VERSION "dbc-export 1 2025.20.8"

NS_ :

BS_:

BU_: ADSP APB APP APS APSB BB BMS CC CMP CP DAS DI DIF DIR DPB EPAS3P EPAS3S EPASTP EPASTS EPBL EPBR ESP GTW HVP IBST ICR IDB OCS1P PCS PM PMF PMR PTC RCM RCM2 RCU SCCM SDCR TAS TCU TRCM UI UIS UMC USM VC VCFRONT VCLEFT VCRIGHT VCSEC

BO_ 528 CP_status: 8 CP
 SG_ CP_type : 0|2@1+ (1,0) [0|3] "" Vector__XXX
 SG_ CP_insertEnableLine : 2|1@1+ (1,0) [0|1] "" Vector__XXX
 SG_ CP_latchState : 3|2@1+ (1,0) [1|3] "" Vector__XXX
 SG_ CP_permanentPowerRequest : 5|1@1+ (1,0) [0|1] "" Vector__XXX
 SG_ CP_chargeDoorOpen : 6|1@1+ (1,0) [0|1] "" Vector__XXX
 SG_ CP_doorControlState : 8|3@1+ (1,0) [0|7] "" Vector__XXX
 SG_ CP_doorButtonPressed : 11|1@1+ (1,0) [0|1] "" Vector__XXX
 SG_ CP_swcanRelayClosed : 12|1@1+ (1,0) [0|1] "" Vector__XXX
 SG_ CP_inhibitOta : 13|1@1+ (1,0) [0|1] "" Vector__XXX
 SG_ CP_chargeCableState : 14|2@1+ (1,0) [1|3] "" Vector__XXX
 SG_ CP_latchControlState : 16|3@1+ (1,0) [0|7] "" Vector__XXX
 SG_ CP_ledColor : 19|4@1+ (1,0) [0|15] "" Vector__XXX
 SG_ CP_UHF_handleFound : 23|1@1+ (1,0) [0|1] "" Vector__XXX
 SG_ CP_faultLineSensed : 24|1@1+ (1,0) [0|1] "" Vector__XXX
 SG_ CP_doorPresenceState : 25|3@1+ (1,0) [0|7] "" Vector__XXX
 SG_ CP_inductiveSensorState : 28|3@1+ (1,0) [0|7] "" Vector__XXX
 SG_ CP_chargeDoorOpenUI : 31|1@1+ (1,0) [0|1] "" Vector__XXX
 SG_ CP_vehicleUnlockRequest : 32|1@1+ (1,0) [0|1] "" Vector__XXX
 SG_ CP_coldWeatherMode : 33|1@1+ (1,0) [0|1] "" Vector__XXX
 SG_ CP_hvInletExposed : 34|1@1+ (1,0) [0|1] "" Vector__XXX
 SG_ CP_latchEngaged : 35|1@1+ (1,0) [0|1] "" Vector__XXX
 SG_ CP_inletHeaterUiState : 40|3@1+ (1,0) [0|7] "" Vector__XXX

BO_ 893 CP_thermalStatus: 8 CP
 SG_ CP_thermalStatusSelect M : 0|1@1+ (1,0) [0|1] "" Vector__XXX
 SG_ CP_pinTemperature1 m1 : 8|8@1+ (0.8039216,-55) [-55|149.99] "C" Vector__XXX
 SG_ CP_pinTemperature2 m1 : 16|8@1+ (0.8039216,-55) [-55|149.99] "C" Vector__XXX
 SG_ CP_pinTemperature3 m1 : 24|8@1+ (0.8039216,-55) [-55|149.99] "C" Vector__XXX

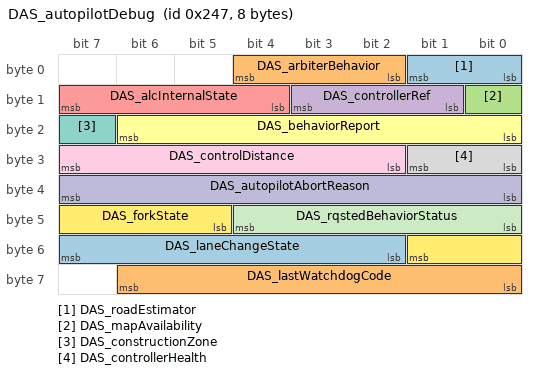
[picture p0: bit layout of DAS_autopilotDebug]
BO_ 583 DAS_autopilotDebug: 8 DAS
 SG_ DAS_roadEstimator : 0|2@1+ (1,0) [0|3] "" Vector__XXX
 SG_ DAS_arbiterBehavior : 2|3@1+ (1,0) [0|7] "" Vector__XXX
 SG_ DAS_mapAvailability : 8|1@1+ (1,0) [0|1] "" Vector__XXX
 SG_ DAS_controllerRef : 9|3@1+ (1,0) [0|7] "" Vector__XXX
 SG_ DAS_alcInternalState : 12|4@1+ (1,0) [0|15] "" Vector__XXX
 SG_ DAS_behaviorReport : 16|7@1+ (1,0) [0|127] "" Vector__XXX
 SG_ DAS_constructionZone : 23|1@1+ (1,0) [0|1] "" Vector__XXX
 SG_ DAS_controllerHealth : 24|2@1+ (1,0) [0|3] "" Vector__XXX
 SG_ DAS_controlDistance : 26|6@1+ (2,0) [0|126] "m" Vector__XXX
 SG_ DAS_autopilotAbortReason : 32|8@1+ (1,0) [0|255] "" Vector__XXX
 SG_ DAS_rqstedBehaviorStatus : 40|5@1+ (1,0) [0|31] "" Vector__XXX
 SG_ DAS_forkState : 45|5@1+ (1,0) [0|31] "" Vector__XXX
 SG_ DAS_laneChangeState : 50|6@1+ (1,0) [0|63] "" Vector__XXX
 SG_ DAS_lastWatchdogCode : 56|7@1+ (1,0) [0|127] "" Vector__XXX

BO_ 2041 DAS_gpsStatus: 8 DAS
 SG_ DAS_gpsStatusMultiplexer M : 0|4@1+ (1,0) [0|15] "" Vector__XXX
 SG_ DAS_gpsTransportModeState m0 : 4|1@1+ (1,0) [0|1] "" Vector__XXX
 SG_ DAS_gpsSatsInUseHardware m0 : 5|4@1+ (1,0) [0|15] "" Vector__XXX
 SG_ DAS_gpsWheeltickCounter m0 : 9|16@1+ (1,0) [0|65535] "" Vector__XXX
 SG_ DAS_gpsWheeltickPulsePeriod m0 : 25|32@1+ (1,0) [0|4294967295] "" Vector__XXX
 SG_ DAS_gpsRejectingSatData m0 : 57|1@1+ (1,0) [0|1] "" Vector__XXX
 SG_ DAS_gpsWheelsOffMotionDetected m0 : 58|1@1+ (1,0) [0|1] "" Vector__XXX
 SG_ DAS_gpsFixTypeHardware m0 : 59|3@1+ (1,0) [0|7] "" Vector__XXX
 SG_ DAS_gpsRawxEnabled m0 : 62|1@1+ (1,0) [0|1] "" Vector__XXX
 SG_ DAS_gpsRxmRawxMia m1 : 4|1@1+ (1,0) [0|1] "" Vector__XXX
 SG_ DAS_gpsRxmSfrbxMia m1 : 5|1@1+ (1,0) [0|1] "" Vector__XXX
 SG_ DAS_gpsEsfMeasMia m1 : 6|1@1+ (1,0) [0|1] "" Vector__XXX
 SG_ DAS_gpsEsfRawMia m1 : 7|1@1+ (1,0) [0|1] "" Vector__XXX
 SG_ DAS_gpsNavStatusMia m1 : 8|1@1+ (1,0) [0|1] "" Vector__XXX
 SG_ DAS_gpsSoftwareConfigured m1 : 9|1@1+ (1,0) [0|1] "" Vector__XXX
 SG_ DAS_gpsSoftwareUsed m1 : 10|1@1+ (1,0) [0|1] "" Vector__XXX
 SG_ DAS_gpsSoftwareFastStartReady m1 : 11|1@1+ (1,0) [0|1] "" Vector__XXX
 SG_ DAS_gpsSatsInUseSoftware m1 : 12|4@1+ (1,0) [0|15] "" Vector__XXX
 SG_ DAS_gpsFixTypeSoftware m1 : 16|3@1+ (1,0) [0|7] "" Vector__XXX
 SG_ DAS_gpsCWJammingInidcator m1 : 19|5@1+ (8,0) [0|248] "-" Vector__XXX
 SG_ DAS_gpsJammingState m1 : 24|2@1+ (1,0) [0|3] "" Vector__XXX
 SG_ DAS_gpsSpoofDetectorState m1 : 26|2@1+ (1,0) [0|3] "" Vector__XXX
 SG_ DAS_gpsInvalidMsgPercentage m1 : 28|4@1+ (6,0) [0|90] "%" Vector__XXX
 SG_ DAS_gnssConstellationsState m1 : 32|2@1+ (1,0) [0|3] "" Vector__XXX
 SG_ DAS_gpsReceiverNoiseLevel m1 : 34|6@1+ (8,0) [0|504] "-" Vector__XXX
 SG_ DAS_gpsAutomaticGainControl m1 : 40|8@1+ (32,0) [0|8160] "-" Vector__XXX
 SG_ DAS_gpsPreviousPositionDeltaHw m1 : 48|6@1+ (3,0) [0|189] "m" Vector__XXX
 SG_ DAS_gpsPreviousPositionDeltaSw m1 : 54|6@1+ (3,0) [0|189] "m" Vector__XXX
 SG_ DAS_gpsNmeaDispatchFailureCount m1 : 60|4@1+ (5,0) [0|75] "-" Vector__XXX
 SG_ DAS_gnssMaxInstantaneousCnorGps m2 : 4|6@1+ (1,0) [0|63] "" Vector__XXX
 SG_ DAS_gnssMaxInstantaneousCnorGal m2 : 10|6@1+ (1,0) [0|63] "" Vector__XXX
 SG_ DAS_gnssMaxInstantaneousCnorBds m2 : 16|6@1+ (1,0) [0|63] "" Vector__XXX
 SG_ DAS_gpsResetReason m2 : 22|4@1+ (1,0) [0|15] "" Vector__XXX
 SG_ DAS_gpsAccuracyHorizontal m2 : 26|6@1+ (1,0) [0|63] "m" Vector__XXX
 SG_ DAS_gpsAccuracyVertical m2 : 32|6@1+ (1,0) [0|63] "m" Vector__XXX
 SG_ DAS_gpsSolutionFallback m2 : 38|1@1+ (1,0) [0|1] "" Vector__XXX
 SG_ DAS_gpsToMcuSource m2 : 39|3@1+ (1,0) [0|7] "" Vector__XXX
 SG_ DAS_gpsSolutionSoc m2 : 42|2@1+ (1,0) [0|3] "" Vector__XXX
 SG_ DAS_gpsRedundancyActive m2 : 44|1@1+ (1,0) [0|1] "" Vector__XXX
 SG_ DAS_gpsFixTypeSoftwareSocB m2 : 45|3@1+ (1,0) [0|7] "" Vector__XXX
 SG_ DAS_gpsSatsInUseSoftwareSocB m2 : 48|4@1+ (1,0) [0|15] "" Vector__XXX
 SG_ DAS_gnssNumSatsGps m3 : 4|4@1+ (1,0) [0|15] "" Vector__XXX
 SG_ DAS_gnssNumSatsGal m3 : 8|4@1+ (1,0) [0|15] "" Vector__XXX
 SG_ DAS_gnssNumSatsBds m3 : 12|4@1+ (1,0) [0|15] "" Vector__XXX
 SG_ DAS_gnssAvgInstantaneousCnorGps m3 : 16|6@1+ (1,0) [0|63] "" Vector__XXX
 SG_ DAS_gnssAvgInstantaneousCnorGal m3 : 22|6@1+ (1,0) [0|63] "" Vector__XXX
 SG_ DAS_gnssAvgInstantaneousCnorBds m3 : 28|6@1+ (1,0) [0|63] "" Vector__XXX
 SG_ DAS_gnssAvgInstantCnorGpsSocB m3 : 34|6@1+ (1,0) [0|63] "" Vector__XXX
 SG_ DAS_gnssAvgInstantCnorBdsSocB m3 : 40|6@1+ (1,0) [0|63] "" Vector__XXX
 SG_ DAS_gnssAvgInstantaneousCnorGpsL m3 : 46|6@1+ (1,0) [0|63] "" Vector__XXX
 SG_ DAS_gnssAvgInstantaneousCnorGalL m3 : 52|6@1+ (1,0) [0|63] "" Vector__XXX
 SG_ DAS_gnssAvgInstantaneousCnorBdsL m3 : 58|6@1+ (1,0) [0|63] "" Vector__XXX

BO_ 777 DAS_object: 8 DAS
 SG_ DAS_objectId M : 0|3@1+ (1,0) [0|7] "" Vector__XXX
 SG_ DAS_leadVehType m0 : 3|3@1+ (1,0) [0|7] "" Vector__XXX
 SG_ DAS_leadVehRelevantForControl m0 : 7|1@1+ (1,0) [0|1] "" Vector__XXX
 SG_ DAS_leadVehDx m0 : 8|8@1+ (0.5,0) [0|127] "m" Vector__XXX
 SG_ DAS_leadVehVxRel m0 : 16|4@1+ (4,-30) [-30|26] "m/s" Vector__XXX
 SG_ DAS_leadVehDy m0 : 20|7@1+ (0.35,-22.05) [-22.05|22.4] "m" Vector__XXX
 SG_ DAS_leadVehId m0 : 27|7@1+ (1,0) [0|126] "" Vector__XXX
 SG_ DAS_leadVeh2Type m0 : 34|3@1+ (1,0) [0|7] "" Vector__XXX
 SG_ DAS_leadVeh2RelevantForControl m0 : 38|1@1+ (1,0) [0|1] "" Vector__XXX
 SG_ DAS_leadVeh2Dx m0 : 39|8@1+ (0.5,0) [0|127] "m" Vector__XXX
 SG_ DAS_leadVeh2VxRel m0 : 47|4@1+ (4,-30) [-30|26] "m/s" Vector__XXX
 SG_ DAS_leadVeh2Dy m0 : 51|7@1+ (0.35,-22.05) [-22.05|22.4] "m" Vector__XXX
 SG_ DAS_leadVeh2Id m0 : 58|6@1+ (1,0) [1|63] "" Vector__XXX
 SG_ DAS_leftVehType m1 : 3|3@1+ (1,0) [0|7] "" Vector__XXX
 SG_ DAS_leftVehRelevantForControl m1 : 7|1@1+ (1,0) [0|1] "" Vector__XXX
 SG_ DAS_leftVehDx m1 : 8|8@1+ (0.5,0) [0|127] "m" Vector__XXX
 SG_ DAS_leftVehVxRel m1 : 16|4@1+ (4,-30) [-30|26] "m/s" Vector__XXX
 SG_ DAS_leftVehDy m1 : 20|7@1+ (0.35,-22.05) [-22.05|22.4] "m" Vector__XXX
 SG_ DAS_leftVehId m1 : 27|7@1+ (1,0) [0|126] "" Vector__XXX
 SG_ DAS_leftVeh2Type m1 : 34|3@1+ (1,0) [0|7] "" Vector__XXX
 SG_ DAS_leftVeh2RelevantForControl m1 : 38|1@1+ (1,0) [0|1] "" Vector__XXX
 SG_ DAS_leftVeh2Dx m1 : 39|8@1+ (0.5,0) [0|127] "m" Vector__XXX
 SG_ DAS_leftVeh2VxRel m1 : 47|4@1+ (4,-30) [-30|26] "m/s" Vector__XXX
 SG_ DAS_leftVeh2Dy m1 : 51|7@1+ (0.35,-22.05) [-22.05|22.4] "m" Vector__XXX
 SG_ DAS_leftVeh2Id m1 : 58|6@1+ (1,0) [1|63] "" Vector__XXX
 SG_ DAS_rightVehType m2 : 3|3@1+ (1,0) [0|7] "" Vector__XXX
 SG_ DAS_rightVehRelevantForControl m2 : 7|1@1+ (1,0) [0|1] "" Vector__XXX
 SG_ DAS_rightVehDx m2 : 8|8@1+ (0.5,0) [0|127] "m" Vector__XXX
 SG_ DAS_rightVehVxRel m2 : 16|4@1+ (4,-30) [-30|26] "m/s" Vector__XXX
 SG_ DAS_rightVehDy m2 : 20|7@1+ (0.35,-22.05) [-22.05|22.4] "m" Vector__XXX
 SG_ DAS_rightVehId m2 : 27|7@1+ (1,0) [0|126] "" Vector__XXX
 SG_ DAS_rightVeh2Type m2 : 34|3@1+ (1,0) [0|7] "" Vector__XXX
 SG_ DAS_rightVeh2RelevantForControl m2 : 38|1@1+ (1,0) [0|1] "" Vector__XXX
 SG_ DAS_rightVeh2Dx m2 : 39|8@1+ (0.5,0) [0|127] "m" Vector__XXX
 SG_ DAS_rightVeh2VxRel m2 : 47|4@1+ (4,-30) [-30|26] "m/s" Vector__XXX
 SG_ DAS_rightVeh2Dy m2 : 51|7@1+ (0.35,-22.05) [-22.05|22.4] "m" Vector__XXX
 SG_ DAS_rightVeh2Id m2 : 58|6@1+ (1,0) [1|63] "" Vector__XXX
 SG_ DAS_cutinVehType m3 : 3|3@1+ (1,0) [0|7] "" Vector__XXX
 SG_ DAS_cutinVehRelevantForControl m3 : 7|1@1+ (1,0) [0|1] "" Vector__XXX
 SG_ DAS_cutinVehDx m3 : 8|8@1+ (0.5,0) [0|127] "m" Vector__XXX
 SG_ DAS_cutinVehVxRel m3 : 16|4@1+ (4,-30) [-30|26] "m/s" Vector__XXX
 SG_ DAS_cutinVehDy m3 : 20|7@1+ (0.35,-22.05) [-22.05|22.4] "m" Vector__XXX
 SG_ DAS_cutinVehId m3 : 27|7@1+ (1,0) [0|126] "" Vector__XXX
 SG_ DAS_roadSignColor m4 : 3|3@1+ (1,0) [0|7] "" Vector__XXX
 SG_ DAS_roadSignId m4 : 6|8@1+ (1,0) [0|254] "" Vector__XXX
 SG_ DAS_roadSignStopLineDist m4 : 14|10@1+ (0.2,-20) [-20|184.4] "m" Vector__XXX
 SG_ DAS_roadSignControlActive m4 : 24|1@1+ (1,0) [0|1] "" Vector__XXX
 SG_ DAS_roadSignSource m4 : 25|2@1+ (1,0) [0|3] "" Vector__XXX
 SG_ DAS_roadSignArrow m4 : 27|3@1+ (1,0) [0|7] "" Vector__XXX
 SG_ DAS_roadSignOrientation m4 : 30|2@1+ (1,0) [0|3] "" Vector__XXX

BO_ 1548 DAS_telemetryRadar: 8 DAS
 SG_ DAS_TR_ObjIndex M : 0|5@1+ (1,0) [0|31] "" Vector__XXX
 SG_ DAS_TR_Counter : 54|2@1+ (1,0) [0|3] "" Vector__XXX
 SG_ DAS_TR_Obj00_Class m0 : 5|3@1+ (1,0) [0|7] "" Vector__XXX
 SG_ DAS_TR_Obj00_Dx m0 : 8|10@1+ (0.15625,0) [0|159.84375] "m" Vector__XXX
 SG_ DAS_TR_Obj00_Dy m0 : 18|6@1+ (0.5,-15.5) [-15.5|16] "m" Vector__XXX
 SG_ DAS_TR_Obj00_Vx m0 : 24|8@1+ (0.5,-63.5) [-63.5|64] "m/s" Vector__XXX
 SG_ DAS_TR_Obj00_RCS m0 : 32|8@1+ (0.25,-14) [-14|49.75] "dB" Vector__XXX
 SG_ DAS_TR_Obj00_Length m0 : 40|6@1+ (0.125,0) [0|7.875] "m" Vector__XXX
 SG_ DAS_TR_Obj00_MovingState m0 : 46|2@1+ (1,0) [0|3] "" Vector__XXX
 SG_ DAS_TR_Obj00_Dz m0 : 48|6@1+ (0.25,-5) [-5|10.75] "m" Vector__XXX
 SG_ DAS_TR_Obj00_Exist m0 : 56|5@1+ (3.125,0) [0|96.875] "%" Vector__XXX

BO_ 1318 DIF_alertLog: 8 DIF
 SG_ DIF_alertID M : 0|8@1+ (1,0) [0|255] "" Vector__XXX
 SG_ DIF_alertState : 15|1@1+ (1,0) [0|1] "" Vector__XXX
 SG_ DIF_a001_thermalWarning_H m1 : 16|1@1+ (1,0) [0|1] "" Vector__XXX
 SG_ DIF_a001_thermalShutdown_H m1 : 17|1@1+ (1,0) [0|1] "" Vector__XXX
 SG_ DIF_a001_undervoltVL_H m1 : 18|1@1+ (1,0) [0|1] "" Vector__XXX
 SG_ DIF_a001_undervoltVH_H m1 : 19|1@1+ (1,0) [0|1] "" Vector__XXX
 SG_ DIF_a001_sense_H m1 : 20|1@1+ (1,0) [0|1] "" Vector__XXX
 SG_ DIF_a001_desat_H m1 : 21|1@1+ (1,0) [0|1] "" Vector__XXX
 SG_ DIF_a001_overvoltVL_H m1 : 22|1@1+ (1,0) [0|1] "" Vector__XXX
 SG_ DIF_a001_overvoltVH_H m1 : 23|1@1+ (1,0) [0|1] "" Vector__XXX
 SG_ DIF_a001_undervoltVCC_H m1 : 24|1@1+ (1,0) [0|1] "" Vector__XXX
 SG_ DIF_a001_asynchStop_H m1 : 25|1@1+ (1,0) [0|1] "" Vector__XXX
 SG_ DIF_a001_remoteRegError_H m1 : 26|1@1+ (1,0) [0|1] "" Vector__XXX
 SG_ DIF_a001_undervoltVDD_H m1 : 27|1@1+ (1,0) [0|1] "" Vector__XXX
 SG_ DIF_a001_overvoltVDD_H m1 : 28|1@1+ (1,0) [0|1] "" Vector__XXX
 SG_ DIF_a001_localRegError_H m1 : 29|1@1+ (1,0) [0|1] "" Vector__XXX
 SG_ DIF_a001_spiError_H m1 : 30|1@1+ (1,0) [0|1] "" Vector__XXX
 SG_ DIF_a001_deadtimeError_H m1 : 31|1@1+ (1,0) [0|1] "" Vector__XXX
 SG_ DIF_a001_thermalWarning_L m1 : 32|1@1+ (1,0) [0|1] "" Vector__XXX
 SG_ DIF_a001_thermalShutdown_L m1 : 33|1@1+ (1,0) [0|1] "" Vector__XXX
 SG_ DIF_a001_undervoltVL_L m1 : 34|1@1+ (1,0) [0|1] "" Vector__XXX
 SG_ DIF_a001_undervoltVH_L m1 : 35|1@1+ (1,0) [0|1] "" Vector__XXX
 SG_ DIF_a001_sense_L m1 : 36|1@1+ (1,0) [0|1] "" Vector__XXX
 SG_ DIF_a001_desat_L m1 : 37|1@1+ (1,0) [0|1] "" Vector__XXX
 SG_ DIF_a001_overvoltVL_L m1 : 38|1@1+ (1,0) [0|1] "" Vector__XXX
 SG_ DIF_a001_overvoltVH_L m1 : 39|1@1+ (1,0) [0|1] "" Vector__XXX
 SG_ DIF_a001_undervoltVCC_L m1 : 40|1@1+ (1,0) [0|1] "" Vector__XXX
 SG_ DIF_a001_asynchStop_L m1 : 41|1@1+ (1,0) [0|1] "" Vector__XXX
 SG_ DIF_a001_remoteRegError_L m1 : 42|1@1+ (1,0) [0|1] "" Vector__XXX
 SG_ DIF_a001_undervoltVDD_L m1 : 43|1@1+ (1,0) [0|1] "" Vector__XXX
 SG_ DIF_a001_overvoltVDD_L m1 : 44|1@1+ (1,0) [0|1] "" Vector__XXX
 SG_ DIF_a001_localRegError_L m1 : 45|1@1+ (1,0) [0|1] "" Vector__XXX
 SG_ DIF_a001_spiError_L m1 : 46|1@1+ (1,0) [0|1] "" Vector__XXX
 SG_ DIF_a001_deadtimeError_L m1 : 47|1@1+ (1,0) [0|1] "" Vector__XXX
 SG_ DIF_a001_gateDriveErrCounter m1 : 48|4@1+ (1,0) [0|15] "" Vector__XXX
 SG_ DIF_a001_remoteCommError_H m1 : 52|1@1+ (1,0) [0|1] "" Vector__XXX
 SG_ DIF_a001_localCommError_H m1 : 53|1@1+ (1,0) [0|1] "" Vector__XXX
 SG_ DIF_a001_remoteReset_H m1 : 54|1@1+ (1,0) [0|1] "" Vector__XXX
 SG_ DIF_a001_localReset_H m1 : 55|1@1+ (1,0) [0|1] "" Vector__XXX
 SG_ DIF_a001_remoteCommError_L m1 : 56|1@1+ (1,0) [0|1] "" Vector__XXX
 SG_ DIF_a001_localCommError_L m1 : 57|1@1+ (1,0) [0|1] "" Vector__XXX
 SG_ DIF_a001_remoteReset_L m1 : 58|1@1+ (1,0) [0|1] "" Vector__XXX
 SG_ DIF_a001_localReset_L m1 : 59|1@1+ (1,0) [0|1] "" Vector__XXX
 SG_ DIF_a001_faultLine1Gpio_H m1 : 60|1@1+ (1,0) [0|1] "" Vector__XXX
 SG_ DIF_a001_faultLine1Gpio_L m1 : 61|1@1+ (1,0) [0|1] "" Vector__XXX
 SG_ DIF_a002_thermalWarning_H m2 : 16|1@1+ (1,0) [0|1] "" Vector__XXX
 SG_ DIF_a002_thermalShutdown_H m2 : 17|1@1+ (1,0) [0|1] "" Vector__XXX
 SG_ DIF_a002_undervoltVL_H m2 : 18|1@1+ (1,0) [0|1] "" Vector__XXX
 SG_ DIF_a002_undervoltVH_H m2 : 19|1@1+ (1,0) [0|1] "" Vector__XXX
 SG_ DIF_a002_sense_H m2 : 20|1@1+ (1,0) [0|1] "" Vector__XXX
 SG_ DIF_a002_desat_H m2 : 21|1@1+ (1,0) [0|1] "" Vector__XXX
 SG_ DIF_a002_overvoltVL_H m2 : 22|1@1+ (1,0) [0|1] "" Vector__XXX
 SG_ DIF_a002_overvoltVH_H m2 : 23|1@1+ (1,0) [0|1] "" Vector__XXX
 SG_ DIF_a002_undervoltVCC_H m2 : 24|1@1+ (1,0) [0|1] "" Vector__XXX
 SG_ DIF_a002_asynchStop_H m2 : 25|1@1+ (1,0) [0|1] "" Vector__XXX
 SG_ DIF_a002_remoteRegError_H m2 : 26|1@1+ (1,0) [0|1] "" Vector__XXX
 SG_ DIF_a002_undervoltVDD_H m2 : 27|1@1+ (1,0) [0|1] "" Vector__XXX
 SG_ DIF_a002_overvoltVDD_H m2 : 28|1@1+ (1,0) [0|1] "" Vector__XXX
 SG_ DIF_a002_localRegError_H m2 : 29|1@1+ (1,0) [0|1] "" Vector__XXX
 SG_ DIF_a002_spiError_H m2 : 30|1@1+ (1,0) [0|1] "" Vector__XXX
 SG_ DIF_a002_deadtimeError_H m2 : 31|1@1+ (1,0) [0|1] "" Vector__XXX
 SG_ DIF_a002_thermalWarning_L m2 : 32|1@1+ (1,0) [0|1] "" Vector__XXX
 SG_ DIF_a002_thermalShutdown_L m2 : 33|1@1+ (1,0) [0|1] "" Vector__XXX
 SG_ DIF_a002_undervoltVL_L m2 : 34|1@1+ (1,0) [0|1] "" Vector__XXX
 SG_ DIF_a002_undervoltVH_L m2 : 35|1@1+ (1,0) [0|1] "" Vector__XXX
 SG_ DIF_a002_sense_L m2 : 36|1@1+ (1,0) [0|1] "" Vector__XXX
 SG_ DIF_a002_desat_L m2 : 37|1@1+ (1,0) [0|1] "" Vector__XXX
 SG_ DIF_a002_overvoltVL_L m2 : 38|1@1+ (1,0) [0|1] "" Vector__XXX
 SG_ DIF_a002_overvoltVH_L m2 : 39|1@1+ (1,0) [0|1] "" Vector__XXX
 SG_ DIF_a002_undervoltVCC_L m2 : 40|1@1+ (1,0) [0|1] "" Vector__XXX
 SG_ DIF_a002_asynchStop_L m2 : 41|1@1+ (1,0) [0|1] "" Vector__XXX
 SG_ DIF_a002_remoteRegError_L m2 : 42|1@1+ (1,0) [0|1] "" Vector__XXX
 SG_ DIF_a002_undervoltVDD_L m2 : 43|1@1+ (1,0) [0|1] "" Vector__XXX
 SG_ DIF_a002_overvoltVDD_L m2 : 44|1@1+ (1,0) [0|1] "" Vector__XXX
 SG_ DIF_a002_localRegError_L m2 : 45|1@1+ (1,0) [0|1] "" Vector__XXX
 SG_ DIF_a002_spiError_L m2 : 46|1@1+ (1,0) [0|1] "" Vector__XXX
 SG_ DIF_a002_deadtimeError_L m2 : 47|1@1+ (1,0) [0|1] "" Vector__XXX
 SG_ DIF_a002_gateDriveErrCounter m2 : 48|4@1+ (1,0) [0|15] "" Vector__XXX
 SG_ DIF_a002_selftestDesat_L m2 : 52|1@1+ (1,0) [0|1] "" Vector__XXX
 SG_ DIF_a002_selftestDesat_H m2 : 53|1@1+ (1,0) [0|1] "" Vector__XXX
 SG_ DIF_a002_remoteCommError_H m2 : 54|1@1+ (1,0) [0|1] "" Vector__XXX
 SG_ DIF_a002_localCommError_H m2 : 55|1@1+ (1,0) [0|1] "" Vector__XXX
 SG_ DIF_a002_remoteReset_H m2 : 56|1@1+ (1,0) [0|1] "" Vector__XXX
 SG_ DIF_a002_localReset_H m2 : 57|1@1+ (1,0) [0|1] "" Vector__XXX
 SG_ DIF_a002_remoteCommError_L m2 : 58|1@1+ (1,0) [0|1] "" Vector__XXX
 SG_ DIF_a002_localCommError_L m2 : 59|1@1+ (1,0) [0|1] "" Vector__XXX
 SG_ DIF_a002_remoteReset_L m2 : 60|1@1+ (1,0) [0|1] "" Vector__XXX
 SG_ DIF_a002_localReset_L m2 : 61|1@1+ (1,0) [0|1] "" Vector__XXX
 SG_ DIF_a002_faultLine1Gpio_H m2 : 62|1@1+ (1,0) [0|1] "" Vector__XXX
 SG_ DIF_a002_faultLine1Gpio_L m2 : 63|1@1+ (1,0) [0|1] "" Vector__XXX
 SG_ DIF_a003_thermalWarning_H m3 : 16|1@1+ (1,0) [0|1] "" Vector__XXX
 SG_ DIF_a003_thermalShutdown_H m3 : 17|1@1+ (1,0) [0|1] "" Vector__XXX
 SG_ DIF_a003_undervoltVL_H m3 : 18|1@1+ (1,0) [0|1] "" Vector__XXX
 SG_ DIF_a003_undervoltVH_H m3 : 19|1@1+ (1,0) [0|1] "" Vector__XXX
 SG_ DIF_a003_sense_H m3 : 20|1@1+ (1,0) [0|1] "" Vector__XXX
 SG_ DIF_a003_desat_H m3 : 21|1@1+ (1,0) [0|1] "" Vector__XXX
 SG_ DIF_a003_overvoltVL_H m3 : 22|1@1+ (1,0) [0|1] "" Vector__XXX
 SG_ DIF_a003_overvoltVH_H m3 : 23|1@1+ (1,0) [0|1] "" Vector__XXX
 SG_ DIF_a003_undervoltVCC_H m3 : 24|1@1+ (1,0) [0|1] "" Vector__XXX
 SG_ DIF_a003_asynchStop_H m3 : 25|1@1+ (1,0) [0|1] "" Vector__XXX
 SG_ DIF_a003_remoteRegError_H m3 : 26|1@1+ (1,0) [0|1] "" Vector__XXX
 SG_ DIF_a003_undervoltVDD_H m3 : 27|1@1+ (1,0) [0|1] "" Vector__XXX
 SG_ DIF_a003_overvoltVDD_H m3 : 28|1@1+ (1,0) [0|1] "" Vector__XXX
 SG_ DIF_a003_localRegError_H m3 : 29|1@1+ (1,0) [0|1] "" Vector__XXX
 SG_ DIF_a003_spiError_H m3 : 30|1@1+ (1,0) [0|1] "" Vector__XXX
 SG_ DIF_a003_deadtimeError_H m3 : 31|1@1+ (1,0) [0|1] "" Vector__XXX
 SG_ DIF_a003_thermalWarning_L m3 : 32|1@1+ (1,0) [0|1] "" Vector__XXX
 SG_ DIF_a003_thermalShutdown_L m3 : 33|1@1+ (1,0) [0|1] "" Vector__XXX
 SG_ DIF_a003_undervoltVL_L m3 : 34|1@1+ (1,0) [0|1] "" Vector__XXX
 SG_ DIF_a003_undervoltVH_L m3 : 35|1@1+ (1,0) [0|1] "" Vector__XXX
 SG_ DIF_a003_sense_L m3 : 36|1@1+ (1,0) [0|1] "" Vector__XXX
 SG_ DIF_a003_desat_L m3 : 37|1@1+ (1,0) [0|1] "" Vector__XXX
 SG_ DIF_a003_overvoltVL_L m3 : 38|1@1+ (1,0) [0|1] "" Vector__XXX
 SG_ DIF_a003_overvoltVH_L m3 : 39|1@1+ (1,0) [0|1] "" Vector__XXX
 SG_ DIF_a003_undervoltVCC_L m3 : 40|1@1+ (1,0) [0|1] "" Vector__XXX
 SG_ DIF_a003_asynchStop_L m3 : 41|1@1+ (1,0) [0|1] "" Vector__XXX
 SG_ DIF_a003_remoteRegError_L m3 : 42|1@1+ (1,0) [0|1] "" Vector__XXX
 SG_ DIF_a003_undervoltVDD_L m3 : 43|1@1+ (1,0) [0|1] "" Vector__XXX
 SG_ DIF_a003_overvoltVDD_L m3 : 44|1@1+ (1,0) [0|1] "" Vector__XXX
 SG_ DIF_a003_localRegError_L m3 : 45|1@1+ (1,0) [0|1] "" Vector__XXX
 SG_ DIF_a003_spiError_L m3 : 46|1@1+ (1,0) [0|1] "" Vector__XXX
 SG_ DIF_a003_deadtimeError_L m3 : 47|1@1+ (1,0) [0|1] "" Vector__XXX
 SG_ DIF_a003_gateDriveErrCounter m3 : 48|4@1+ (1,0) [0|15] "" Vector__XXX
 SG_ DIF_a003_selftestDesat_L m3 : 52|1@1+ (1,0) [0|1] "" Vector__XXX
 SG_ DIF_a003_selftestDesat_H m3 : 53|1@1+ (1,0) [0|1] "" Vector__XXX
 SG_ DIF_a003_remoteCommError_H m3 : 54|1@1+ (1,0) [0|1] "" Vector__XXX
 SG_ DIF_a003_localCommError_H m3 : 55|1@1+ (1,0) [0|1] "" Vector__XXX
 SG_ DIF_a003_remoteReset_H m3 : 56|1@1+ (1,0) [0|1] "" Vector__XXX
 SG_ DIF_a003_localReset_H m3 : 57|1@1+ (1,0) [0|1] "" Vector__XXX
 SG_ DIF_a003_remoteCommError_L m3 : 58|1@1+ (1,0) [0|1] "" Vector__XXX
 SG_ DIF_a003_localCommError_L m3 : 59|1@1+ (1,0) [0|1] "" Vector__XXX
 SG_ DIF_a003_remoteReset_L m3 : 60|1@1+ (1,0) [0|1] "" Vector__XXX
 SG_ DIF_a003_localReset_L m3 : 61|1@1+ (1,0) [0|1] "" Vector__XXX
 SG_ DIF_a003_faultLine1Gpio_H m3 : 62|1@1+ (1,0) [0|1] "" Vector__XXX
 SG_ DIF_a003_faultLine1Gpio_L m3 : 63|1@1+ (1,0) [0|1] "" Vector__XXX
 SG_ DIF_a007_phaseAcurrent m7 : 16|8@1+ (8,0) [0|2040] "A" Vector__XXX
 SG_ DIF_a007_phaseBcurrent m7 : 24|8@1+ (8,0) [0|2040] "A" Vector__XXX
 SG_ DIF_a007_offsetError m7 : 32|14@1- (0.0003834952,0) [-3.1415926784|3.1412091832] "rad" Vector__XXX
 SG_ DIF_a007_idFdbStdDeviation m7 : 46|8@1+ (4,0) [0|1020] "A" Vector__XXX
 SG_ DIF_a007_iqFdbStdDeviation m7 : 54|8@1+ (4,0) [0|1020] "A" Vector__XXX
 SG_ DIF_a007_motorShift m7 : 62|1@1+ (1,0) [0|1] "" Vector__XXX
 SG_ DIF_a007_motorShort m7 : 63|1@1+ (1,0) [0|1] "" Vector__XXX
 SG_ DIF_a010_sccReset m10 : 16|1@1+ (1,0) [0|1] "" Vector__XXX
 SG_ DIF_a010_hibernate m10 : 17|1@1+ (1,0) [0|1] "" Vector__XXX
 SG_ DIF_a010_hwBist m10 : 18|1@1+ (1,0) [0|1] "" Vector__XXX
 SG_ DIF_a010_nmiWatchdog m10 : 19|1@1+ (1,0) [0|1] "" Vector__XXX
 SG_ DIF_a010_watchdog m10 : 20|1@1+ (1,0) [0|1] "" Vector__XXX
 SG_ DIF_a010_clockFailNmi m10 : 21|1@1+ (1,0) [0|1] "" Vector__XXX
 SG_ DIF_a010_ramUncErrorNmi m10 : 22|1@1+ (1,0) [0|1] "" Vector__XXX
 SG_ DIF_a010_flashUncErrorNmi m10 : 23|1@1+ (1,0) [0|1] "" Vector__XXX
 SG_ DIF_a010_cpu1signMismatchNmi m10 : 24|1@1+ (1,0) [0|1] "" Vector__XXX
 SG_ DIF_a010_cpu2signMismatchNmi m10 : 25|1@1+ (1,0) [0|1] "" Vector__XXX
 SG_ DIF_a010_pieVectErrorNmi m10 : 26|1@1+ (1,0) [0|1] "" Vector__XXX
 SG_ DIF_a010_sysDbgNmi m10 : 27|1@1+ (1,0) [0|1] "" Vector__XXX
 SG_ DIF_a010_rlNmi m10 : 28|1@1+ (1,0) [0|1] "" Vector__XXX
 SG_ DIF_a010_ovfNmi m10 : 29|1@1+ (1,0) [0|1] "" Vector__XXX
 SG_ DIF_a010_wdtFlags m10 : 32|16@1+ (1,0) [0|65535] "" Vector__XXX
 SG_ DIF_a011_reason m11 : 16|3@1+ (1,0) [0|7] "" Vector__XXX
 SG_ DIF_a011_phaseAHigh m11 : 19|1@1+ (1,0) [0|1] "" Vector__XXX
 SG_ DIF_a011_phaseALow m11 : 20|1@1+ (1,0) [0|1] "" Vector__XXX
 SG_ DIF_a011_phaseBHigh m11 : 21|1@1+ (1,0) [0|1] "" Vector__XXX
 SG_ DIF_a011_phaseBLow m11 : 22|1@1+ (1,0) [0|1] "" Vector__XXX
 SG_ DIF_a011_phaseCHigh m11 : 23|1@1+ (1,0) [0|1] "" Vector__XXX
 SG_ DIF_a011_phaseCLow m11 : 24|1@1+ (1,0) [0|1] "" Vector__XXX
 SG_ DIF_a011_regAddress m11 : 25|5@1+ (1,0) [0|31] "" Vector__XXX
 SG_ DIF_a011_badGateDriveIC m11 : 32|3@1+ (1,0) [0|7] "" Vector__XXX
 SG_ DIF_a011_badDataRead m11 : 40|8@1+ (1,0) [0|255] "" Vector__XXX
 SG_ DIF_a011_badDataExpected m11 : 48|8@1+ (1,0) [0|255] "" Vector__XXX
 SG_ DIF_a011_codeBranch m11 : 56|4@1+ (1,0) [0|15] "" Vector__XXX
 SG_ DIF_a012_hvilStatus m12 : 16|2@1+ (1,0) [0|2] "" Vector__XXX
 SG_ DIF_a012_hvilCmVoltage m12 : 24|8@1+ (0.08,0) [0|20.4] "V" Vector__XXX
 SG_ DIF_a012_hvilCurrent m12 : 32|8@1+ (0.1,0) [0|25.5] "mA" Vector__XXX
 SG_ DIF_a012_hvilFaultGpio m12 : 40|1@1+ (1,0) [0|1] "" Vector__XXX
 SG_ DIF_a012_hvilSupplyPinDI m12 : 41|1@1+ (1,0) [0|1] "" Vector__XXX
 SG_ DIF_a012_hvilSupplyPinPM m12 : 42|1@1+ (1,0) [0|1] "" Vector__XXX
 SG_ DIF_a012_activeDisOn3V3 m12 : 43|1@1+ (1,0) [0|1] "" Vector__XXX
 SG_ DIF_a012_hvilHeaderFault m12 : 44|1@1+ (1,0) [0|1] "" Vector__XXX
 SG_ DIF_a013_address m13 : 16|32@1+ (1,0) [0|4294967295] "" Vector__XXX
 SG_ DIF_a013_errorType m13 : 48|4@1+ (1,0) [0|15] "" Vector__XXX
 SG_ DIF_a014_motorSpeed m14 : 16|14@1- (2,0) [-16384|16382] "RPM" Vector__XXX
 SG_ DIF_a014_adState m14 : 30|2@1+ (1,0) [0|3] "" Vector__XXX
 SG_ DIF_a014_torqueCommandFwd m14 : 32|10@1- (2,0) [-1024|1022] "Nm" Vector__XXX
 SG_ DIF_a014_brakeMasterCylPress m14 : 42|10@1+ (0.25,-42.5) [-42.5|213.25] "bar" Vector__XXX
 SG_ DIF_a014_rmsTorqueError m14 : 52|10@1+ (1,0) [0|1023] "Nm" Vector__XXX
 SG_ DIF_a014_tcEnabled m14 : 62|1@1+ (1,0) [0|1] "" Vector__XXX
 SG_ DIF_a016_newSafeState m16 : 16|2@1+ (1,0) [0|3] "" Vector__XXX
 SG_ DIF_a016_oldSafeState m16 : 18|2@1+ (1,0) [0|3] "" Vector__XXX
 SG_ DIF_a016_gateDriveFaultLine m16 : 20|1@1+ (1,0) [0|1] "" Vector__XXX
 SG_ DIF_a016_ascMonitor m16 : 21|1@1+ (1,0) [0|1] "" Vector__XXX
 SG_ DIF_a016_uncontrolledRegenZone m16 : 22|1@1+ (1,0) [0|1] "" Vector__XXX
 SG_ DIF_a016_pedalMonitorPreWatchdog m16 : 23|1@1+ (1,0) [0|1] "" Vector__XXX
 SG_ DIF_a016_motorRPM m16 : 24|16@1- (1,0) [-32768|32767] "RPM" Vector__XXX
 SG_ DIF_a016_torqueMotor m16 : 40|16@1- (1,0) [-32768|32767] "Nm" Vector__XXX
 SG_ DIF_a016_safetyICfaultLine m16 : 56|1@1+ (1,0) [0|1] "" Vector__XXX
 SG_ DIF_a016_triggerEvent m16 : 57|5@1+ (1,0) [0|31] "" Vector__XXX
 SG_ DIF_a024_vBat m24 : 16|8@1+ (2,0) [0|510] "V" Vector__XXX
 SG_ DIF_a024_failReason m24 : 24|3@1+ (1,0) [0|7] "" Vector__XXX
 SG_ DIF_a024_state m24 : 27|4@1+ (1,0) [0|15] "" Vector__XXX
 SG_ DIF_a024_Ia m24 : 31|7@1- (22.5,0) [-1440|1417.5] "A" Vector__XXX
 SG_ DIF_a024_Ib m24 : 38|7@1- (22.5,0) [-1440|1417.5] "A" Vector__XXX
 SG_ DIF_a024_maxCurrMagSqrd m24 : 45|12@1+ (500,0) [0|2047500] "A2" Vector__XXX
 SG_ DIF_a024_rotorAngle m24 : 57|7@1- (3,0) [-192|189] "degrees" Vector__XXX
 SG_ DIF_a025_Ia m25 : 16|16@1- (0.1,0) [-3276.8|3276.7] "A" Vector__XXX
 SG_ DIF_a025_torqueMotor m25 : 32|13@1- (0.25,0) [-1024|1023.75] "Nm" Vector__XXX
 SG_ DIF_a025_motorSpeed m25 : 48|16@1- (1,0) [-32768|32767] "RPM" Vector__XXX
 SG_ DIF_a026_Ib m26 : 16|16@1- (0.1,0) [-3276.8|3276.7] "A" Vector__XXX
 SG_ DIF_a026_torqueMotor m26 : 32|13@1- (0.25,0) [-1024|1023.75] "Nm" Vector__XXX
 SG_ DIF_a026_motorSpeed m26 : 48|16@1- (1,0) [-32768|32767] "RPM" Vector__XXX
 SG_ DIF_a027_Ic m27 : 16|16@1- (0.1,0) [-3276.8|3276.7] "A" Vector__XXX
 SG_ DIF_a027_torqueMotor m27 : 32|13@1- (0.25,0) [-1024|1023.75] "Nm" Vector__XXX
 SG_ DIF_a027_motorSpeed m27 : 48|16@1- (1,0) [-32768|32767] "RPM" Vector__XXX
 SG_ DIF_a028_phaseAirms m28 : 16|16@1+ (1,0) [0|65535] "A" Vector__XXX
 SG_ DIF_a028_iArmsTorque m28 : 32|16@1+ (0.25,0) [0|16383.75] "Nm" Vector__XXX
 SG_ DIF_a028_iArmsSpeed m28 : 48|16@1+ (1,0) [0|65535] "RPM" Vector__XXX
 SG_ DIF_a029_phaseBirms m29 : 16|16@1+ (1,0) [0|65535] "A" Vector__XXX
 SG_ DIF_a029_iBrmsTorque m29 : 32|16@1+ (0.25,0) [0|16383.75] "Nm" Vector__XXX
 SG_ DIF_a029_iBrmsSpeed m29 : 48|16@1+ (1,0) [0|65535] "RPM" Vector__XXX
 SG_ DIF_a030_phaseCirms m30 : 16|16@1+ (1,0) [0|65535] "A" Vector__XXX
 SG_ DIF_a030_iCrmsTorque m30 : 32|16@1+ (0.25,0) [0|16383.75] "Nm" Vector__XXX
 SG_ DIF_a030_iCrmsSpeed m30 : 48|16@1+ (1,0) [0|65535] "RPM" Vector__XXX
 SG_ DIF_a031_phaseAoffset m31 : 16|16@1- (0.002,0) [-65.536|65.534] "A" Vector__XXX
 SG_ DIF_a032_phaseBoffset m32 : 16|16@1- (0.002,0) [-65.536|65.534] "A" Vector__XXX
 SG_ DIF_a033_phaseAcurrent m33 : 16|16@1- (1,0) [-32768|32767] "A" Vector__XXX
 SG_ DIF_a033_deltaIa m33 : 32|16@1- (1,0) [-32768|32767] "A" Vector__XXX
 SG_ DIF_a033_vRefIa m33 : 48|16@1- (0.001,0) [-32.768|32.767] "V" Vector__XXX
 SG_ DIF_a034_phaseBcurrent m34 : 16|16@1- (1,0) [-32768|32767] "A" Vector__XXX
 SG_ DIF_a034_deltaIb m34 : 32|16@1- (1,0) [-32768|32767] "A" Vector__XXX
 SG_ DIF_a034_vRefIb m34 : 48|16@1- (0.001,0) [-32.768|32.767] "V" Vector__XXX
 SG_ DIF_a035_phaseAerror m35 : 16|1@1+ (1,0) [0|1] "" Vector__XXX
 SG_ DIF_a035_phaseBerror m35 : 17|1@1+ (1,0) [0|1] "" Vector__XXX
 SG_ DIF_a035_phaseCerror m35 : 18|1@1+ (1,0) [0|1] "" Vector__XXX
 SG_ DIF_a035_standbyCurrent m35 : 19|1@1+ (1,0) [0|1] "" Vector__XXX
 SG_ DIF_a035_unbalancedCurrent m35 : 20|1@1+ (1,0) [0|1] "" Vector__XXX
 SG_ DIF_a035_wontMoveCurrent m35 : 21|1@1+ (1,0) [0|1] "" Vector__XXX
 SG_ DIF_a035_reportingPhase m35 : 22|2@1+ (1,0) [0|3] "" Vector__XXX
 SG_ DIF_a035_noDriveCurrent m35 : 24|1@1+ (1,0) [0|1] "" Vector__XXX
 SG_ DIF_a035_phaseDifference m35 : 25|7@1+ (1,0) [0|127] "%" Vector__XXX
 SG_ DIF_a035_phaseCurrent m35 : 32|16@1+ (1,0) [0|65535] "A" Vector__XXX
 SG_ DIF_a035_frequency m35 : 48|10@1+ (1,0) [0|1023] "Hz" Vector__XXX
 SG_ DIF_a036_busVoltage m36 : 16|16@1+ (0.1,0) [0|6553.5] "V" Vector__XXX
 SG_ DIF_a036_busHighLimit m36 : 32|16@1+ (0.1,0) [0|6553.5] "V" Vector__XXX
 SG_ DIF_a037_busVoltage m37 : 16|16@1+ (0.1,0) [0|6553.5] "V" Vector__XXX
 SG_ DIF_a037_busLowLimit m37 : 32|16@1+ (0.1,0) [0|6553.5] "V" Vector__XXX
 SG_ DIF_a038_vBMS m38 : 16|13@1+ (0.2,0) [0|1638.2] "V" Vector__XXX
 SG_ DIF_a038_vBat m38 : 32|13@1+ (0.2,0) [0|1638.2] "V" Vector__XXX
 SG_ DIF_a038_iBat m38 : 48|13@1+ (0.5,0) [0|4095.5] "A" Vector__XXX
 SG_ DIF_a038_reason m38 : 61|2@1+ (1,0) [0|3] "" Vector__XXX
 SG_ DIF_a040_torque m40 : 16|1@1+ (1,0) [0|1] "" Vector__XXX
 SG_ DIF_a040_capability m40 : 17|1@1+ (1,0) [0|1] "" Vector__XXX
 SG_ DIF_a040_power m40 : 18|1@1+ (1,0) [0|1] "" Vector__XXX
 SG_ DIF_a040_status m40 : 19|1@1+ (1,0) [0|1] "" Vector__XXX
 SG_ DIF_a040_capability2 m40 : 20|1@1+ (1,0) [0|1] "" Vector__XXX
 SG_ DIF_a040_hvStatus m40 : 21|1@1+ (1,0) [0|1] "" Vector__XXX
 SG_ DIF_a040_temperature m40 : 22|1@1+ (1,0) [0|1] "" Vector__XXX
 SG_ DIF_a041_uartRxDataAvailable m41 : 16|1@1+ (1,0) [0|1] "" Vector__XXX
 SG_ DIF_a041_SDC_status_MIA m41 : 17|1@1+ (1,0) [0|1] "" Vector__XXX
 SG_ DIF_a041_diUartRxVersion m41 : 18|4@1+ (1,0) [0|15] "" Vector__XXX
 SG_ DIF_a041_sdcUartRxVersion m41 : 24|4@1+ (1,0) [0|15] "" Vector__XXX
 SG_ DIF_a043_outletTemp m43 : 16|16@1- (0.1,0) [-3276.8|3276.7] "C" Vector__XXX
 SG_ DIF_a044_outletTemp m44 : 16|16@1- (0.1,0) [-3276.8|3276.7] "C" Vector__XXX
 SG_ DIF_a045_inletTemp m45 : 16|10@1+ (0.25,-60) [-60|195.75] "DegC" Vector__XXX
 SG_ DIF_a045_outletTemp m45 : 26|10@1+ (0.25,-60) [-60|195.75] "DegC" Vector__XXX
 SG_ DIF_a045_heatsinkTemp m45 : 36|10@1+ (0.25,-60) [-60|195.75] "DegC" Vector__XXX
 SG_ DIF_a045_outletTempSlope m45 : 48|8@1- (0.5,0) [-64|63.5] "DegC/s" Vector__XXX
 SG_ DIF_a046_statorTemp1 m46 : 16|16@1- (0.1,0) [-3276.8|3276.7] "DegC" Vector__XXX
 SG_ DIF_a046_statorTemp2 m46 : 32|16@1- (0.1,0) [-3276.8|3276.7] "DegC" Vector__XXX
 SG_ DIF_a047_statorTemp1 m47 : 16|16@1- (0.1,0) [-3276.8|3276.7] "DegC" Vector__XXX
 SG_ DIF_a047_statorTslope1 m47 : 32|16@1- (0.1,0) [-3276.8|3276.7] "DegC/s" Vector__XXX
 SG_ DIF_a050_statorTemp1 m50 : 16|16@1- (0.1,0) [-3276.8|3276.7] "DegC" Vector__XXX
 SG_ DIF_a050_statorTemp2 m50 : 32|16@1- (0.1,0) [-3276.8|3276.7] "DegC" Vector__XXX
 SG_ DIF_a052_torque m52 : 16|1@1+ (1,0) [0|1] "" Vector__XXX
 SG_ DIF_a052_capability m52 : 17|1@1+ (1,0) [0|1] "" Vector__XXX
 SG_ DIF_a052_power m52 : 18|1@1+ (1,0) [0|1] "" Vector__XXX
 SG_ DIF_a052_status m52 : 19|1@1+ (1,0) [0|1] "" Vector__XXX
 SG_ DIF_a052_capability2 m52 : 20|1@1+ (1,0) [0|1] "" Vector__XXX
 SG_ DIF_a052_hvStatus m52 : 21|1@1+ (1,0) [0|1] "" Vector__XXX
 SG_ DIF_a052_temperature m52 : 22|1@1+ (1,0) [0|1] "" Vector__XXX
 SG_ DIF_a054_outletTemp m54 : 16|16@1- (0.1,0) [-3276.8|3276.7] "C" Vector__XXX
 SG_ DIF_a054_heatsinkTemp m54 : 32|16@1- (0.1,0) [-3276.8|3276.7] "C" Vector__XXX
 SG_ DIF_a055_parameterDI m55 : 16|13@1- (0.25,0) [-1024|1023.75] "Nm" Vector__XXX
 SG_ DIF_a055_parameterPM m55 : 32|13@1- (0.25,0) [-1024|1023.75] "Nm" Vector__XXX
 SG_ DIF_a055_torqueType m55 : 45|2@1+ (1,0) [0|3] "" Vector__XXX
 SG_ DIF_a055_motorRPM m55 : 48|16@1- (1,0) [-32768|32767] "RPM" Vector__XXX
 SG_ DIF_a056_pcbTemp m56 : 16|16@1- (0.1,0) [-3276.8|3276.7] "C" Vector__XXX
 SG_ DIF_a057_pcbTemp m57 : 16|16@1- (0.1,0) [-3276.8|3276.7] "C" Vector__XXX
 SG_ DIF_a058_pcbTemp m58 : 16|10@1+ (0.25,-60) [-60|195.75] "DegC" Vector__XXX
 SG_ DIF_a058_outletTemp m58 : 26|10@1+ (0.25,-60) [-60|195.75] "DegC" Vector__XXX
 SG_ DIF_a058_heatsinkTemp m58 : 36|10@1+ (0.25,-60) [-60|195.75] "DegC" Vector__XXX
 SG_ DIF_a058_pcbTempSlope m58 : 48|8@1- (0.5,0) [-64|63.5] "DegC/s" Vector__XXX
 SG_ DIF_a059_heatsinkTemp m59 : 16|16@1- (0.1,0) [-3276.8|3276.7] "C" Vector__XXX
 SG_ DIF_a060_heatsinkTemp m60 : 16|16@1- (0.1,0) [-3276.8|3276.7] "C" Vector__XXX
 SG_ DIF_a061_sensor m61 : 16|2@1+ (1,0) [0|3] "" Vector__XXX
 SG_ DIF_a061_reason m61 : 18|1@1+ (1,0) [0|1] "" Vector__XXX
 SG_ DIF_a061_phTemp m61 : 24|16@1- (0.1,0) [-3276.8|3276.7] "C" Vector__XXX
 SG_ DIF_a061_otherTemp m61 : 40|16@1- (0.1,0) [-3276.8|3276.7] "C" Vector__XXX
 SG_ DIF_a062_limpReason m62 : 16|6@1+ (1,0) [0|63] "" Vector__XXX
 SG_ DIF_a063_BB_status m63 : 16|1@1+ (1,0) [0|1] "" Vector__XXX
 SG_ DIF_a064_interventionType m64 : 16|4@1+ (1,0) [0|15] "" Vector__XXX
 SG_ DIF_a064_torqueCmdState m64 : 20|4@1+ (1,0) [1|15] "" Vector__XXX
 SG_ DIF_a066_badValue1 m66 : 16|16@1+ (1,0) [0|65535] "" Vector__XXX
 SG_ DIF_a066_badValue2 m66 : 32|16@1+ (1,0) [0|65535] "" Vector__XXX
 SG_ DIF_a066_canID m66 : 48|12@1+ (1,0) [0|4095] "" Vector__XXX
 SG_ DIF_a066_errorType m66 : 60|3@1+ (1,0) [0|7] "" Vector__XXX
 SG_ DIF_a069_motorSpeed m69 : 16|16@1- (1,0) [-32768|32767] "RPM" Vector__XXX
 SG_ DIF_a069_rotorCoolingPower m69 : 32|8@1+ (20,0) [0|5100] "W" Vector__XXX
 SG_ DIF_a069_rotorMagnetTemp m69 : 40|10@1+ (0.25,-60) [-60|195.75] "DegC" Vector__XXX
 SG_ DIF_a069_fittedTorqueLimit m69 : 50|13@1- (0.25,0) [-1024|1023.75] "Nm" Vector__XXX
 SG_ DIF_a072_reason m72 : 16|2@1+ (1,0) [0|3] "" Vector__XXX
 SG_ DIF_a073_motorSpeedrpm m73 : 16|16@1- (1,0) [-32768|32767] "RPM" Vector__XXX
 SG_ DIF_a075_motorSpeed m75 : 16|16@1+ (1,0) [0|65535] "RPM" Vector__XXX
 SG_ DIF_a075_absSpeed m75 : 32|16@1+ (1,0) [0|65535] "RPM" Vector__XXX
 SG_ DIF_a076_lvSupplyV m76 : 16|16@1+ (0.001,0) [0|65.535] "V" Vector__XXX
 SG_ DIF_a077_lvSupplyV m77 : 16|16@1+ (0.001,0) [0|65.535] "V" Vector__XXX
 SG_ DIF_a078_adcRefChan m78 : 16|4@1+ (1,0) [0|15] "" Vector__XXX
 SG_ DIF_a078_adcRefLowAvg m78 : 24|16@1+ (1,0) [0|65535] "" Vector__XXX
 SG_ DIF_a079_adcRefChan m79 : 16|4@1+ (1,0) [0|15] "" Vector__XXX
 SG_ DIF_a079_adcRefHighAvg m79 : 24|16@1+ (1,0) [0|65535] "" Vector__XXX
 SG_ DIF_a087_gtwCarConfig m87 : 16|1@1+ (1,0) [0|1] "" Vector__XXX
 SG_ DIF_a087_gtwTime m87 : 17|1@1+ (1,0) [0|1] "" Vector__XXX
 SG_ DIF_a087_gtwUpdateStatus m87 : 18|1@1+ (1,0) [0|1] "" Vector__XXX
 SG_ DIF_a087_gearControl m87 : 19|1@1+ (1,0) [0|1] "" Vector__XXX
 SG_ DIF_a087_carState m87 : 20|1@1+ (1,0) [0|1] "" Vector__XXX
 SG_ DIF_a090_reason m90 : 16|1@1+ (1,0) [0|1] "" Vector__XXX
 SG_ DIF_a090_systemState m90 : 17|1@1+ (1,0) [0|1] "" Vector__XXX
 SG_ DIF_a090_state m90 : 18|1@1+ (1,0) [0|1] "" Vector__XXX
 SG_ DIF_a090_locState m90 : 19|1@1+ (1,0) [0|1] "" Vector__XXX
 SG_ DIF_a090_state2 m90 : 20|1@1+ (1,0) [0|1] "" Vector__XXX
 SG_ DIF_a090_state4 m90 : 21|1@1+ (1,0) [0|1] "" Vector__XXX
 SG_ DIF_a091_ESP_brakeTorque m91 : 16|1@1+ (1,0) [0|1] "" Vector__XXX
 SG_ DIF_a091_ESP_wheelSpeeds m91 : 17|1@1+ (1,0) [0|1] "" Vector__XXX
 SG_ DIF_a091_ESP_wheelRotation m91 : 18|1@1+ (1,0) [0|1] "" Vector__XXX
 SG_ DIF_a091_ESP_motorLimits m91 : 19|1@1+ (1,0) [0|1] "" Vector__XXX
 SG_ DIF_a091_ESP_offsets m91 : 20|1@1+ (1,0) [0|1] "" Vector__XXX
 SG_ DIF_a091_ESP_status m91 : 21|1@1+ (1,0) [0|1] "" Vector__XXX
 SG_ DIF_a091_ESP_party3 m91 : 22|1@1+ (1,0) [0|1] "" Vector__XXX
 SG_ DIF_a092_bmsStatus m92 : 16|1@1+ (1,0) [0|1] "" Vector__XXX
 SG_ DIF_a092_bmsDriveLimits m92 : 17|1@1+ (1,0) [0|1] "" Vector__XXX
 SG_ DIF_a092_bmsHvBusStatus m92 : 18|1@1+ (1,0) [0|1] "" Vector__XXX
 SG_ DIF_a092_bmsPowerAvailable m92 : 19|1@1+ (1,0) [0|1] "" Vector__XXX
 SG_ DIF_a092_bmsBmbMinMax m92 : 20|1@1+ (1,0) [0|1] "" Vector__XXX
 SG_ DIF_a092_bmsSocStatus m92 : 21|1@1+ (1,0) [0|1] "" Vector__XXX
 SG_ DIF_a092_bmsThermalStatus m92 : 22|1@1+ (1,0) [0|1] "" Vector__XXX
 SG_ DIF_a092_bmsCtrStatus m92 : 23|1@1+ (1,0) [0|1] "" Vector__XXX
 SG_ DIF_a092_bmsVoltageRegGain m92 : 24|1@1+ (1,0) [0|1] "" Vector__XXX
 SG_ DIF_a092_bmsPackConfig m92 : 25|1@1+ (1,0) [0|1] "" Vector__XXX
 SG_ DIF_a092_bmsSystemStatus m92 : 26|1@1+ (1,0) [0|1] "" Vector__XXX
 SG_ DIF_a094_canID m94 : 16|12@1+ (1,0) [0|4095] "" Vector__XXX
 SG_ DIF_a094_errorType m94 : 28|3@1+ (1,0) [0|7] "" Vector__XXX
 SG_ DIF_a094_badValue1 m94 : 32|16@1+ (1,0) [0|65535] "" Vector__XXX
 SG_ DIF_a094_badValue2 m94 : 48|16@1+ (1,0) [0|65535] "" Vector__XXX
 SG_ DIF_a096_const_fast m96 : 16|1@1+ (1,0) [0|1] "" Vector__XXX
 SG_ DIF_a096_text_fast m96 : 17|1@1+ (1,0) [0|1] "" Vector__XXX
 SG_ DIF_a096_text_flash m96 : 18|1@1+ (1,0) [0|1] "" Vector__XXX
 SG_ DIF_a096_mem_data m96 : 19|1@1+ (1,0) [0|1] "" Vector__XXX
 SG_ DIF_a096_mem_regs m96 : 20|1@1+ (1,0) [0|1] "" Vector__XXX
 SG_ DIF_a096_boot_flash m96 : 21|1@1+ (1,0) [0|1] "" Vector__XXX
 SG_ DIF_a096_word1 m96 : 24|16@1+ (1,0) [0|65535] "" Vector__XXX
 SG_ DIF_a096_word2 m96 : 40|16@1+ (1,0) [0|65535] "" Vector__XXX
 SG_ DIF_a097_errorType m97 : 16|3@1+ (1,0) [0|7] "" Vector__XXX
 SG_ DIF_a097_lineNumber m97 : 24|16@1+ (1,0) [0|65535] "" Vector__XXX
 SG_ DIF_a097_argument m97 : 40|16@1+ (1,0) [0|65535] "" Vector__XXX
 SG_ DIF_a098_pwmCount m98 : 16|16@1+ (1,0) [0|65535] "" Vector__XXX
 SG_ DIF_a098_fluxState m98 : 32|4@1+ (1,0) [0|15] "" Vector__XXX
 SG_ DIF_a103_fluidTorDeltaT m103 : 16|8@1- (2.007874,68.2677154541) [-188.740156546|323.267713454] "C" Vector__XXX
 SG_ DIF_a103_noFlowDetected m103 : 24|1@1+ (1,0) [0|1] "" Vector__XXX
 SG_ DIF_a103_lowFlowDetected m103 : 25|1@1+ (1,0) [0|1] "" Vector__XXX
 SG_ DIF_a103_fluidImplausible m103 : 26|1@1+ (1,0) [0|1] "" Vector__XXX
 SG_ DIF_a103_inverterTemp m103 : 27|8@1- (2.007874,68.2677154541) [-188.740156546|323.267713454] "C" Vector__XXX
 SG_ DIF_a103_rmsCurrent m103 : 35|10@1- (12.8199605942,0) [-6563.81982423|6550.99986364] "A" Vector__XXX
 SG_ DIF_a103_ambientTemp m103 : 45|7@1- (1.5873016119,11.1111106873) [-90.4761924743|111.111112237] "C" Vector__XXX
 SG_ DIF_a103_sensorTempEst m103 : 52|8@1- (1.25984251499,40.31496) [-120.944881919|200.314959404] "C" Vector__XXX
 SG_ DIF_a107_fpgaVersion m107 : 16|16@1+ (1,0) [0|65535] "" Vector__XXX
 SG_ DIF_a107_fpgaBootVersion m107 : 32|16@1+ (1,0) [0|65535] "" Vector__XXX
 SG_ DIF_a107_fpgaMasterActive m107 : 48|1@1+ (1,0) [0|1] "" Vector__XXX
 SG_ DIF_a107_fpgaFaultActive m107 : 49|1@1+ (1,0) [0|1] "" Vector__XXX
 SG_ DIF_a107_fpgaWarningActive m107 : 50|1@1+ (1,0) [0|1] "" Vector__XXX
 SG_ DIF_a108_fromState m108 : 16|8@1+ (1,0) [0|255] "" Vector__XXX
 SG_ DIF_a108_toState m108 : 24|8@1+ (1,0) [0|255] "" Vector__XXX
 SG_ DIF_a108_blockingAlert m108 : 32|8@1+ (1,0) [0|255] "" Vector__XXX
 SG_ DIF_a110_EPBL_status m110 : 16|1@1+ (1,0) [0|1] "" Vector__XXX
 SG_ DIF_a110_EPBR_status m110 : 17|1@1+ (1,0) [0|1] "" Vector__XXX
 SG_ DIF_a111_phAcalib m111 : 16|16@1+ (1,0) [0|65535] "" Vector__XXX
 SG_ DIF_a111_phBcalib m111 : 32|16@1+ (1,0) [0|65535] "" Vector__XXX
 SG_ DIF_a112_phaseAcurrent m112 : 16|16@1+ (1,0) [0|65535] "A" Vector__XXX
 SG_ DIF_a112_phaseBcurrent m112 : 32|16@1+ (1,0) [0|65535] "A" Vector__XXX
 SG_ DIF_a113_heatsink1Temp m113 : 16|16@1- (0.1,0) [-3276.8|3276.7] "C" Vector__XXX
 SG_ DIF_a113_heatsink2Temp m113 : 32|16@1- (0.1,0) [-3276.8|3276.7] "C" Vector__XXX
 SG_ DIF_a113_heatsink3Temp m113 : 48|16@1- (0.1,0) [-3276.8|3276.7] "C" Vector__XXX
 SG_ DIF_a115_faultAddress m115 : 16|32@1+ (1,0) [0|4294967295] "" Vector__XXX
 SG_ DIF_a115_isWriteNotRead m115 : 48|1@1+ (1,0) [0|1] "" Vector__XXX
 SG_ DIF_a117_torque m117 : 16|1@1+ (1,0) [0|1] "" Vector__XXX
 SG_ DIF_a117_slaveCommand m117 : 17|1@1+ (1,0) [0|1] "" Vector__XXX
 SG_ DIF_a117_power m117 : 18|1@1+ (1,0) [0|1] "" Vector__XXX
 SG_ DIF_a117_slaveCommand2 m117 : 19|1@1+ (1,0) [0|1] "" Vector__XXX
 SG_ DIF_a117_speed m117 : 20|1@1+ (1,0) [0|1] "" Vector__XXX
 SG_ DIF_a117_chassisControl m117 : 21|1@1+ (1,0) [0|1] "" Vector__XXX
 SG_ DIF_a117_systemStatus m117 : 22|1@1+ (1,0) [0|1] "" Vector__XXX
 SG_ DIF_a117_temperature m117 : 23|1@1+ (1,0) [0|1] "" Vector__XXX
 SG_ DIF_a117_vehicle m117 : 24|1@1+ (1,0) [0|1] "" Vector__XXX
 SG_ DIF_a117_AddTcLimit m117 : 26|1@1+ (1,0) [0|1] "" Vector__XXX
 SG_ DIF_a117_dixCommand m117 : 27|1@1+ (1,0) [0|1] "" Vector__XXX
 SG_ DIF_a117_odometerStatus m117 : 30|1@1+ (1,0) [0|1] "" Vector__XXX
 SG_ DIF_a117_maxRatedPower m117 : 31|1@1+ (1,0) [0|1] "" Vector__XXX
 SG_ DIF_a119_hvpFaults m119 : 16|1@1+ (1,0) [0|1] "" Vector__XXX
 SG_ DIF_a120_dcLinkInfo m120 : 16|1@1+ (1,0) [0|1] "" Vector__XXX
 SG_ DIF_a121_badRegReason m121 : 16|3@1+ (1,0) [0|7] "" Vector__XXX
 SG_ DIF_a121_torqueDelta m121 : 19|13@1- (0.25,0) [-1024|1023.75] "Nm" Vector__XXX
 SG_ DIF_a121_badCurrent m121 : 32|16@1- (0.1,0) [-3276.8|3276.7] "A" Vector__XXX
 SG_ DIF_a121_badFlux m121 : 48|16@1+ (0.0001,0) [0|6.5535] "Wb" Vector__XXX
 SG_ DIF_a123_lossReason m123 : 16|3@1+ (1,0) [0|7] "" Vector__XXX
 SG_ DIF_a123_busVoltage m123 : 19|6@1+ (4,250) [250|502] "V" Vector__XXX
 SG_ DIF_a123_badFlux m123 : 25|7@1+ (0.0015,0) [0|0.1905] "Wb" Vector__XXX
 SG_ DIF_a123_lossRequest m123 : 32|7@1+ (0.1,0) [0|12.7] "kW" Vector__XXX
 SG_ DIF_a123_badCurrent m123 : 39|9@1- (10,0) [-2560|2550] "A" Vector__XXX
 SG_ DIF_a123_motorRPM m123 : 48|8@1- (150,0) [-19200|19050] "RPM" Vector__XXX
 SG_ DIF_a123_varianceD m123 : 56|4@1+ (20,0) [0|300] "A" Vector__XXX
 SG_ DIF_a123_varianceQ m123 : 60|4@1+ (20,0) [0|300] "A" Vector__XXX
 SG_ DIF_a126_limpReason m126 : 16|6@1+ (1,0) [0|63] "" Vector__XXX
 SG_ DIF_a127_gpoReason m127 : 16|4@1+ (1,0) [0|15] "" Vector__XXX
 SG_ DIF_a127_temp m127 : 24|16@1- (0.1,0) [-3276.8|3276.7] "C" Vector__XXX
 SG_ DIF_a133_capacitorTemp m133 : 16|16@1- (0.1,0) [-3276.8|3276.7] "C" Vector__XXX
 SG_ DIF_a133_badValue1 m133 : 32|16@1- (0.1,0) [-3276.8|3276.7] "C" Vector__XXX
 SG_ DIF_a133_badValue2 m133 : 48|16@1- (0.1,0) [-3276.8|3276.7] "C" Vector__XXX
 SG_ DIF_a134_wheelSpeedDiffFrL m134 : 16|12@1- (0.0625,0) [-128|127.9375] "kph" Vector__XXX
 SG_ DIF_a134_wheelSpeedDiffFrR m134 : 28|12@1- (0.0625,0) [-128|127.9375] "kph" Vector__XXX
 SG_ DIF_a134_wheelSpeedDiffReL m134 : 40|12@1- (0.0625,0) [-128|127.9375] "kph" Vector__XXX
 SG_ DIF_a134_wheelSpeedDiffReR m134 : 52|12@1- (0.0625,0) [-128|127.9375] "kph" Vector__XXX
 SG_ DIF_a136_spiError_BL m136 : 16|1@1+ (1,0) [0|1] "" Vector__XXX
 SG_ DIF_a136_crcError_BL m136 : 17|1@1+ (1,0) [0|1] "" Vector__XXX
 SG_ DIF_a136_busyError_BL m136 : 18|1@1+ (1,0) [0|1] "" Vector__XXX
 SG_ DIF_a136_spiError_BH m136 : 19|1@1+ (1,0) [0|1] "" Vector__XXX
 SG_ DIF_a136_crcError_BH m136 : 20|1@1+ (1,0) [0|1] "" Vector__XXX
 SG_ DIF_a136_busyError_BH m136 : 21|1@1+ (1,0) [0|1] "" Vector__XXX
 SG_ DIF_a136_spiError_CL m136 : 22|1@1+ (1,0) [0|1] "" Vector__XXX
 SG_ DIF_a136_crcError_CL m136 : 23|1@1+ (1,0) [0|1] "" Vector__XXX
 SG_ DIF_a136_busyError_CL m136 : 24|1@1+ (1,0) [0|1] "" Vector__XXX
 SG_ DIF_a136_spiError_CH m136 : 25|1@1+ (1,0) [0|1] "" Vector__XXX
 SG_ DIF_a136_crcError_CH m136 : 26|1@1+ (1,0) [0|1] "" Vector__XXX
 SG_ DIF_a136_busyError_CH m136 : 27|1@1+ (1,0) [0|1] "" Vector__XXX
 SG_ DIF_a136_spiError_AL m136 : 28|1@1+ (1,0) [0|1] "" Vector__XXX
 SG_ DIF_a136_crcError_AL m136 : 29|1@1+ (1,0) [0|1] "" Vector__XXX
 SG_ DIF_a136_busyError_AL m136 : 30|1@1+ (1,0) [0|1] "" Vector__XXX
 SG_ DIF_a136_spiError_AH m136 : 31|1@1+ (1,0) [0|1] "" Vector__XXX
 SG_ DIF_a136_crcError_AH m136 : 32|1@1+ (1,0) [0|1] "" Vector__XXX
 SG_ DIF_a136_busyError_AH m136 : 33|1@1+ (1,0) [0|1] "" Vector__XXX
 SG_ DIF_a144_autopilot m144 : 16|1@1+ (1,0) [0|1] "" Vector__XXX
 SG_ DIF_a144_chassisType m144 : 17|1@1+ (1,0) [0|1] "" Vector__XXX
 SG_ DIF_a144_drivetrainType m144 : 18|1@1+ (1,0) [0|1] "" Vector__XXX
 SG_ DIF_a144_packEnergy m144 : 19|1@1+ (1,0) [0|1] "" Vector__XXX
 SG_ DIF_a144_packPerformanceDeviatio m144 : 20|1@1+ (1,0) [0|1] "" Vector__XXX
 SG_ DIF_a144_performancePackage m144 : 21|1@1+ (1,0) [0|1] "" Vector__XXX
 SG_ DIF_a144_vdcType m144 : 22|1@1+ (1,0) [0|1] "" Vector__XXX
 SG_ DIF_a144_brakeHWType m144 : 23|1@1+ (1,0) [0|1] "" Vector__XXX
 SG_ DIF_a144_inverterHardware m144 : 24|1@1+ (1,0) [0|1] "" Vector__XXX
 SG_ DIF_a144_cabinPTCHeaterType m144 : 25|1@1+ (1,0) [0|1] "" Vector__XXX
 SG_ DIF_a144_frunkLatchType m144 : 26|1@1+ (1,0) [0|1] "" Vector__XXX
 SG_ DIF_a144_platformMaxBusVoltage m144 : 27|1@1+ (1,0) [0|1] "" Vector__XXX
 SG_ DIF_a144_oilPump1HwType m144 : 28|1@1+ (1,0) [0|1] "" Vector__XXX
 SG_ DIF_a144_oilPump2HwType m144 : 29|1@1+ (1,0) [0|1] "" Vector__XXX
 SG_ DIF_a144_heatsinkType m144 : 30|1@1+ (1,0) [0|1] "" Vector__XXX
 SG_ DIF_a144_softPerformanceLimit m144 : 31|1@1+ (1,0) [0|1] "" Vector__XXX
 SG_ DIF_a144_brakeActuationType m144 : 32|1@1+ (1,0) [0|1] "" Vector__XXX
 SG_ DIF_a144_dasHw m144 : 33|1@1+ (1,0) [0|1] "" Vector__XXX
 SG_ DIF_a144_chassisSubType m144 : 34|1@1+ (1,0) [0|1] "" Vector__XXX
 SG_ DIF_a147_overtorque1UsedCount m147 : 16|8@1+ (1,0) [0|255] "" Vector__XXX
 SG_ DIF_a147_overtorque2UsedCount m147 : 24|10@1+ (1,0) [0|1023] "" Vector__XXX
 SG_ DIF_a147_accumulatedWear m147 : 34|10@1+ (0.005,0) [0|5.115] "1" Vector__XXX
 SG_ DIF_a147_wearIsValid m147 : 44|1@1+ (1,0) [0|1] "" Vector__XXX
 SG_ DIF_a149_flow m149 : 16|8@1+ (0.1,0) [0|25.4] "LPM" Vector__XXX
 SG_ DIF_a149_voltage m149 : 24|8@1+ (0.1,0) [0|25.5] "V" Vector__XXX
 SG_ DIF_a149_temperature m149 : 32|8@1+ (1,-40) [-40|215] "DegC" Vector__XXX
 SG_ DIF_a149_state m149 : 40|3@1+ (1,0) [0|6] "" Vector__XXX
 SG_ DIF_a149_fluidTempSNA m149 : 43|1@1+ (1,0) [0|1] "" Vector__XXX
 SG_ DIF_a149_insufficientFlow m149 : 44|1@1+ (1,0) [0|1] "" Vector__XXX
 SG_ DIF_a149_motorOpenPhase m149 : 45|1@1+ (1,0) [0|1] "" Vector__XXX
 SG_ DIF_a149_motorShorted m149 : 46|1@1+ (1,0) [0|1] "" Vector__XXX
 SG_ DIF_a149_motorFlowSNA m149 : 47|1@1+ (1,0) [0|1] "" Vector__XXX
 SG_ DIF_a149_responseError m149 : 48|1@1+ (1,0) [0|1] "" Vector__XXX
 SG_ DIF_a149_pcbaID m149 : 49|1@1+ (1,0) [0|1] "" Vector__XXX
 SG_ DIF_a150_vBatRawMinusFiltered m150 : 16|10@1- (1,0) [-512|511] "V" Vector__XXX
 SG_ DIF_a150_vBatFilteredRate m150 : 32|8@1- (100,0) [-12800|12700] "V/s" Vector__XXX
 SG_ DIF_a150_elapsedMs m150 : 40|8@1+ (1,0) [0|255] "ms" Vector__XXX
 SG_ DIF_a150_energy m150 : 48|16@1+ (1,0) [0|65535] "J" Vector__XXX
 SG_ DIF_a152_errorType m152 : 16|3@1+ (1,0) [0|7] "" Vector__XXX
 SG_ DIF_a152_frameId m152 : 24|8@1+ (1,0) [0|255] "" Vector__XXX
 SG_ DIF_a152_badValue m152 : 32|8@1+ (1,0) [0|255] "" Vector__XXX
 SG_ DIF_a152_expectedValue m152 : 40|8@1+ (1,0) [0|255] "" Vector__XXX
 SG_ DIF_a153_oilFlow m153 : 16|8@1+ (0.1,0) [0|25.4] "LPM" Vector__XXX
 SG_ DIF_a153_oilTemperature m153 : 24|8@1+ (1,-40) [-40|214] "DegC" Vector__XXX
 SG_ DIF_a153_phaseCurrent m153 : 32|8@1+ (0.1,0) [0|25.4] "A" Vector__XXX
 SG_ DIF_a153_dcVoltage m153 : 40|8@1+ (0.3,0) [0|76.2] "V" Vector__XXX
 SG_ DIF_a153_lowPressPlausibility m153 : 48|5@1+ (3.3,0) [0|102.3] "%" Vector__XXX
 SG_ DIF_a153_state m153 : 53|3@1+ (1,0) [0|6] "" Vector__XXX
 SG_ DIF_a153_oilPumpAlert m153 : 56|5@1+ (1,0) [0|31] "" Vector__XXX
 SG_ DIF_a153_reason m153 : 61|3@1+ (1,0) [0|7] "" Vector__XXX
 SG_ DIF_a154_motorRPM m154 : 16|16@1- (1,0) [-32768|32767] "RPM" Vector__XXX
 SG_ DIF_a154_phaseError m154 : 32|8@1- (0.004,0) [-0.512|0.508] "1" Vector__XXX
 SG_ DIF_a154_commonGain m154 : 40|8@1+ (0.02,0) [0|5.1] "1" Vector__XXX
 SG_ DIF_a154_noCalibration m154 : 48|1@1+ (1,0) [0|1] "" Vector__XXX
 SG_ DIF_a154_noPhaseLock m154 : 49|1@1+ (1,0) [0|1] "" Vector__XXX
 SG_ DIF_a154_noCarrier m154 : 50|1@1+ (1,0) [0|1] "" Vector__XXX
 SG_ DIF_a154_notReady m154 : 51|1@1+ (1,0) [0|1] "" Vector__XXX
 SG_ DIF_a154_errorTableInvalid m154 : 52|1@1+ (1,0) [0|1] "" Vector__XXX
 SG_ DIF_a154_carrierOffset m154 : 53|1@1+ (1,0) [0|1] "" Vector__XXX
 SG_ DIF_a154_trackerIrrational m154 : 54|1@1+ (1,0) [0|1] "" Vector__XXX
 SG_ DIF_a154_claMIA m154 : 55|1@1+ (1,0) [0|1] "" Vector__XXX
 SG_ DIF_a155_sensors m155 : 16|1@1+ (1,0) [0|1] "" Vector__XXX
 SG_ DIF_a155_coolant m155 : 17|1@1+ (1,0) [0|1] "" Vector__XXX
 SG_ DIF_a155_LVPowerState m155 : 18|1@1+ (1,0) [0|1] "" Vector__XXX
 SG_ DIF_a155_vehicleStatus m155 : 19|1@1+ (1,0) [0|1] "" Vector__XXX
 SG_ DIF_a155_status m155 : 20|1@1+ (1,0) [0|1] "" Vector__XXX
 SG_ DIF_a155_leftDoorStatus m155 : 21|1@1+ (1,0) [0|1] "" Vector__XXX
 SG_ DIF_a155_rightDoorStatus m155 : 22|1@1+ (1,0) [0|1] "" Vector__XXX
 SG_ DIF_a155_vcleftSwitchStatus m155 : 23|1@1+ (1,0) [0|1] "" Vector__XXX
 SG_ DIF_a155_restraintStatus m155 : 24|1@1+ (1,0) [0|1] "" Vector__XXX
 SG_ DIF_a155_systemStatus m155 : 25|1@1+ (1,0) [0|1] "" Vector__XXX
 SG_ DIF_a155_prndStatus m155 : 26|1@1+ (1,0) [0|1] "" Vector__XXX
 SG_ DIF_a155_liftgateStatus m155 : 27|1@1+ (1,0) [0|1] "" Vector__XXX
 SG_ DIF_a157_RCM_inertial1 m157 : 16|1@1+ (1,0) [0|1] "" Vector__XXX
 SG_ DIF_a157_RCM_inertial2 m157 : 17|1@1+ (1,0) [0|1] "" Vector__XXX
 SG_ DIF_a158_IBST_party1 m158 : 16|1@1+ (1,0) [0|1] "" Vector__XXX
 SG_ DIF_a158_BUS1_IBST_status m158 : 17|1@1+ (1,0) [0|1] "" Vector__XXX
 SG_ DIF_a158_BUS2_IBST_status m158 : 18|1@1+ (1,0) [0|1] "" Vector__XXX
 SG_ DIF_a160_vBatRawMinusFiltered m160 : 16|10@1- (1,0) [-512|511] "V" Vector__XXX
 SG_ DIF_a160_vBatFilteredRate m160 : 32|8@1- (100,0) [-12800|12700] "V/s" Vector__XXX
 SG_ DIF_a160_elapsedMs m160 : 40|8@1+ (1,0) [0|255] "ms" Vector__XXX
 SG_ DIF_a160_energy m160 : 48|16@1+ (1,0) [0|65535] "J" Vector__XXX
 SG_ DIF_a161_EPAS3P_sysStatus m161 : 16|1@1+ (1,0) [0|1] "" Vector__XXX
 SG_ DIF_a161_EPAS3P_angleCalib m161 : 17|1@1+ (1,0) [0|1] "" Vector__XXX
 SG_ DIF_a202_reason m202 : 16|4@1+ (1,0) [0|15] "" Vector__XXX
 SG_ DIF_a202_movement m202 : 20|9@1+ (0.005,0) [0|2.555] "m" Vector__XXX
 SG_ DIF_a202_sysStateExitCondition m202 : 32|5@1+ (1,0) [0|31] "" Vector__XXX
 SG_ DIF_a233_missedMsgCount m233 : 16|4@1+ (1,0) [0|15] "" Vector__XXX
 SG_ DIF_a233_serviceModeActive m233 : 20|1@1+ (1,0) [0|1] "" Vector__XXX
 SG_ DIF_a234_PCS_dcdcStatus m234 : 16|1@1+ (1,0) [0|1] "" Vector__XXX
 SG_ DIF_a236_states m236 : 16|1@1+ (1,0) [0|1] "" Vector__XXX
 SG_ DIF_a242_RotorOffset m242 : 16|1@1+ (1,0) [0|1] "" Vector__XXX
 SG_ DIF_a242_RotorFlux m242 : 17|1@1+ (1,0) [0|1] "" Vector__XXX
 SG_ DIF_a242_ResolverError m242 : 18|1@1+ (1,0) [0|1] "" Vector__XXX
 SG_ DIF_a244_desatHighSide m244 : 16|1@1+ (1,0) [0|1] "" Vector__XXX
 SG_ DIF_a244_desatLowSide m244 : 17|1@1+ (1,0) [0|1] "" Vector__XXX
 SG_ DIF_a244_singleSwitchShort m244 : 18|1@1+ (1,0) [0|1] "" Vector__XXX
 SG_ DIF_a244_flybackFault m244 : 19|1@1+ (1,0) [0|1] "" Vector__XXX
 SG_ DIF_a244_postShortTestFailed m244 : 20|1@1+ (1,0) [0|1] "" Vector__XXX
 SG_ DIF_a244_udsSelfTest m244 : 21|1@1+ (1,0) [0|1] "" Vector__XXX
 SG_ DIF_a244_irSensorV m244 : 24|6@1+ (0.1,0) [0|6.3] "V" Vector__XXX
 SG_ DIF_a244_gateDriveICUndervoltage m244 : 30|1@1+ (1,0) [0|1] "" Vector__XXX
 SG_ DIF_a244_plausibleSingleSwitchSh m244 : 31|1@1+ (1,0) [0|1] "" Vector__XXX
 SG_ DIF_a246_atSpeedDIResetCount m246 : 16|4@1+ (1,4294967295) [4294967295|4294967310] "" Vector__XXX
 SG_ DIF_a246_didPMCauseASC m246 : 20|1@1+ (1,0) [0|1] "" Vector__XXX
 SG_ DIF_a246_currentSensorRational m246 : 21|1@1+ (1,0) [0|1] "" Vector__XXX
 SG_ DIF_a246_observerDetectedLS3PS m246 : 22|1@1+ (1,0) [0|1] "" Vector__XXX
 SG_ DIF_a246_hvIsGood m246 : 23|1@1+ (1,0) [0|1] "" Vector__XXX
 SG_ DIF_a246_lvIsGood m246 : 24|1@1+ (1,0) [0|1] "" Vector__XXX
 SG_ DIF_a246_codeBranch m246 : 25|2@1+ (1,0) [0|3] "" Vector__XXX
 SG_ DIF_a246_motorRPM m246 : 32|8@1- (150,0) [-19200|19050] "RPM" Vector__XXX
 SG_ DIF_a246_eepromOffsetIa m246 : 40|6@1- (0.763,0) [-24.416|23.653] "A" Vector__XXX
 SG_ DIF_a246_eepromOffsetIb m246 : 48|6@1- (0.763,0) [-24.416|23.653] "A" Vector__XXX
 SG_ DIF_a247_rotorOffsetEst m247 : 16|10@1- (0.05,0) [-25.6|25.55] "degrees" Vector__XXX
 SG_ DIF_a247_motorRPM m247 : 32|16@1- (1,0) [-32768|32767] "RPM" Vector__XXX
 SG_ DIF_a247_torqueMotor m247 : 48|16@1- (1,0) [-32768|32767] "Nm" Vector__XXX
 SG_ DIF_a251_oilFlow m251 : 16|8@1+ (0.1,0) [0|25.4] "LPM" Vector__XXX
 SG_ DIF_a251_oilTemperature m251 : 24|8@1+ (1,-40) [-40|214] "DegC" Vector__XXX
 SG_ DIF_a251_dcVoltage m251 : 32|8@1+ (0.3,0) [0|76.2] "V" Vector__XXX
 SG_ DIF_a251_dcCurrent m251 : 40|8@1+ (0.1,0) [0|25.4] "A" Vector__XXX
 SG_ DIF_a251_phaseCurrent m251 : 48|8@1+ (0.1,0) [0|25.4] "A" Vector__XXX
 SG_ DIF_a251_leadAngle m251 : 56|4@1+ (1.875,0) [0|28.125] "degrees" Vector__XXX
 SG_ DIF_a251_reason m251 : 60|3@1+ (1,0) [0|7] "" Vector__XXX

BO_ 854 DIF_alertMatrix1: 8 DIF
 SG_ DIF_a001_hwPhaseAgateDrive : 0|1@1+ (1,0) [0|1] "" Vector__XXX
 SG_ DIF_a002_hwPhaseBgateDrive : 1|1@1+ (1,0) [0|1] "" Vector__XXX
 SG_ DIF_a003_hwPhaseCgateDrive : 2|1@1+ (1,0) [0|1] "" Vector__XXX
 SG_ DIF_a004_hwPhaseApeak : 3|1@1+ (1,0) [0|1] "" Vector__XXX
 SG_ DIF_a005_hwPhaseBpeak : 4|1@1+ (1,0) [0|1] "" Vector__XXX
 SG_ DIF_a006_hwPhaseCpeak : 5|1@1+ (1,0) [0|1] "" Vector__XXX
 SG_ DIF_a007_statorAnomalyDetected : 6|1@1+ (1,0) [0|1] "" Vector__XXX
 SG_ DIF_a008_hwEncoderA : 7|1@1+ (1,0) [0|1] "" Vector__XXX
 SG_ DIF_a009_hwEncoderB : 8|1@1+ (1,0) [0|1] "" Vector__XXX
 SG_ DIF_a010_unintendedReset : 9|1@1+ (1,0) [0|1] "" Vector__XXX
 SG_ DIF_a011_swPowerStageNotReady : 10|1@1+ (1,0) [0|1] "" Vector__XXX
 SG_ DIF_a012_hvilNotClosed : 11|1@1+ (1,0) [0|1] "" Vector__XXX
 SG_ DIF_a013_eccError : 12|1@1+ (1,0) [0|1] "" Vector__XXX
 SG_ DIF_a014_activeDamping : 13|1@1+ (1,0) [0|1] "" Vector__XXX
 SG_ DIF_a015_mechSafeStateAnomaly : 14|1@1+ (1,0) [0|1] "" Vector__XXX
 SG_ DIF_a016_safeStateApplied : 15|1@1+ (1,0) [0|1] "" Vector__XXX
 SG_ DIF_a017_hwPedalMonitor : 16|1@1+ (1,0) [0|1] "" Vector__XXX
 SG_ DIF_a018_hwLVSupplyUV : 17|1@1+ (1,0) [0|1] "" Vector__XXX
 SG_ DIF_a020_hwMotorEncoder : 19|1@1+ (1,0) [0|1] "" Vector__XXX
 SG_ DIF_a021_hwBusOV : 20|1@1+ (1,0) [0|1] "" Vector__XXX
 SG_ DIF_a022_hw5vSupplyUV : 21|1@1+ (1,0) [0|1] "" Vector__XXX
 SG_ DIF_a024_selfTest : 23|1@1+ (1,0) [0|1] "" Vector__XXX
 SG_ DIF_a025_phaseApeak : 24|1@1+ (1,0) [0|1] "" Vector__XXX
 SG_ DIF_a026_phaseBpeak : 25|1@1+ (1,0) [0|1] "" Vector__XXX
 SG_ DIF_a027_phaseCpeak : 26|1@1+ (1,0) [0|1] "" Vector__XXX
 SG_ DIF_a028_phaseArms : 27|1@1+ (1,0) [0|1] "" Vector__XXX
 SG_ DIF_a029_phaseBrms : 28|1@1+ (1,0) [0|1] "" Vector__XXX
 SG_ DIF_a030_phaseCrms : 29|1@1+ (1,0) [0|1] "" Vector__XXX
 SG_ DIF_a031_phaseAcurrentOffset : 30|1@1+ (1,0) [0|1] "" Vector__XXX
 SG_ DIF_a032_phaseBcurrentOffset : 31|1@1+ (1,0) [0|1] "" Vector__XXX
 SG_ DIF_a033_phaseAcurrentSensor : 32|1@1+ (1,0) [0|1] "" Vector__XXX
 SG_ DIF_a034_phaseBcurrentSensor : 33|1@1+ (1,0) [0|1] "" Vector__XXX
 SG_ DIF_a035_phaseCurrentBalance : 34|1@1+ (1,0) [0|1] "" Vector__XXX
 SG_ DIF_a036_busOV : 35|1@1+ (1,0) [0|1] "" Vector__XXX
 SG_ DIF_a037_busUV : 36|1@1+ (1,0) [0|1] "" Vector__XXX
 SG_ DIF_a038_busVsensor : 37|1@1+ (1,0) [0|1] "" Vector__XXX
 SG_ DIF_a039_exceptionUndefinedInstr : 38|1@1+ (1,0) [0|1] "" Vector__XXX
 SG_ DIF_a040_difMIA : 39|1@1+ (1,0) [0|1] "" Vector__XXX
 SG_ DIF_a041_sdcMIA : 40|1@1+ (1,0) [0|1] "" Vector__XXX
 SG_ DIF_a042_inletSensor : 41|1@1+ (1,0) [0|1] "" Vector__XXX
 SG_ DIF_a043_outletOT : 42|1@1+ (1,0) [0|1] "" Vector__XXX
 SG_ DIF_a044_outletUT : 43|1@1+ (1,0) [0|1] "" Vector__XXX
 SG_ DIF_a045_outletSensor : 44|1@1+ (1,0) [0|1] "" Vector__XXX
 SG_ DIF_a046_statorOT : 45|1@1+ (1,0) [0|1] "" Vector__XXX
 SG_ DIF_a047_statorSensor1 : 46|1@1+ (1,0) [0|1] "" Vector__XXX
 SG_ DIF_a048_statorSensor2 : 47|1@1+ (1,0) [0|1] "" Vector__XXX
 SG_ DIF_a049_statorSensorDiff : 48|1@1+ (1,0) [0|1] "" Vector__XXX
 SG_ DIF_a050_noStatorSensor : 49|1@1+ (1,0) [0|1] "" Vector__XXX
 SG_ DIF_a052_dirMIA : 51|1@1+ (1,0) [0|1] "" Vector__XXX
 SG_ DIF_a053_unexpectedLatchState : 52|1@1+ (1,0) [0|1] "" Vector__XXX
 SG_ DIF_a054_driveInverterOT : 53|1@1+ (1,0) [0|1] "" Vector__XXX
 SG_ DIF_a055_trqCrossCheck : 54|1@1+ (1,0) [0|1] "" Vector__XXX
 SG_ DIF_a056_ambientOT : 55|1@1+ (1,0) [0|1] "" Vector__XXX
 SG_ DIF_a057_ambientUT : 56|1@1+ (1,0) [0|1] "" Vector__XXX
 SG_ DIF_a058_ambientSensor : 57|1@1+ (1,0) [0|1] "" Vector__XXX
 SG_ DIF_a059_heatsinkOT : 58|1@1+ (1,0) [0|1] "" Vector__XXX
 SG_ DIF_a060_heatsinkUT : 59|1@1+ (1,0) [0|1] "" Vector__XXX
 SG_ DIF_a061_heatsinkSensor : 60|1@1+ (1,0) [0|1] "" Vector__XXX
 SG_ DIF_a062_systemLimpMode : 61|1@1+ (1,0) [0|1] "" Vector__XXX
 SG_ DIF_a063_bbMIA : 62|1@1+ (1,0) [0|1] "" Vector__XXX
 SG_ DIF_a064_torqueIntervention : 63|1@1+ (1,0) [0|1] "" Vector__XXX

BO_ 855 DIF_alertMatrix2: 8 DIF
 SG_ DIF_a065_canHardwareBusB : 0|1@1+ (1,0) [0|1] "" Vector__XXX
 SG_ DIF_a066_canDataBusB : 1|1@1+ (1,0) [0|1] "" Vector__XXX
 SG_ DIF_a067_canOverrunBusB : 2|1@1+ (1,0) [0|1] "" Vector__XXX
 SG_ DIF_a069_rotorTempLimit : 4|1@1+ (1,0) [0|1] "" Vector__XXX
 SG_ DIF_a070_udsTransactionInitiated : 5|1@1+ (1,0) [0|1] "" Vector__XXX
 SG_ DIF_a071_busDisconnected : 6|1@1+ (1,0) [0|1] "" Vector__XXX
 SG_ DIF_a072_gateDriveFaultCounter : 7|1@1+ (1,0) [0|1] "" Vector__XXX
 SG_ DIF_a073_motorSpeed : 8|1@1+ (1,0) [0|1] "" Vector__XXX
 SG_ DIF_a074_motorEncoder : 9|1@1+ (1,0) [0|1] "" Vector__XXX
 SG_ DIF_a075_motorSpeedMismatch : 10|1@1+ (1,0) [0|1] "" Vector__XXX
 SG_ DIF_a076_lvSupplyOV : 11|1@1+ (1,0) [0|1] "" Vector__XXX
 SG_ DIF_a077_lvSupplyUV : 12|1@1+ (1,0) [0|1] "" Vector__XXX
 SG_ DIF_a078_adcRefLow : 13|1@1+ (1,0) [0|1] "" Vector__XXX
 SG_ DIF_a079_adcRefHigh : 14|1@1+ (1,0) [0|1] "" Vector__XXX
 SG_ DIF_a081_P0BFF_DIF_EM_CurrentHig : 16|1@1+ (1,0) [0|1] "" Vector__XXX
 SG_ DIF_a082_P7837_DIF_ECU_DemoTimer : 17|1@1+ (1,0) [0|1] "" Vector__XXX
 SG_ DIF_a083_PABCD_DIF_ECU_DemoWindo : 18|1@1+ (1,0) [0|1] "" Vector__XXX
 SG_ DIF_a084_eccTestData0 : 19|1@1+ (1,0) [0|1] "" Vector__XXX
 SG_ DIF_a086_activeDischargeOn : 21|1@1+ (1,0) [0|1] "" Vector__XXX
 SG_ DIF_a087_gtwMIA : 22|1@1+ (1,0) [0|1] "" Vector__XXX
 SG_ DIF_a088_uiMIA : 23|1@1+ (1,0) [0|1] "" Vector__XXX
 SG_ DIF_a090_pmMIA : 25|1@1+ (1,0) [0|1] "" Vector__XXX
 SG_ DIF_a091_espMIA : 26|1@1+ (1,0) [0|1] "" Vector__XXX
 SG_ DIF_a092_bmsMIA : 27|1@1+ (1,0) [0|1] "" Vector__XXX
 SG_ DIF_a093_canHardwareBusA : 28|1@1+ (1,0) [0|1] "" Vector__XXX
 SG_ DIF_a094_canDataBusA : 29|1@1+ (1,0) [0|1] "" Vector__XXX
 SG_ DIF_a095_canOverrunBusA : 30|1@1+ (1,0) [0|1] "" Vector__XXX
 SG_ DIF_a096_memoryError : 31|1@1+ (1,0) [0|1] "" Vector__XXX
 SG_ DIF_a097_eepromError : 32|1@1+ (1,0) [0|1] "" Vector__XXX
 SG_ DIF_a098_intTimeTooLong : 33|1@1+ (1,0) [0|1] "" Vector__XXX
 SG_ DIF_a099_threadOverrun : 34|1@1+ (1,0) [0|1] "" Vector__XXX
 SG_ DIF_a100_assertion : 35|1@1+ (1,0) [0|1] "" Vector__XXX
 SG_ DIF_a101_eccTestData1 : 36|1@1+ (1,0) [0|1] "" Vector__XXX
 SG_ DIF_a102_exceptionPrefetchAbort : 37|1@1+ (1,0) [0|1] "" Vector__XXX
 SG_ DIF_a103_lowFlow : 38|1@1+ (1,0) [0|1] "" Vector__XXX
 SG_ DIF_a107_fpgaError : 42|1@1+ (1,0) [0|1] "" Vector__XXX
 SG_ DIF_a108_stateTrans : 43|1@1+ (1,0) [0|1] "" Vector__XXX
 SG_ DIF_a109_ahbWriteError : 44|1@1+ (1,0) [0|1] "" Vector__XXX
 SG_ DIF_a110_brakeMIA : 45|1@1+ (1,0) [0|1] "" Vector__XXX
 SG_ DIF_a111_badPhaseSensorCalib : 46|1@1+ (1,0) [0|1] "" Vector__XXX
 SG_ DIF_a112_noPhaseCurrent : 47|1@1+ (1,0) [0|1] "" Vector__XXX
 SG_ DIF_a113_noFuncHeatsinkSensor : 48|1@1+ (1,0) [0|1] "" Vector__XXX
 SG_ DIF_a114_exceptionDataAbort : 49|1@1+ (1,0) [0|1] "" Vector__XXX
 SG_ DIF_a115_exceptionDataAbort2 : 50|1@1+ (1,0) [0|1] "" Vector__XXX
 SG_ DIF_a116_highSpeedWearCounter : 51|1@1+ (1,0) [0|1] "" Vector__XXX
 SG_ DIF_a117_diMIA : 52|1@1+ (1,0) [0|1] "" Vector__XXX
 SG_ DIF_a119_hvpMIA : 54|1@1+ (1,0) [0|1] "" Vector__XXX
 SG_ DIF_a120_hvlinkMIA : 55|1@1+ (1,0) [0|1] "" Vector__XXX
 SG_ DIF_a121_motorControlRegulation : 56|1@1+ (1,0) [0|1] "" Vector__XXX
 SG_ DIF_a122_highStackUsage : 57|1@1+ (1,0) [0|1] "" Vector__XXX
 SG_ DIF_a123_lossMotorControl : 58|1@1+ (1,0) [0|1] "" Vector__XXX
 SG_ DIF_a126_limpMode : 61|1@1+ (1,0) [0|1] "" Vector__XXX
 SG_ DIF_a127_gracefulPowerOff : 62|1@1+ (1,0) [0|1] "" Vector__XXX
 SG_ DIF_a128_fpgaVersionMismatch : 63|1@1+ (1,0) [0|1] "" Vector__XXX

BO_ 858 DIF_alertMatrix3: 8 DIF
 SG_ DIF_a133_capacitorOT : 4|1@1+ (1,0) [0|1] "" Vector__XXX
 SG_ DIF_a134_wheelSpeedIrrational : 5|1@1+ (1,0) [0|1] "" Vector__XXX
 SG_ DIF_a136_spiError : 7|1@1+ (1,0) [0|1] "" Vector__XXX
 SG_ DIF_a142_highLashAngle : 13|1@1+ (1,0) [0|1] "" Vector__XXX
 SG_ DIF_a144_configMismatch : 15|1@1+ (1,0) [0|1] "" Vector__XXX
 SG_ DIF_a147_highTorqueWearLimit : 18|1@1+ (1,0) [0|1] "" Vector__XXX
 SG_ DIF_a148_burnInCycleEnded : 19|1@1+ (1,0) [0|1] "" Vector__XXX
 SG_ DIF_a149_oilPumpFailure : 20|1@1+ (1,0) [0|1] "" Vector__XXX
 SG_ DIF_a150_busVD : 21|1@1+ (1,0) [0|1] "" Vector__XXX
 SG_ DIF_a151_shockTorqueLimiter : 22|1@1+ (1,0) [0|1] "" Vector__XXX
 SG_ DIF_a152_linError : 23|1@1+ (1,0) [0|1] "" Vector__XXX
 SG_ DIF_a153_oilPumpDiagnostics : 24|1@1+ (1,0) [0|1] "" Vector__XXX
 SG_ DIF_a154_resolver : 25|1@1+ (1,0) [0|1] "" Vector__XXX
 SG_ DIF_a155_vcfrontMIA : 26|1@1+ (1,0) [0|1] "" Vector__XXX
 SG_ DIF_a156_currentObserver : 27|1@1+ (1,0) [0|1] "" Vector__XXX
 SG_ DIF_a157_rcmMIA : 28|1@1+ (1,0) [0|1] "" Vector__XXX
 SG_ DIF_a158_ibstMIA : 29|1@1+ (1,0) [0|1] "" Vector__XXX
 SG_ DIF_a160_busVoltageAnomaly : 31|1@1+ (1,0) [0|1] "" Vector__XXX
 SG_ DIF_a161_epas3pMIA : 32|1@1+ (1,0) [0|1] "" Vector__XXX
 SG_ DIF_a162_endOfLifetimeBurnIn : 33|1@1+ (1,0) [0|1] "" Vector__XXX
 SG_ DIF_a174_unitMayNotRestart : 45|1@1+ (1,0) [0|1] "" Vector__XXX
 SG_ DIF_a176_safetyICFault : 47|1@1+ (1,0) [0|1] "" Vector__XXX
 SG_ DIF_a177_fluxReferenceCorrected : 48|1@1+ (1,0) [0|1] "" Vector__XXX

BO_TX_BU_ 528 : CP;
BO_TX_BU_ 893 : CP;
BO_TX_BU_ 583 : DAS;
BO_TX_BU_ 2041 : DAS;
BO_TX_BU_ 777 : DAS;
BO_TX_BU_ 1548 : DAS;
BO_TX_BU_ 1318 : DIF;
BO_TX_BU_ 854 : DIF;
BO_TX_BU_ 855 : DIF;
BO_TX_BU_ 858 : DIF;
CM_ BO_ 528 "Charge port controller message: status";
CM_ SG_ 528 CP_type "Charge port controller: type";
CM_ SG_ 528 CP_insertEnableLine "Sensed state of the charge port latch drive enable hardline";
CM_ SG_ 528 CP_latchState "Sensed state of the charge port latch; raw 0 = signal not available (SNA)";
CM_ SG_ 528 CP_permanentPowerRequest "Charge port controller: permanent power request";
CM_ SG_ 528 CP_chargeDoorOpen "Indicates whether the charge port door is open based on all door sensors";
CM_ SG_ 528 CP_doorControlState "State of the charge port door controller";
CM_ SG_ 528 CP_doorButtonPressed "Indicates whether the charge door button has been pressed";
CM_ SG_ 528 CP_swcanRelayClosed "Indicates whether the single wire CAN relay is closed";
CM_ SG_ 528 CP_inhibitOta "Reports the charge port's request to prevent scheduled Over-The-Air (OTA) updates during critical charging operations.";
CM_ SG_ 528 CP_chargeCableState "Charge cable connection state; raw 0 = signal not available (SNA)";
CM_ SG_ 528 CP_latchControlState "Control state of the charge port latch";
CM_ SG_ 528 CP_ledColor "Color of the charge port LED";
CM_ SG_ 528 CP_UHF_handleFound "Indicates whether a charge handle has been found with UHF";
CM_ SG_ 528 CP_faultLineSensed "A signal indicating the set / cleared state of the CP-HVP bi-directional fault line, as sensed by the CP";
CM_ SG_ 528 CP_doorPresenceState "State of door as detected by the presence sensor";
CM_ SG_ 528 CP_inductiveSensorState "State of inductive door sensor";
CM_ SG_ 528 CP_chargeDoorOpenUI "Indicates whether the charge port door is open based only on the door poteniometer";
CM_ SG_ 528 CP_vehicleUnlockRequest "Request to unlock the vehicle";
CM_ SG_ 528 CP_coldWeatherMode "Indicates whether the charge port is in cold weather mode";
CM_ SG_ 528 CP_hvInletExposed "Charge port controller: hv inlet exposed";
CM_ SG_ 528 CP_latchEngaged "Charge port controller: latch engaged";
CM_ SG_ 528 CP_inletHeaterUiState "Reports to the User Interface (UI) the state of the inlet heater.";
CM_ BO_ 893 "Charge port controller message: thermal status";
CM_ SG_ 893 CP_thermalStatusSelect "Charge port controller: thermal status select";
CM_ SG_ 893 CP_pinTemperature1 "Sensed temperature of the charge port inlet pins";
CM_ SG_ 893 CP_pinTemperature2 "Sensed temperature of the charge port inlet pins";
CM_ SG_ 893 CP_pinTemperature3 "Sensed temperature of the charge port inlet pins";
CM_ BO_ 583 "Driver assistance computer message: autopilot debug";
CM_ SG_ 583 DAS_roadEstimator "Driver assistance computer: road estimator";
CM_ SG_ 583 DAS_arbiterBehavior "Which behavior task the arbiter has selected and sent to the controller";
CM_ SG_ 583 DAS_mapAvailability "Driver assistance computer: map availability";
CM_ SG_ 583 DAS_controllerRef "Driver assistance computer: controller ref";
CM_ SG_ 583 DAS_alcInternalState "Reports the internal state of the Automatic Lane Change (ALC) machine.";
CM_ SG_ 583 DAS_behaviorReport "Which target source are we controlling for longitudinally.";
CM_ SG_ 583 DAS_constructionZone "Driver assistance computer: construction zone";
CM_ SG_ 583 DAS_controllerHealth "Driver assistance computer: controller health";
CM_ SG_ 583 DAS_controlDistance "Driver assistance computer: control distance";
CM_ SG_ 583 DAS_autopilotAbortReason "Driver assistance computer: autopilot abort reason";
CM_ SG_ 583 DAS_rqstedBehaviorStatus "Indicates the autopilot behavior state with respect to automatic lane change.";
CM_ SG_ 583 DAS_forkState "Reports the internal state of the mission planner fork state machine.";
CM_ SG_ 583 DAS_laneChangeState "Indicates the state of the lane change state machine.";
CM_ SG_ 583 DAS_lastWatchdogCode "Tracks the last APP task to have triggered a Watchdog reset.";
CM_ BO_ 2041 "Driver assistance computer message: gps status";
CM_ SG_ 2041 DAS_gpsStatusMultiplexer "Driver assistance computer: gps status multiplexer";
CM_ SG_ 2041 DAS_gpsTransportModeState "Indicates if the transport mode algorithm detects the car is in transport mode.";
CM_ SG_ 2041 DAS_gpsSatsInUseHardware "The number of GPS satellites currently in use by hardware solution.";
CM_ SG_ 2041 DAS_gpsWheeltickCounter "Driver assistance computer: gps wheeltick counter";
CM_ SG_ 2041 DAS_gpsWheeltickPulsePeriod "Driver assistance computer: gps wheeltick pulse period";
CM_ SG_ 2041 DAS_gpsRejectingSatData "Indicates whether or not the GPS is rejecting satellites due to poor signal.";
CM_ SG_ 2041 DAS_gpsWheelsOffMotionDetected "Indicates that wheels-off acceleration detected";
CM_ SG_ 2041 DAS_gpsFixTypeHardware "The fix type of the GPS receiver, see u-blox M8 spec, section 33.13.1.1";
CM_ SG_ 2041 DAS_gpsRawxEnabled "GPS receiver has raw messages enabled";
CM_ SG_ 2041 DAS_gpsRxmRawxMia "Driver assistance computer: gps rxm rawx mia";
CM_ SG_ 2041 DAS_gpsRxmSfrbxMia "Driver assistance computer: gps rxm sfrbx mia";
CM_ SG_ 2041 DAS_gpsEsfMeasMia "AP is not receiving EsfMeas message from GPS receiver";
CM_ SG_ 2041 DAS_gpsEsfRawMia "AP is not receiving EsfRaw message from GPS receiver";
CM_ SG_ 2041 DAS_gpsNavStatusMia "AP is not receiving NavStatus message from GPS receiver";
CM_ SG_ 2041 DAS_gpsSoftwareConfigured "Software GPS solution is allowed";
CM_ SG_ 2041 DAS_gpsSoftwareUsed "Software GPS solution is actively used";
CM_ SG_ 2041 DAS_gpsSoftwareFastStartReady "Software GPS solution could use fast start mechanism at boot-up";
CM_ SG_ 2041 DAS_gpsSatsInUseSoftware "The number of GPS satellites currently in use by software solution on SOC-A.";
CM_ SG_ 2041 DAS_gpsFixTypeSoftware "The fix type of the GPS software solution on SOC-A.";
CM_ SG_ 2041 DAS_gpsCWJammingInidcator "Level of continuous wave jamming detected by GPS hardware";
CM_ SG_ 2041 DAS_gpsJammingState "State of GPS jamming monitor";
CM_ SG_ 2041 DAS_gpsSpoofDetectorState "Instantaneous state of GPS spoofing detector. Detection only triggers at the transition from real to suspected spoof signal.";
CM_ SG_ 2041 DAS_gpsInvalidMsgPercentage "Percentage of messages received by AP from GPS receiver that were invalid. Calculated over up-to 10s window.";
CM_ SG_ 2041 DAS_gnssConstellationsState "Indicates if GNSS constellations match expected configuration.";
CM_ SG_ 2041 DAS_gpsReceiverNoiseLevel "General noise level of GPS receiver.";
CM_ SG_ 2041 DAS_gpsAutomaticGainControl "Automatic Gain Control of GPS receiver.";
CM_ SG_ 2041 DAS_gpsPreviousPositionDeltaHw "Change in position of two consecutive location outputs from GPS hardware solution.";
CM_ SG_ 2041 DAS_gpsPreviousPositionDeltaSw "Change in position of two consecutive location outputs from GPS software solution.";
CM_ SG_ 2041 DAS_gpsNmeaDispatchFailureCount "Number of GPS messages dropped by AP without sending over to UI. Calculated over up-to 10s window.";
CM_ SG_ 2041 DAS_gnssMaxInstantaneousCnorGps "Maximum carrier-to-noise ratio among all satellites from GPS constellation.";
CM_ SG_ 2041 DAS_gnssMaxInstantaneousCnorGal "Maximum carrier-to-noise ratio among all satellites from GALILEO constellation.";
CM_ SG_ 2041 DAS_gnssMaxInstantaneousCnorBds "Maximum carrier-to-noise ratio among all satellites from BEIDOU constellation.";
CM_ SG_ 2041 DAS_gpsResetReason "When AP resets GPS receiver, this signal indicates the reason why";
CM_ SG_ 2041 DAS_gpsAccuracyHorizontal "Self-reported horizontal GPS accuracy";
CM_ SG_ 2041 DAS_gpsAccuracyVertical "Self-reported vertical GPS accuracy";
CM_ SG_ 2041 DAS_gpsSolutionFallback "GPS solution falling back from software to hardware";
CM_ SG_ 2041 DAS_gpsToMcuSource "This signal exposes which localization solution is being sent to the MCU.";
CM_ SG_ 2041 DAS_gpsSolutionSoc "Reports which System on Chip (SOC) is producing the GPS localization solution.";
CM_ SG_ 2041 DAS_gpsRedundancyActive "Reports whether the GPS Redundancy feature is active on the Autopilot (AP) board. This feature enables either System on Chip (SOC) to publish the Global Navigation Satellite System (GNSS) solution.";
CM_ SG_ 2041 DAS_gpsFixTypeSoftwareSocB "Reports the fix type of the GPS software solution on System on Chip B (SOC-B).";
CM_ SG_ 2041 DAS_gpsSatsInUseSoftwareSocB "Reports the number of GPS satellites currently in use by software solution on System on Chip B (SOC-B).";
CM_ SG_ 2041 DAS_gnssNumSatsGps "Number of satellites visible from GPS constellation.";
CM_ SG_ 2041 DAS_gnssNumSatsGal "Number of satellites visible from GALILEO constellation.";
CM_ SG_ 2041 DAS_gnssNumSatsBds "Number of satellites visible from BEIDOU constellation.";
CM_ SG_ 2041 DAS_gnssAvgInstantaneousCnorGps "Average carrier-to-noise ratio among all satellites from GPS constellation on the high band as reported by the Positioning Engine on SOC-A.";
CM_ SG_ 2041 DAS_gnssAvgInstantaneousCnorGal "Average carrier-to-noise ratio among all satellites from GALILEO constellation on the high band.";
CM_ SG_ 2041 DAS_gnssAvgInstantaneousCnorBds "Average carrier-to-noise ratio among all satellites from BEIDOU constellation on the high band as reported by the Positioning Engine on SOC-A.";
CM_ SG_ 2041 DAS_gnssAvgInstantCnorGpsSocB "Driver assistance computer: gnss avg instant cnor gps soc b";
CM_ SG_ 2041 DAS_gnssAvgInstantCnorBdsSocB "Driver assistance computer: gnss avg instant cnor bds soc b";
CM_ SG_ 2041 DAS_gnssAvgInstantaneousCnorGpsL "Measures the average carrier-to-noise ratio among all satellites from GPS constellation on the low band as reported by the Positioning Engine on System on Chip A (SOC-A).";
CM_ SG_ 2041 DAS_gnssAvgInstantaneousCnorGalL "Measures the average carrier-to-noise ratio among all satellites from GALILEO constellation on the low band.";
CM_ SG_ 2041 DAS_gnssAvgInstantaneousCnorBdsL "Measures the average carrier-to-noise ratio among all satellites from BEIDOU constellation on the low band as reported by the Positioning Engine on System on Chip A (SOC-A).";
CM_ BO_ 777 "Driver assistance computer message: object";
CM_ SG_ 777 DAS_objectId "Driver assistance computer: object id";
CM_ SG_ 777 DAS_leadVehType "Driver assistance computer: lead veh type";
CM_ SG_ 777 DAS_leadVehRelevantForControl "Driver assistance computer: lead veh relevant for control";
CM_ SG_ 777 DAS_leadVehDx "Measures the distance to lead vehicle, or vehicle in the ego lane; raw 255 = signal not available (SNA)";
CM_ SG_ 777 DAS_leadVehVxRel "Driver assistance computer: lead veh vx rel; raw 15 = signal not available (SNA)";
CM_ SG_ 777 DAS_leadVehDy "Driver assistance computer: lead veh dy";
CM_ SG_ 777 DAS_leadVehId "Driver assistance computer: lead veh id; raw 127 = signal not available (SNA)";
CM_ SG_ 777 DAS_leadVeh2Type "Driver assistance computer: lead veh2 type";
CM_ SG_ 777 DAS_leadVeh2RelevantForControl "Driver assistance computer: lead veh2 relevant for control";
CM_ SG_ 777 DAS_leadVeh2Dx "Driver assistance computer: lead veh2 dx; raw 255 = signal not available (SNA)";
CM_ SG_ 777 DAS_leadVeh2VxRel "Driver assistance computer: lead veh2 vx rel; raw 15 = signal not available (SNA)";
CM_ SG_ 777 DAS_leadVeh2Dy "Driver assistance computer: lead veh2 dy";
CM_ SG_ 777 DAS_leadVeh2Id "Driver assistance computer: lead veh2 id; raw 0 = signal not available (SNA)";
CM_ SG_ 777 DAS_leftVehType "Driver assistance computer: left veh type";
CM_ SG_ 777 DAS_leftVehRelevantForControl "Driver assistance computer: left veh relevant for control";
CM_ SG_ 777 DAS_leftVehDx "Driver assistance computer: left veh dx; raw 255 = signal not available (SNA)";
CM_ SG_ 777 DAS_leftVehVxRel "Driver assistance computer: left veh vx rel; raw 15 = signal not available (SNA)";
CM_ SG_ 777 DAS_leftVehDy "Driver assistance computer: left veh dy";
CM_ SG_ 777 DAS_leftVehId "Driver assistance computer: left veh id; raw 127 = signal not available (SNA)";
CM_ SG_ 777 DAS_leftVeh2Type "Driver assistance computer: left veh2 type";
CM_ SG_ 777 DAS_leftVeh2RelevantForControl "Driver assistance computer: left veh2 relevant for control";
CM_ SG_ 777 DAS_leftVeh2Dx "Driver assistance computer: left veh2 dx; raw 255 = signal not available (SNA)";
CM_ SG_ 777 DAS_leftVeh2VxRel "Driver assistance computer: left veh2 vx rel; raw 15 = signal not available (SNA)";
CM_ SG_ 777 DAS_leftVeh2Dy "Driver assistance computer: left veh2 dy";
CM_ SG_ 777 DAS_leftVeh2Id "Driver assistance computer: left veh2 id; raw 0 = signal not available (SNA)";
CM_ SG_ 777 DAS_rightVehType "Driver assistance computer: right veh type";
CM_ SG_ 777 DAS_rightVehRelevantForControl "Driver assistance computer: right veh relevant for control";
CM_ SG_ 777 DAS_rightVehDx "Driver assistance computer: right veh dx; raw 255 = signal not available (SNA)";
CM_ SG_ 777 DAS_rightVehVxRel "Driver assistance computer: right veh vx rel; raw 15 = signal not available (SNA)";
CM_ SG_ 777 DAS_rightVehDy "Driver assistance computer: right veh dy";
CM_ SG_ 777 DAS_rightVehId "Driver assistance computer: right veh id; raw 127 = signal not available (SNA)";
CM_ SG_ 777 DAS_rightVeh2Type "Driver assistance computer: right veh2 type";
CM_ SG_ 777 DAS_rightVeh2RelevantForControl "Driver assistance computer: right veh2 relevant for control";
CM_ SG_ 777 DAS_rightVeh2Dx "Driver assistance computer: right veh2 dx; raw 255 = signal not available (SNA)";
CM_ SG_ 777 DAS_rightVeh2VxRel "Driver assistance computer: right veh2 vx rel; raw 15 = signal not available (SNA)";
CM_ SG_ 777 DAS_rightVeh2Dy "Driver assistance computer: right veh2 dy";
CM_ SG_ 777 DAS_rightVeh2Id "Driver assistance computer: right veh2 id; raw 0 = signal not available (SNA)";
CM_ SG_ 777 DAS_cutinVehType "Driver assistance computer: cutin veh type";
CM_ SG_ 777 DAS_cutinVehRelevantForControl "Driver assistance computer: cutin veh relevant for control";
CM_ SG_ 777 DAS_cutinVehDx "Driver assistance computer: cutin veh dx; raw 255 = signal not available (SNA)";
CM_ SG_ 777 DAS_cutinVehVxRel "Driver assistance computer: cutin veh vx rel; raw 15 = signal not available (SNA)";
CM_ SG_ 777 DAS_cutinVehDy "Driver assistance computer: cutin veh dy";
CM_ SG_ 777 DAS_cutinVehId "Driver assistance computer: cutin veh id; raw 127 = signal not available (SNA)";
CM_ SG_ 777 DAS_roadSignColor "Driver assistance computer: road sign color";
CM_ SG_ 777 DAS_roadSignId "Driver assistance computer: road sign id; raw 255 = signal not available (SNA)";
CM_ SG_ 777 DAS_roadSignStopLineDist "Driver assistance computer: road sign stop line dist; raw 1023 = signal not available (SNA)";
CM_ SG_ 777 DAS_roadSignControlActive "Driver assistance computer: road sign control active";
CM_ SG_ 777 DAS_roadSignSource "Driver assistance computer: road sign source";
CM_ SG_ 777 DAS_roadSignArrow "Driver assistance computer: road sign arrow";
CM_ SG_ 777 DAS_roadSignOrientation "Driver assistance computer: road sign orientation";
CM_ BO_ 1548 "Driver assistance computer message: telemetry radar";
CM_ SG_ 1548 DAS_TR_ObjIndex "Driver assistance computer: TR obj index";
CM_ SG_ 1548 DAS_TR_Counter "Driver assistance computer: TR counter";
CM_ SG_ 1548 DAS_TR_Obj00_Class "Driver assistance computer: TR obj00 class";
CM_ SG_ 1548 DAS_TR_Obj00_Dx "Driver assistance computer: TR obj00 dx";
CM_ SG_ 1548 DAS_TR_Obj00_Dy "Driver assistance computer: TR obj00 dy";
CM_ SG_ 1548 DAS_TR_Obj00_Vx "Driver assistance computer: TR obj00 vx";
CM_ SG_ 1548 DAS_TR_Obj00_RCS "Driver assistance computer: TR obj00 RCS";
CM_ SG_ 1548 DAS_TR_Obj00_Length "Driver assistance computer: TR obj00 length";
CM_ SG_ 1548 DAS_TR_Obj00_MovingState "Driver assistance computer: TR obj00 moving state";
CM_ SG_ 1548 DAS_TR_Obj00_Dz "Driver assistance computer: TR obj00 dz";
CM_ SG_ 1548 DAS_TR_Obj00_Exist "Driver assistance computer: TR obj00 exist";
CM_ BO_ 1318 "Front drive inverter message: alert log";
CM_ SG_ 1318 DIF_alertID "Front drive inverter: alert ID";
CM_ SG_ 1318 DIF_alertState "Front drive inverter: alert state";
CM_ SG_ 1318 DIF_a001_thermalWarning_H "Front drive inverter: a001 thermal warning h";
CM_ SG_ 1318 DIF_a001_thermalShutdown_H "Front drive inverter: a001 thermal shutdown h";
CM_ SG_ 1318 DIF_a001_undervoltVL_H "Front drive inverter: a001 undervolt VL h";
CM_ SG_ 1318 DIF_a001_undervoltVH_H "Front drive inverter: a001 undervolt VH h";
CM_ SG_ 1318 DIF_a001_sense_H "Front drive inverter: a001 sense h";
CM_ SG_ 1318 DIF_a001_desat_H "Front drive inverter: a001 desat h";
CM_ SG_ 1318 DIF_a001_overvoltVL_H "Front drive inverter: a001 overvolt VL h";
CM_ SG_ 1318 DIF_a001_overvoltVH_H "Front drive inverter: a001 overvolt VH h";
CM_ SG_ 1318 DIF_a001_undervoltVCC_H "Front drive inverter: a001 undervolt VCC h";
CM_ SG_ 1318 DIF_a001_asynchStop_H "Front drive inverter: a001 asynch stop h";
CM_ SG_ 1318 DIF_a001_remoteRegError_H "Front drive inverter: a001 remote reg error h";
CM_ SG_ 1318 DIF_a001_undervoltVDD_H "Front drive inverter: a001 undervolt VDD h";
CM_ SG_ 1318 DIF_a001_overvoltVDD_H "Front drive inverter: a001 overvolt VDD h";
CM_ SG_ 1318 DIF_a001_localRegError_H "Front drive inverter: a001 local reg error h";
CM_ SG_ 1318 DIF_a001_spiError_H "Front drive inverter: a001 spi error h";
CM_ SG_ 1318 DIF_a001_deadtimeError_H "Front drive inverter: a001 deadtime error h";
CM_ SG_ 1318 DIF_a001_thermalWarning_L "Front drive inverter: a001 thermal warning l";
CM_ SG_ 1318 DIF_a001_thermalShutdown_L "Front drive inverter: a001 thermal shutdown l";
CM_ SG_ 1318 DIF_a001_undervoltVL_L "Front drive inverter: a001 undervolt VL l";
CM_ SG_ 1318 DIF_a001_undervoltVH_L "Front drive inverter: a001 undervolt VH l";
CM_ SG_ 1318 DIF_a001_sense_L "Front drive inverter: a001 sense l";
CM_ SG_ 1318 DIF_a001_desat_L "Front drive inverter: a001 desat l";
CM_ SG_ 1318 DIF_a001_overvoltVL_L "Front drive inverter: a001 overvolt VL l";
CM_ SG_ 1318 DIF_a001_overvoltVH_L "Front drive inverter: a001 overvolt VH l";
CM_ SG_ 1318 DIF_a001_undervoltVCC_L "Front drive inverter: a001 undervolt VCC l";
CM_ SG_ 1318 DIF_a001_asynchStop_L "Front drive inverter: a001 asynch stop l";
CM_ SG_ 1318 DIF_a001_remoteRegError_L "Front drive inverter: a001 remote reg error l";
CM_ SG_ 1318 DIF_a001_undervoltVDD_L "Front drive inverter: a001 undervolt VDD l";
CM_ SG_ 1318 DIF_a001_overvoltVDD_L "Front drive inverter: a001 overvolt VDD l";
CM_ SG_ 1318 DIF_a001_localRegError_L "Front drive inverter: a001 local reg error l";
CM_ SG_ 1318 DIF_a001_spiError_L "Front drive inverter: a001 spi error l";
CM_ SG_ 1318 DIF_a001_deadtimeError_L "Front drive inverter: a001 deadtime error l";
CM_ SG_ 1318 DIF_a001_gateDriveErrCounter "Front drive inverter: a001 gate drive err counter";
CM_ SG_ 1318 DIF_a001_remoteCommError_H "Front drive inverter: a001 remote comm error h";
CM_ SG_ 1318 DIF_a001_localCommError_H "Front drive inverter: a001 local comm error h";
CM_ SG_ 1318 DIF_a001_remoteReset_H "Front drive inverter: a001 remote reset h";
CM_ SG_ 1318 DIF_a001_localReset_H "Front drive inverter: a001 local reset h";
CM_ SG_ 1318 DIF_a001_remoteCommError_L "Front drive inverter: a001 remote comm error l";
CM_ SG_ 1318 DIF_a001_localCommError_L "Front drive inverter: a001 local comm error l";
CM_ SG_ 1318 DIF_a001_remoteReset_L "Front drive inverter: a001 remote reset l";
CM_ SG_ 1318 DIF_a001_localReset_L "Front drive inverter: a001 local reset l";
CM_ SG_ 1318 DIF_a001_faultLine1Gpio_H "Front drive inverter: a001 fault line1 gpio h";
CM_ SG_ 1318 DIF_a001_faultLine1Gpio_L "Front drive inverter: a001 fault line1 gpio l";
CM_ SG_ 1318 DIF_a002_thermalWarning_H "Front drive inverter: a002 thermal warning h";
CM_ SG_ 1318 DIF_a002_thermalShutdown_H "Front drive inverter: a002 thermal shutdown h";
CM_ SG_ 1318 DIF_a002_undervoltVL_H "Front drive inverter: a002 undervolt VL h";
CM_ SG_ 1318 DIF_a002_undervoltVH_H "Front drive inverter: a002 undervolt VH h";
CM_ SG_ 1318 DIF_a002_sense_H "Front drive inverter: a002 sense h";
CM_ SG_ 1318 DIF_a002_desat_H "Front drive inverter: a002 desat h";
CM_ SG_ 1318 DIF_a002_overvoltVL_H "Front drive inverter: a002 overvolt VL h";
CM_ SG_ 1318 DIF_a002_overvoltVH_H "Front drive inverter: a002 overvolt VH h";
CM_ SG_ 1318 DIF_a002_undervoltVCC_H "Front drive inverter: a002 undervolt VCC h";
CM_ SG_ 1318 DIF_a002_asynchStop_H "Front drive inverter: a002 asynch stop h";
CM_ SG_ 1318 DIF_a002_remoteRegError_H "Front drive inverter: a002 remote reg error h";
CM_ SG_ 1318 DIF_a002_undervoltVDD_H "Front drive inverter: a002 undervolt VDD h";
CM_ SG_ 1318 DIF_a002_overvoltVDD_H "Front drive inverter: a002 overvolt VDD h";
CM_ SG_ 1318 DIF_a002_localRegError_H "Front drive inverter: a002 local reg error h";
CM_ SG_ 1318 DIF_a002_spiError_H "Front drive inverter: a002 spi error h";
CM_ SG_ 1318 DIF_a002_deadtimeError_H "Front drive inverter: a002 deadtime error h";
CM_ SG_ 1318 DIF_a002_thermalWarning_L "Front drive inverter: a002 thermal warning l";
CM_ SG_ 1318 DIF_a002_thermalShutdown_L "Front drive inverter: a002 thermal shutdown l";
CM_ SG_ 1318 DIF_a002_undervoltVL_L "Front drive inverter: a002 undervolt VL l";
CM_ SG_ 1318 DIF_a002_undervoltVH_L "Front drive inverter: a002 undervolt VH l";
CM_ SG_ 1318 DIF_a002_sense_L "Front drive inverter: a002 sense l";
CM_ SG_ 1318 DIF_a002_desat_L "Front drive inverter: a002 desat l";
CM_ SG_ 1318 DIF_a002_overvoltVL_L "Front drive inverter: a002 overvolt VL l";
CM_ SG_ 1318 DIF_a002_overvoltVH_L "Front drive inverter: a002 overvolt VH l";
CM_ SG_ 1318 DIF_a002_undervoltVCC_L "Front drive inverter: a002 undervolt VCC l";
CM_ SG_ 1318 DIF_a002_asynchStop_L "Front drive inverter: a002 asynch stop l";
CM_ SG_ 1318 DIF_a002_remoteRegError_L "Front drive inverter: a002 remote reg error l";
CM_ SG_ 1318 DIF_a002_undervoltVDD_L "Front drive inverter: a002 undervolt VDD l";
CM_ SG_ 1318 DIF_a002_overvoltVDD_L "Front drive inverter: a002 overvolt VDD l";
CM_ SG_ 1318 DIF_a002_localRegError_L "Front drive inverter: a002 local reg error l";
CM_ SG_ 1318 DIF_a002_spiError_L "Front drive inverter: a002 spi error l";
CM_ SG_ 1318 DIF_a002_deadtimeError_L "Front drive inverter: a002 deadtime error l";
CM_ SG_ 1318 DIF_a002_gateDriveErrCounter "Front drive inverter: a002 gate drive err counter";
CM_ SG_ 1318 DIF_a002_selftestDesat_L "Front drive inverter: a002 selftest desat l";
CM_ SG_ 1318 DIF_a002_selftestDesat_H "Front drive inverter: a002 selftest desat h";
CM_ SG_ 1318 DIF_a002_remoteCommError_H "Front drive inverter: a002 remote comm error h";
CM_ SG_ 1318 DIF_a002_localCommError_H "Front drive inverter: a002 local comm error h";
CM_ SG_ 1318 DIF_a002_remoteReset_H "Front drive inverter: a002 remote reset h";
CM_ SG_ 1318 DIF_a002_localReset_H "Front drive inverter: a002 local reset h";
CM_ SG_ 1318 DIF_a002_remoteCommError_L "Front drive inverter: a002 remote comm error l";
CM_ SG_ 1318 DIF_a002_localCommError_L "Front drive inverter: a002 local comm error l";
CM_ SG_ 1318 DIF_a002_remoteReset_L "Front drive inverter: a002 remote reset l";
CM_ SG_ 1318 DIF_a002_localReset_L "Front drive inverter: a002 local reset l";
CM_ SG_ 1318 DIF_a002_faultLine1Gpio_H "Front drive inverter: a002 fault line1 gpio h";
CM_ SG_ 1318 DIF_a002_faultLine1Gpio_L "Front drive inverter: a002 fault line1 gpio l";
CM_ SG_ 1318 DIF_a003_thermalWarning_H "Front drive inverter: a003 thermal warning h";
CM_ SG_ 1318 DIF_a003_thermalShutdown_H "Front drive inverter: a003 thermal shutdown h";
CM_ SG_ 1318 DIF_a003_undervoltVL_H "Front drive inverter: a003 undervolt VL h";
CM_ SG_ 1318 DIF_a003_undervoltVH_H "Front drive inverter: a003 undervolt VH h";
CM_ SG_ 1318 DIF_a003_sense_H "Front drive inverter: a003 sense h";
CM_ SG_ 1318 DIF_a003_desat_H "Front drive inverter: a003 desat h";
CM_ SG_ 1318 DIF_a003_overvoltVL_H "Front drive inverter: a003 overvolt VL h";
CM_ SG_ 1318 DIF_a003_overvoltVH_H "Front drive inverter: a003 overvolt VH h";
CM_ SG_ 1318 DIF_a003_undervoltVCC_H "Front drive inverter: a003 undervolt VCC h";
CM_ SG_ 1318 DIF_a003_asynchStop_H "Front drive inverter: a003 asynch stop h";
CM_ SG_ 1318 DIF_a003_remoteRegError_H "Front drive inverter: a003 remote reg error h";
CM_ SG_ 1318 DIF_a003_undervoltVDD_H "Front drive inverter: a003 undervolt VDD h";
CM_ SG_ 1318 DIF_a003_overvoltVDD_H "Front drive inverter: a003 overvolt VDD h";
CM_ SG_ 1318 DIF_a003_localRegError_H "Front drive inverter: a003 local reg error h";
CM_ SG_ 1318 DIF_a003_spiError_H "Front drive inverter: a003 spi error h";
CM_ SG_ 1318 DIF_a003_deadtimeError_H "Front drive inverter: a003 deadtime error h";
CM_ SG_ 1318 DIF_a003_thermalWarning_L "Front drive inverter: a003 thermal warning l";
CM_ SG_ 1318 DIF_a003_thermalShutdown_L "Front drive inverter: a003 thermal shutdown l";
CM_ SG_ 1318 DIF_a003_undervoltVL_L "Front drive inverter: a003 undervolt VL l";
CM_ SG_ 1318 DIF_a003_undervoltVH_L "Front drive inverter: a003 undervolt VH l";
CM_ SG_ 1318 DIF_a003_sense_L "Front drive inverter: a003 sense l";
CM_ SG_ 1318 DIF_a003_desat_L "Front drive inverter: a003 desat l";
CM_ SG_ 1318 DIF_a003_overvoltVL_L "Front drive inverter: a003 overvolt VL l";
CM_ SG_ 1318 DIF_a003_overvoltVH_L "Front drive inverter: a003 overvolt VH l";
CM_ SG_ 1318 DIF_a003_undervoltVCC_L "Front drive inverter: a003 undervolt VCC l";
CM_ SG_ 1318 DIF_a003_asynchStop_L "Front drive inverter: a003 asynch stop l";
CM_ SG_ 1318 DIF_a003_remoteRegError_L "Front drive inverter: a003 remote reg error l";
CM_ SG_ 1318 DIF_a003_undervoltVDD_L "Front drive inverter: a003 undervolt VDD l";
CM_ SG_ 1318 DIF_a003_overvoltVDD_L "Front drive inverter: a003 overvolt VDD l";
CM_ SG_ 1318 DIF_a003_localRegError_L "Front drive inverter: a003 local reg error l";
CM_ SG_ 1318 DIF_a003_spiError_L "Front drive inverter: a003 spi error l";
CM_ SG_ 1318 DIF_a003_deadtimeError_L "Front drive inverter: a003 deadtime error l";
CM_ SG_ 1318 DIF_a003_gateDriveErrCounter "Front drive inverter: a003 gate drive err counter";
CM_ SG_ 1318 DIF_a003_selftestDesat_L "Front drive inverter: a003 selftest desat l";
CM_ SG_ 1318 DIF_a003_selftestDesat_H "Front drive inverter: a003 selftest desat h";
CM_ SG_ 1318 DIF_a003_remoteCommError_H "Front drive inverter: a003 remote comm error h";
CM_ SG_ 1318 DIF_a003_localCommError_H "Front drive inverter: a003 local comm error h";
CM_ SG_ 1318 DIF_a003_remoteReset_H "Front drive inverter: a003 remote reset h";
CM_ SG_ 1318 DIF_a003_localReset_H "Front drive inverter: a003 local reset h";
CM_ SG_ 1318 DIF_a003_remoteCommError_L "Front drive inverter: a003 remote comm error l";
CM_ SG_ 1318 DIF_a003_localCommError_L "Front drive inverter: a003 local comm error l";
CM_ SG_ 1318 DIF_a003_remoteReset_L "Front drive inverter: a003 remote reset l";
CM_ SG_ 1318 DIF_a003_localReset_L "Front drive inverter: a003 local reset l";
CM_ SG_ 1318 DIF_a003_faultLine1Gpio_H "Front drive inverter: a003 fault line1 gpio h";
CM_ SG_ 1318 DIF_a003_faultLine1Gpio_L "Front drive inverter: a003 fault line1 gpio l";
CM_ SG_ 1318 DIF_a007_phaseAcurrent "Front drive inverter: a007 phase acurrent";
CM_ SG_ 1318 DIF_a007_phaseBcurrent "Front drive inverter: a007 phase bcurrent";
CM_ SG_ 1318 DIF_a007_offsetError "Front drive inverter: a007 offset error";
CM_ SG_ 1318 DIF_a007_idFdbStdDeviation "Front drive inverter: a007 id fdb std deviation";
CM_ SG_ 1318 DIF_a007_iqFdbStdDeviation "Front drive inverter: a007 iq fdb std deviation";
CM_ SG_ 1318 DIF_a007_motorShift "Front drive inverter: a007 motor shift";
CM_ SG_ 1318 DIF_a007_motorShort "Front drive inverter: a007 motor short";
CM_ SG_ 1318 DIF_a010_sccReset "Front drive inverter: a010 scc reset";
CM_ SG_ 1318 DIF_a010_hibernate "Front drive inverter: a010 hibernate";
CM_ SG_ 1318 DIF_a010_hwBist "Front drive inverter: a010 hw bist";
CM_ SG_ 1318 DIF_a010_nmiWatchdog "Front drive inverter: a010 nmi watchdog";
CM_ SG_ 1318 DIF_a010_watchdog "Front drive inverter: a010 watchdog";
CM_ SG_ 1318 DIF_a010_clockFailNmi "Front drive inverter: a010 clock fail nmi";
CM_ SG_ 1318 DIF_a010_ramUncErrorNmi "Front drive inverter: a010 ram unc error nmi";
CM_ SG_ 1318 DIF_a010_flashUncErrorNmi "Front drive inverter: a010 flash unc error nmi";
CM_ SG_ 1318 DIF_a010_cpu1signMismatchNmi "Front drive inverter: a010 cpu1sign mismatch nmi";
CM_ SG_ 1318 DIF_a010_cpu2signMismatchNmi "Front drive inverter: a010 cpu2sign mismatch nmi";
CM_ SG_ 1318 DIF_a010_pieVectErrorNmi "Front drive inverter: a010 pie vect error nmi";
CM_ SG_ 1318 DIF_a010_sysDbgNmi "Front drive inverter: a010 sys dbg nmi";
CM_ SG_ 1318 DIF_a010_rlNmi "Front drive inverter: a010 rl nmi";
CM_ SG_ 1318 DIF_a010_ovfNmi "Front drive inverter: a010 ovf nmi";
CM_ SG_ 1318 DIF_a010_wdtFlags "Front drive inverter: a010 wdt flags";
CM_ SG_ 1318 DIF_a011_reason "Front drive inverter: a011 reason";
CM_ SG_ 1318 DIF_a011_phaseAHigh "Front drive inverter: a011 phase a high";
CM_ SG_ 1318 DIF_a011_phaseALow "Front drive inverter: a011 phase a low";
CM_ SG_ 1318 DIF_a011_phaseBHigh "Front drive inverter: a011 phase b high";
CM_ SG_ 1318 DIF_a011_phaseBLow "Front drive inverter: a011 phase b low";
CM_ SG_ 1318 DIF_a011_phaseCHigh "Front drive inverter: a011 phase c high";
CM_ SG_ 1318 DIF_a011_phaseCLow "Front drive inverter: a011 phase c low";
CM_ SG_ 1318 DIF_a011_regAddress "Front drive inverter: a011 reg address";
CM_ SG_ 1318 DIF_a011_badGateDriveIC "Front drive inverter: a011 bad gate drive IC";
CM_ SG_ 1318 DIF_a011_badDataRead "Front drive inverter: a011 bad data read";
CM_ SG_ 1318 DIF_a011_badDataExpected "Front drive inverter: a011 bad data expected";
CM_ SG_ 1318 DIF_a011_codeBranch "Front drive inverter: a011 code branch";
CM_ SG_ 1318 DIF_a012_hvilStatus "Front drive inverter: a012 hvil status; raw 3 = signal not available (SNA)";
CM_ SG_ 1318 DIF_a012_hvilCmVoltage "Front drive inverter: a012 hvil cm voltage";
CM_ SG_ 1318 DIF_a012_hvilCurrent "Front drive inverter: a012 hvil current";
CM_ SG_ 1318 DIF_a012_hvilFaultGpio "Front drive inverter: a012 hvil fault gpio";
CM_ SG_ 1318 DIF_a012_hvilSupplyPinDI "Front drive inverter: a012 hvil supply pin DI";
CM_ SG_ 1318 DIF_a012_hvilSupplyPinPM "Front drive inverter: a012 hvil supply pin PM";
CM_ SG_ 1318 DIF_a012_activeDisOn3V3 "Front drive inverter: a012 active dis on3 V3";
CM_ SG_ 1318 DIF_a012_hvilHeaderFault "Front drive inverter: a012 hvil header fault";
CM_ SG_ 1318 DIF_a013_address "Front drive inverter: a013 address";
CM_ SG_ 1318 DIF_a013_errorType "Front drive inverter: a013 error type";
CM_ SG_ 1318 DIF_a014_motorSpeed "Front drive inverter: a014 motor speed";
CM_ SG_ 1318 DIF_a014_adState "Front drive inverter: a014 ad state";
CM_ SG_ 1318 DIF_a014_torqueCommandFwd "Front drive inverter: a014 torque command fwd";
CM_ SG_ 1318 DIF_a014_brakeMasterCylPress "Front drive inverter: a014 brake master cyl press";
CM_ SG_ 1318 DIF_a014_rmsTorqueError "Front drive inverter: a014 rms torque error";
CM_ SG_ 1318 DIF_a014_tcEnabled "Front drive inverter: a014 tc enabled";
CM_ SG_ 1318 DIF_a016_newSafeState "Front drive inverter: a016 new safe state";
CM_ SG_ 1318 DIF_a016_oldSafeState "Front drive inverter: a016 old safe state";
CM_ SG_ 1318 DIF_a016_gateDriveFaultLine "Front drive inverter: a016 gate drive fault line";
CM_ SG_ 1318 DIF_a016_ascMonitor "Front drive inverter: a016 asc monitor";
CM_ SG_ 1318 DIF_a016_uncontrolledRegenZone "Front drive inverter: a016 uncontrolled regen zone";
CM_ SG_ 1318 DIF_a016_pedalMonitorPreWatchdog "Front drive inverter: a016 pedal monitor pre watchdog";
CM_ SG_ 1318 DIF_a016_motorRPM "Front drive inverter: a016 motor RPM";
CM_ SG_ 1318 DIF_a016_torqueMotor "Front drive inverter: a016 torque motor";
CM_ SG_ 1318 DIF_a016_safetyICfaultLine "Front drive inverter: a016 safety i cfault line";
CM_ SG_ 1318 DIF_a016_triggerEvent "Front drive inverter: a016 trigger event";
CM_ SG_ 1318 DIF_a024_vBat "Front drive inverter: a024 v bat";
CM_ SG_ 1318 DIF_a024_failReason "Front drive inverter: a024 fail reason";
CM_ SG_ 1318 DIF_a024_state "Front drive inverter: a024 state";
CM_ SG_ 1318 DIF_a024_Ia "Front drive inverter: a024 ia";
CM_ SG_ 1318 DIF_a024_Ib "Front drive inverter: a024 ib";
CM_ SG_ 1318 DIF_a024_maxCurrMagSqrd "Front drive inverter: a024 max curr mag sqrd";
CM_ SG_ 1318 DIF_a024_rotorAngle "Front drive inverter: a024 rotor angle";
CM_ SG_ 1318 DIF_a025_Ia "Front drive inverter: a025 ia";
CM_ SG_ 1318 DIF_a025_torqueMotor "Front drive inverter: a025 torque motor";
CM_ SG_ 1318 DIF_a025_motorSpeed "Front drive inverter: a025 motor speed";
CM_ SG_ 1318 DIF_a026_Ib "Front drive inverter: a026 ib";
CM_ SG_ 1318 DIF_a026_torqueMotor "Front drive inverter: a026 torque motor";
CM_ SG_ 1318 DIF_a026_motorSpeed "Front drive inverter: a026 motor speed";
CM_ SG_ 1318 DIF_a027_Ic "Front drive inverter: a027 ic";
CM_ SG_ 1318 DIF_a027_torqueMotor "Front drive inverter: a027 torque motor";
CM_ SG_ 1318 DIF_a027_motorSpeed "Front drive inverter: a027 motor speed";
CM_ SG_ 1318 DIF_a028_phaseAirms "Front drive inverter: a028 phase airms";
CM_ SG_ 1318 DIF_a028_iArmsTorque "Front drive inverter: a028 i arms torque";
CM_ SG_ 1318 DIF_a028_iArmsSpeed "Front drive inverter: a028 i arms speed";
CM_ SG_ 1318 DIF_a029_phaseBirms "Front drive inverter: a029 phase birms";
CM_ SG_ 1318 DIF_a029_iBrmsTorque "Front drive inverter: a029 i brms torque";
CM_ SG_ 1318 DIF_a029_iBrmsSpeed "Front drive inverter: a029 i brms speed";
CM_ SG_ 1318 DIF_a030_phaseCirms "Front drive inverter: a030 phase cirms";
CM_ SG_ 1318 DIF_a030_iCrmsTorque "Front drive inverter: a030 i crms torque";
CM_ SG_ 1318 DIF_a030_iCrmsSpeed "Front drive inverter: a030 i crms speed";
CM_ SG_ 1318 DIF_a031_phaseAoffset "Front drive inverter: a031 phase aoffset";
CM_ SG_ 1318 DIF_a032_phaseBoffset "Front drive inverter: a032 phase boffset";
CM_ SG_ 1318 DIF_a033_phaseAcurrent "Front drive inverter: a033 phase acurrent";
CM_ SG_ 1318 DIF_a033_deltaIa "Front drive inverter: a033 delta ia";
CM_ SG_ 1318 DIF_a033_vRefIa "Front drive inverter: a033 v ref ia";
CM_ SG_ 1318 DIF_a034_phaseBcurrent "Front drive inverter: a034 phase bcurrent";
CM_ SG_ 1318 DIF_a034_deltaIb "Front drive inverter: a034 delta ib";
CM_ SG_ 1318 DIF_a034_vRefIb "Front drive inverter: a034 v ref ib";
CM_ SG_ 1318 DIF_a035_phaseAerror "Front drive inverter: a035 phase aerror";
CM_ SG_ 1318 DIF_a035_phaseBerror "Front drive inverter: a035 phase berror";
CM_ SG_ 1318 DIF_a035_phaseCerror "Front drive inverter: a035 phase cerror";
CM_ SG_ 1318 DIF_a035_standbyCurrent "Front drive inverter: a035 standby current";
CM_ SG_ 1318 DIF_a035_unbalancedCurrent "Front drive inverter: a035 unbalanced current";
CM_ SG_ 1318 DIF_a035_wontMoveCurrent "Front drive inverter: a035 wont move current";
CM_ SG_ 1318 DIF_a035_reportingPhase "Front drive inverter: a035 reporting phase";
CM_ SG_ 1318 DIF_a035_noDriveCurrent "Front drive inverter: a035 no drive current";
CM_ SG_ 1318 DIF_a035_phaseDifference "Front drive inverter: a035 phase difference";
CM_ SG_ 1318 DIF_a035_phaseCurrent "Front drive inverter: a035 phase current";
CM_ SG_ 1318 DIF_a035_frequency "Front drive inverter: a035 frequency";
CM_ SG_ 1318 DIF_a036_busVoltage "Front drive inverter: a036 bus voltage";
CM_ SG_ 1318 DIF_a036_busHighLimit "Front drive inverter: a036 bus high limit";
CM_ SG_ 1318 DIF_a037_busVoltage "Front drive inverter: a037 bus voltage";
CM_ SG_ 1318 DIF_a037_busLowLimit "Front drive inverter: a037 bus low limit";
CM_ SG_ 1318 DIF_a038_vBMS "Front drive inverter: a038 v BMS";
CM_ SG_ 1318 DIF_a038_vBat "Front drive inverter: a038 v bat";
CM_ SG_ 1318 DIF_a038_iBat "Front drive inverter: a038 i bat";
CM_ SG_ 1318 DIF_a038_reason "Front drive inverter: a038 reason";
CM_ SG_ 1318 DIF_a040_torque "Front drive inverter: a040 torque";
CM_ SG_ 1318 DIF_a040_capability "Front drive inverter: a040 capability";
CM_ SG_ 1318 DIF_a040_power "Front drive inverter: a040 power";
CM_ SG_ 1318 DIF_a040_status "Front drive inverter: a040 status";
CM_ SG_ 1318 DIF_a040_capability2 "Front drive inverter: a040 capability2";
CM_ SG_ 1318 DIF_a040_hvStatus "Front drive inverter: a040 hv status";
CM_ SG_ 1318 DIF_a040_temperature "Front drive inverter: a040 temperature";
CM_ SG_ 1318 DIF_a041_uartRxDataAvailable "Front drive inverter: a041 uart rx data available";
CM_ SG_ 1318 DIF_a041_SDC_status_MIA "Front drive inverter: a041 SDC status MIA";
CM_ SG_ 1318 DIF_a041_diUartRxVersion "Front drive inverter: a041 di uart rx version";
CM_ SG_ 1318 DIF_a041_sdcUartRxVersion "Front drive inverter: a041 sdc uart rx version";
CM_ SG_ 1318 DIF_a043_outletTemp "Front drive inverter: a043 outlet temp";
CM_ SG_ 1318 DIF_a044_outletTemp "Front drive inverter: a044 outlet temp";
CM_ SG_ 1318 DIF_a045_inletTemp "Front drive inverter: a045 inlet temp";
CM_ SG_ 1318 DIF_a045_outletTemp "Front drive inverter: a045 outlet temp";
CM_ SG_ 1318 DIF_a045_heatsinkTemp "Front drive inverter: a045 heatsink temp";
CM_ SG_ 1318 DIF_a045_outletTempSlope "Front drive inverter: a045 outlet temp slope";
CM_ SG_ 1318 DIF_a046_statorTemp1 "Front drive inverter: a046 stator temp1";
CM_ SG_ 1318 DIF_a046_statorTemp2 "Front drive inverter: a046 stator temp2";
CM_ SG_ 1318 DIF_a047_statorTemp1 "Front drive inverter: a047 stator temp1";
CM_ SG_ 1318 DIF_a047_statorTslope1 "Front drive inverter: a047 stator tslope1";
CM_ SG_ 1318 DIF_a050_statorTemp1 "Front drive inverter: a050 stator temp1";
CM_ SG_ 1318 DIF_a050_statorTemp2 "Front drive inverter: a050 stator temp2";
CM_ SG_ 1318 DIF_a052_torque "Front drive inverter: a052 torque";
CM_ SG_ 1318 DIF_a052_capability "Front drive inverter: a052 capability";
CM_ SG_ 1318 DIF_a052_power "Front drive inverter: a052 power";
CM_ SG_ 1318 DIF_a052_status "Front drive inverter: a052 status";
CM_ SG_ 1318 DIF_a052_capability2 "Front drive inverter: a052 capability2";
CM_ SG_ 1318 DIF_a052_hvStatus "Front drive inverter: a052 hv status";
CM_ SG_ 1318 DIF_a052_temperature "Front drive inverter: a052 temperature";
CM_ SG_ 1318 DIF_a054_outletTemp "Front drive inverter: a054 outlet temp";
CM_ SG_ 1318 DIF_a054_heatsinkTemp "Front drive inverter: a054 heatsink temp";
CM_ SG_ 1318 DIF_a055_parameterDI "Front drive inverter: a055 parameter DI";
CM_ SG_ 1318 DIF_a055_parameterPM "Front drive inverter: a055 parameter PM";
CM_ SG_ 1318 DIF_a055_torqueType "Front drive inverter: a055 torque type";
CM_ SG_ 1318 DIF_a055_motorRPM "Front drive inverter: a055 motor RPM";
CM_ SG_ 1318 DIF_a056_pcbTemp "Front drive inverter: a056 pcb temp";
CM_ SG_ 1318 DIF_a057_pcbTemp "Front drive inverter: a057 pcb temp";
CM_ SG_ 1318 DIF_a058_pcbTemp "Front drive inverter: a058 pcb temp";
CM_ SG_ 1318 DIF_a058_outletTemp "Front drive inverter: a058 outlet temp";
CM_ SG_ 1318 DIF_a058_heatsinkTemp "Front drive inverter: a058 heatsink temp";
CM_ SG_ 1318 DIF_a058_pcbTempSlope "Front drive inverter: a058 pcb temp slope";
CM_ SG_ 1318 DIF_a059_heatsinkTemp "Front drive inverter: a059 heatsink temp";
CM_ SG_ 1318 DIF_a060_heatsinkTemp "Front drive inverter: a060 heatsink temp";
CM_ SG_ 1318 DIF_a061_sensor "Front drive inverter: a061 sensor";
CM_ SG_ 1318 DIF_a061_reason "Front drive inverter: a061 reason";
CM_ SG_ 1318 DIF_a061_phTemp "Front drive inverter: a061 ph temp";
CM_ SG_ 1318 DIF_a061_otherTemp "Front drive inverter: a061 other temp";
CM_ SG_ 1318 DIF_a062_limpReason "Front drive inverter: a062 limp reason";
CM_ SG_ 1318 DIF_a063_BB_status "Front drive inverter: a063 BB status";
CM_ SG_ 1318 DIF_a064_interventionType "Front drive inverter: a064 intervention type";
CM_ SG_ 1318 DIF_a064_torqueCmdState "Front drive inverter: a064 torque cmd state; raw 0 = signal not available (SNA)";
CM_ SG_ 1318 DIF_a066_badValue1 "Front drive inverter: a066 bad value1";
CM_ SG_ 1318 DIF_a066_badValue2 "Front drive inverter: a066 bad value2";
CM_ SG_ 1318 DIF_a066_canID "Front drive inverter: a066 can ID";
CM_ SG_ 1318 DIF_a066_errorType "Front drive inverter: a066 error type";
CM_ SG_ 1318 DIF_a069_motorSpeed "Front drive inverter: a069 motor speed";
CM_ SG_ 1318 DIF_a069_rotorCoolingPower "Front drive inverter: a069 rotor cooling power";
CM_ SG_ 1318 DIF_a069_rotorMagnetTemp "Front drive inverter: a069 rotor magnet temp";
CM_ SG_ 1318 DIF_a069_fittedTorqueLimit "Front drive inverter: a069 fitted torque limit";
CM_ SG_ 1318 DIF_a072_reason "Front drive inverter: a072 reason";
CM_ SG_ 1318 DIF_a073_motorSpeedrpm "Front drive inverter: a073 motor speedrpm";
CM_ SG_ 1318 DIF_a075_motorSpeed "Front drive inverter: a075 motor speed";
CM_ SG_ 1318 DIF_a075_absSpeed "Front drive inverter: a075 abs speed";
CM_ SG_ 1318 DIF_a076_lvSupplyV "Front drive inverter: a076 lv supply v";
CM_ SG_ 1318 DIF_a077_lvSupplyV "Front drive inverter: a077 lv supply v";
CM_ SG_ 1318 DIF_a078_adcRefChan "Front drive inverter: a078 adc ref chan";
CM_ SG_ 1318 DIF_a078_adcRefLowAvg "Front drive inverter: a078 adc ref low avg";
CM_ SG_ 1318 DIF_a079_adcRefChan "Front drive inverter: a079 adc ref chan";
CM_ SG_ 1318 DIF_a079_adcRefHighAvg "Front drive inverter: a079 adc ref high avg";
CM_ SG_ 1318 DIF_a087_gtwCarConfig "Front drive inverter: a087 gtw car config";
CM_ SG_ 1318 DIF_a087_gtwTime "Front drive inverter: a087 gtw time";
CM_ SG_ 1318 DIF_a087_gtwUpdateStatus "Front drive inverter: a087 gtw update status";
CM_ SG_ 1318 DIF_a087_gearControl "Front drive inverter: a087 gear control";
CM_ SG_ 1318 DIF_a087_carState "Front drive inverter: a087 car state";
CM_ SG_ 1318 DIF_a090_reason "Front drive inverter: a090 reason";
CM_ SG_ 1318 DIF_a090_systemState "Front drive inverter: a090 system state";
CM_ SG_ 1318 DIF_a090_state "Front drive inverter: a090 state";
CM_ SG_ 1318 DIF_a090_locState "Front drive inverter: a090 loc state";
CM_ SG_ 1318 DIF_a090_state2 "Front drive inverter: a090 state2";
CM_ SG_ 1318 DIF_a090_state4 "Front drive inverter: a090 state4";
CM_ SG_ 1318 DIF_a091_ESP_brakeTorque "Front drive inverter: a091 ESP brake torque";
CM_ SG_ 1318 DIF_a091_ESP_wheelSpeeds "Front drive inverter: a091 ESP wheel speeds";
CM_ SG_ 1318 DIF_a091_ESP_wheelRotation "Front drive inverter: a091 ESP wheel rotation";
CM_ SG_ 1318 DIF_a091_ESP_motorLimits "Front drive inverter: a091 ESP motor limits";
CM_ SG_ 1318 DIF_a091_ESP_offsets "Front drive inverter: a091 ESP offsets";
CM_ SG_ 1318 DIF_a091_ESP_status "Front drive inverter: a091 ESP status";
CM_ SG_ 1318 DIF_a091_ESP_party3 "Front drive inverter: a091 ESP party3";
CM_ SG_ 1318 DIF_a092_bmsStatus "Front drive inverter: a092 bms status";
CM_ SG_ 1318 DIF_a092_bmsDriveLimits "Front drive inverter: a092 bms drive limits";
CM_ SG_ 1318 DIF_a092_bmsHvBusStatus "Front drive inverter: a092 bms hv bus status";
CM_ SG_ 1318 DIF_a092_bmsPowerAvailable "Front drive inverter: a092 bms power available";
CM_ SG_ 1318 DIF_a092_bmsBmbMinMax "Front drive inverter: a092 bms bmb min max";
CM_ SG_ 1318 DIF_a092_bmsSocStatus "Front drive inverter: a092 bms soc status";
CM_ SG_ 1318 DIF_a092_bmsThermalStatus "Front drive inverter: a092 bms thermal status";
CM_ SG_ 1318 DIF_a092_bmsCtrStatus "Front drive inverter: a092 bms ctr status";
CM_ SG_ 1318 DIF_a092_bmsVoltageRegGain "Front drive inverter: a092 bms voltage reg gain";
CM_ SG_ 1318 DIF_a092_bmsPackConfig "Front drive inverter: a092 bms pack config";
CM_ SG_ 1318 DIF_a092_bmsSystemStatus "Front drive inverter: a092 bms system status";
CM_ SG_ 1318 DIF_a094_canID "Front drive inverter: a094 can ID";
CM_ SG_ 1318 DIF_a094_errorType "Front drive inverter: a094 error type";
CM_ SG_ 1318 DIF_a094_badValue1 "Front drive inverter: a094 bad value1";
CM_ SG_ 1318 DIF_a094_badValue2 "Front drive inverter: a094 bad value2";
CM_ SG_ 1318 DIF_a096_const_fast "Front drive inverter: a096 const fast";
CM_ SG_ 1318 DIF_a096_text_fast "Front drive inverter: a096 text fast";
CM_ SG_ 1318 DIF_a096_text_flash "Front drive inverter: a096 text flash";
CM_ SG_ 1318 DIF_a096_mem_data "Front drive inverter: a096 mem data";
CM_ SG_ 1318 DIF_a096_mem_regs "Front drive inverter: a096 mem regs";
CM_ SG_ 1318 DIF_a096_boot_flash "Front drive inverter: a096 boot flash";
CM_ SG_ 1318 DIF_a096_word1 "Front drive inverter: a096 word1";
CM_ SG_ 1318 DIF_a096_word2 "Front drive inverter: a096 word2";
CM_ SG_ 1318 DIF_a097_errorType "Front drive inverter: a097 error type";
CM_ SG_ 1318 DIF_a097_lineNumber "Front drive inverter: a097 line number";
CM_ SG_ 1318 DIF_a097_argument "Front drive inverter: a097 argument";
CM_ SG_ 1318 DIF_a098_pwmCount "Front drive inverter: a098 pwm count";
CM_ SG_ 1318 DIF_a098_fluxState "Front drive inverter: a098 flux state";
CM_ SG_ 1318 DIF_a103_fluidTorDeltaT "Front drive inverter: a103 fluid tor delta t";
CM_ SG_ 1318 DIF_a103_noFlowDetected "Front drive inverter: a103 no flow detected";
CM_ SG_ 1318 DIF_a103_lowFlowDetected "Front drive inverter: a103 low flow detected";
CM_ SG_ 1318 DIF_a103_fluidImplausible "Front drive inverter: a103 fluid implausible";
CM_ SG_ 1318 DIF_a103_inverterTemp "Front drive inverter: a103 inverter temp";
CM_ SG_ 1318 DIF_a103_rmsCurrent "Front drive inverter: a103 rms current";
CM_ SG_ 1318 DIF_a103_ambientTemp "Front drive inverter: a103 ambient temp";
CM_ SG_ 1318 DIF_a103_sensorTempEst "Front drive inverter: a103 sensor temp est";
CM_ SG_ 1318 DIF_a107_fpgaVersion "Front drive inverter: a107 fpga version";
CM_ SG_ 1318 DIF_a107_fpgaBootVersion "Front drive inverter: a107 fpga boot version";
CM_ SG_ 1318 DIF_a107_fpgaMasterActive "Front drive inverter: a107 fpga master active";
CM_ SG_ 1318 DIF_a107_fpgaFaultActive "Front drive inverter: a107 fpga fault active";
CM_ SG_ 1318 DIF_a107_fpgaWarningActive "Front drive inverter: a107 fpga warning active";
CM_ SG_ 1318 DIF_a108_fromState "Front drive inverter: a108 from state";
CM_ SG_ 1318 DIF_a108_toState "Front drive inverter: a108 to state";
CM_ SG_ 1318 DIF_a108_blockingAlert "Front drive inverter: a108 blocking alert";
CM_ SG_ 1318 DIF_a110_EPBL_status "Front drive inverter: a110 EPBL status";
CM_ SG_ 1318 DIF_a110_EPBR_status "Front drive inverter: a110 EPBR status";
CM_ SG_ 1318 DIF_a111_phAcalib "Front drive inverter: a111 ph acalib";
CM_ SG_ 1318 DIF_a111_phBcalib "Front drive inverter: a111 ph bcalib";
CM_ SG_ 1318 DIF_a112_phaseAcurrent "Front drive inverter: a112 phase acurrent";
CM_ SG_ 1318 DIF_a112_phaseBcurrent "Front drive inverter: a112 phase bcurrent";
CM_ SG_ 1318 DIF_a113_heatsink1Temp "Front drive inverter: a113 heatsink1 temp";
CM_ SG_ 1318 DIF_a113_heatsink2Temp "Front drive inverter: a113 heatsink2 temp";
CM_ SG_ 1318 DIF_a113_heatsink3Temp "Front drive inverter: a113 heatsink3 temp";
CM_ SG_ 1318 DIF_a115_faultAddress "Front drive inverter: a115 fault address";
CM_ SG_ 1318 DIF_a115_isWriteNotRead "Front drive inverter: a115 is write not read";
CM_ SG_ 1318 DIF_a117_torque "Front drive inverter: a117 torque";
CM_ SG_ 1318 DIF_a117_slaveCommand "Front drive inverter: a117 slave command";
CM_ SG_ 1318 DIF_a117_power "Front drive inverter: a117 power";
CM_ SG_ 1318 DIF_a117_slaveCommand2 "Front drive inverter: a117 slave command2";
CM_ SG_ 1318 DIF_a117_speed "Front drive inverter: a117 speed";
CM_ SG_ 1318 DIF_a117_chassisControl "Front drive inverter: a117 chassis control";
CM_ SG_ 1318 DIF_a117_systemStatus "Front drive inverter: a117 system status";
CM_ SG_ 1318 DIF_a117_temperature "Front drive inverter: a117 temperature";
CM_ SG_ 1318 DIF_a117_vehicle "Front drive inverter: a117 vehicle";
CM_ SG_ 1318 DIF_a117_AddTcLimit "Front drive inverter: a117 add tc limit";
CM_ SG_ 1318 DIF_a117_dixCommand "Front drive inverter: a117 dix command";
CM_ SG_ 1318 DIF_a117_odometerStatus "Front drive inverter: a117 odometer status";
CM_ SG_ 1318 DIF_a117_maxRatedPower "Front drive inverter: a117 max rated power";
CM_ SG_ 1318 DIF_a119_hvpFaults "Front drive inverter: a119 hvp faults";
CM_ SG_ 1318 DIF_a120_dcLinkInfo "Front drive inverter: a120 dc link info";
CM_ SG_ 1318 DIF_a121_badRegReason "Front drive inverter: a121 bad reg reason";
CM_ SG_ 1318 DIF_a121_torqueDelta "Front drive inverter: a121 torque delta";
CM_ SG_ 1318 DIF_a121_badCurrent "Front drive inverter: a121 bad current";
CM_ SG_ 1318 DIF_a121_badFlux "Front drive inverter: a121 bad flux";
CM_ SG_ 1318 DIF_a123_lossReason "Front drive inverter: a123 loss reason";
CM_ SG_ 1318 DIF_a123_busVoltage "Front drive inverter: a123 bus voltage";
CM_ SG_ 1318 DIF_a123_badFlux "Front drive inverter: a123 bad flux";
CM_ SG_ 1318 DIF_a123_lossRequest "Front drive inverter: a123 loss request";
CM_ SG_ 1318 DIF_a123_badCurrent "Front drive inverter: a123 bad current";
CM_ SG_ 1318 DIF_a123_motorRPM "Front drive inverter: a123 motor RPM";
CM_ SG_ 1318 DIF_a123_varianceD "Front drive inverter: a123 variance d";
CM_ SG_ 1318 DIF_a123_varianceQ "Front drive inverter: a123 variance q";
CM_ SG_ 1318 DIF_a126_limpReason "Front drive inverter: a126 limp reason";
CM_ SG_ 1318 DIF_a127_gpoReason "Front drive inverter: a127 gpo reason";
CM_ SG_ 1318 DIF_a127_temp "Front drive inverter: a127 temp";
CM_ SG_ 1318 DIF_a133_capacitorTemp "Front drive inverter: a133 capacitor temp";
CM_ SG_ 1318 DIF_a133_badValue1 "Front drive inverter: a133 bad value1";
CM_ SG_ 1318 DIF_a133_badValue2 "Front drive inverter: a133 bad value2";
CM_ SG_ 1318 DIF_a134_wheelSpeedDiffFrL "Front drive inverter: a134 wheel speed diff fr l";
CM_ SG_ 1318 DIF_a134_wheelSpeedDiffFrR "Front drive inverter: a134 wheel speed diff fr r";
CM_ SG_ 1318 DIF_a134_wheelSpeedDiffReL "Front drive inverter: a134 wheel speed diff re l";
CM_ SG_ 1318 DIF_a134_wheelSpeedDiffReR "Front drive inverter: a134 wheel speed diff re r";
CM_ SG_ 1318 DIF_a136_spiError_BL "Front drive inverter: a136 spi error BL";
CM_ SG_ 1318 DIF_a136_crcError_BL "Front drive inverter: a136 crc error BL";
CM_ SG_ 1318 DIF_a136_busyError_BL "Front drive inverter: a136 busy error BL";
CM_ SG_ 1318 DIF_a136_spiError_BH "Front drive inverter: a136 spi error BH";
CM_ SG_ 1318 DIF_a136_crcError_BH "Front drive inverter: a136 crc error BH";
CM_ SG_ 1318 DIF_a136_busyError_BH "Front drive inverter: a136 busy error BH";
CM_ SG_ 1318 DIF_a136_spiError_CL "Front drive inverter: a136 spi error CL";
CM_ SG_ 1318 DIF_a136_crcError_CL "Front drive inverter: a136 crc error CL";
CM_ SG_ 1318 DIF_a136_busyError_CL "Front drive inverter: a136 busy error CL";
CM_ SG_ 1318 DIF_a136_spiError_CH "Front drive inverter: a136 spi error CH";
CM_ SG_ 1318 DIF_a136_crcError_CH "Front drive inverter: a136 crc error CH";
CM_ SG_ 1318 DIF_a136_busyError_CH "Front drive inverter: a136 busy error CH";
CM_ SG_ 1318 DIF_a136_spiError_AL "Front drive inverter: a136 spi error AL";
CM_ SG_ 1318 DIF_a136_crcError_AL "Front drive inverter: a136 crc error AL";
CM_ SG_ 1318 DIF_a136_busyError_AL "Front drive inverter: a136 busy error AL";
CM_ SG_ 1318 DIF_a136_spiError_AH "Front drive inverter: a136 spi error AH";
CM_ SG_ 1318 DIF_a136_crcError_AH "Front drive inverter: a136 crc error AH";
CM_ SG_ 1318 DIF_a136_busyError_AH "Front drive inverter: a136 busy error AH";
CM_ SG_ 1318 DIF_a144_autopilot "Front drive inverter: a144 autopilot";
CM_ SG_ 1318 DIF_a144_chassisType "Front drive inverter: a144 chassis type";
CM_ SG_ 1318 DIF_a144_drivetrainType "Front drive inverter: a144 drivetrain type";
CM_ SG_ 1318 DIF_a144_packEnergy "Front drive inverter: a144 pack energy";
CM_ SG_ 1318 DIF_a144_packPerformanceDeviatio "Front drive inverter: a144 pack performance deviation";
CM_ SG_ 1318 DIF_a144_performancePackage "Front drive inverter: a144 performance package";
CM_ SG_ 1318 DIF_a144_vdcType "Front drive inverter: a144 vdc type";
CM_ SG_ 1318 DIF_a144_brakeHWType "Front drive inverter: a144 brake HW type";
CM_ SG_ 1318 DIF_a144_inverterHardware "Front drive inverter: a144 inverter hardware";
CM_ SG_ 1318 DIF_a144_cabinPTCHeaterType "Front drive inverter: a144 cabin PTC heater type";
CM_ SG_ 1318 DIF_a144_frunkLatchType "Front drive inverter: a144 frunk latch type";
CM_ SG_ 1318 DIF_a144_platformMaxBusVoltage "Front drive inverter: a144 platform max bus voltage";
CM_ SG_ 1318 DIF_a144_oilPump1HwType "Front drive inverter: a144 oil pump1 hw type";
CM_ SG_ 1318 DIF_a144_oilPump2HwType "Front drive inverter: a144 oil pump2 hw type";
CM_ SG_ 1318 DIF_a144_heatsinkType "Front drive inverter: a144 heatsink type";
CM_ SG_ 1318 DIF_a144_softPerformanceLimit "Front drive inverter: a144 soft performance limit";
CM_ SG_ 1318 DIF_a144_brakeActuationType "Front drive inverter: a144 brake actuation type";
CM_ SG_ 1318 DIF_a144_dasHw "Front drive inverter: a144 das hw";
CM_ SG_ 1318 DIF_a144_chassisSubType "Front drive inverter: a144 chassis sub type";
CM_ SG_ 1318 DIF_a147_overtorque1UsedCount "Front drive inverter: a147 overtorque1 used count";
CM_ SG_ 1318 DIF_a147_overtorque2UsedCount "Front drive inverter: a147 overtorque2 used count";
CM_ SG_ 1318 DIF_a147_accumulatedWear "Front drive inverter: a147 accumulated wear";
CM_ SG_ 1318 DIF_a147_wearIsValid "Front drive inverter: a147 wear is valid";
CM_ SG_ 1318 DIF_a149_flow "Front drive inverter: a149 flow; raw 255 = signal not available (SNA)";
CM_ SG_ 1318 DIF_a149_voltage "Front drive inverter: a149 voltage";
CM_ SG_ 1318 DIF_a149_temperature "Front drive inverter: a149 temperature";
CM_ SG_ 1318 DIF_a149_state "Front drive inverter: a149 state; raw 7 = signal not available (SNA)";
CM_ SG_ 1318 DIF_a149_fluidTempSNA "Front drive inverter: a149 fluid temp SNA";
CM_ SG_ 1318 DIF_a149_insufficientFlow "Front drive inverter: a149 insufficient flow";
CM_ SG_ 1318 DIF_a149_motorOpenPhase "Front drive inverter: a149 motor open phase";
CM_ SG_ 1318 DIF_a149_motorShorted "Front drive inverter: a149 motor shorted";
CM_ SG_ 1318 DIF_a149_motorFlowSNA "Front drive inverter: a149 motor flow SNA";
CM_ SG_ 1318 DIF_a149_responseError "Front drive inverter: a149 response error";
CM_ SG_ 1318 DIF_a149_pcbaID "Front drive inverter: a149 pcba ID";
CM_ SG_ 1318 DIF_a150_vBatRawMinusFiltered "Front drive inverter: a150 v bat raw minus filtered";
CM_ SG_ 1318 DIF_a150_vBatFilteredRate "Front drive inverter: a150 v bat filtered rate";
CM_ SG_ 1318 DIF_a150_elapsedMs "Front drive inverter: a150 elapsed ms";
CM_ SG_ 1318 DIF_a150_energy "Front drive inverter: a150 energy";
CM_ SG_ 1318 DIF_a152_errorType "Front drive inverter: a152 error type";
CM_ SG_ 1318 DIF_a152_frameId "Front drive inverter: a152 frame id";
CM_ SG_ 1318 DIF_a152_badValue "Front drive inverter: a152 bad value";
CM_ SG_ 1318 DIF_a152_expectedValue "Front drive inverter: a152 expected value";
CM_ SG_ 1318 DIF_a153_oilFlow "Front drive inverter: a153 oil flow; raw 255 = signal not available (SNA)";
CM_ SG_ 1318 DIF_a153_oilTemperature "Front drive inverter: a153 oil temperature; raw 255 = signal not available (SNA)";
CM_ SG_ 1318 DIF_a153_phaseCurrent "Front drive inverter: a153 phase current; raw 255 = signal not available (SNA)";
CM_ SG_ 1318 DIF_a153_dcVoltage "Front drive inverter: a153 dc voltage; raw 255 = signal not available (SNA)";
CM_ SG_ 1318 DIF_a153_lowPressPlausibility "Front drive inverter: a153 low press plausibility";
CM_ SG_ 1318 DIF_a153_state "Front drive inverter: a153 state; raw 7 = signal not available (SNA)";
CM_ SG_ 1318 DIF_a153_oilPumpAlert "Front drive inverter: a153 oil pump alert";
CM_ SG_ 1318 DIF_a153_reason "Front drive inverter: a153 reason";
CM_ SG_ 1318 DIF_a154_motorRPM "Front drive inverter: a154 motor RPM";
CM_ SG_ 1318 DIF_a154_phaseError "Front drive inverter: a154 phase error";
CM_ SG_ 1318 DIF_a154_commonGain "Front drive inverter: a154 common gain";
CM_ SG_ 1318 DIF_a154_noCalibration "Front drive inverter: a154 no calibration";
CM_ SG_ 1318 DIF_a154_noPhaseLock "Front drive inverter: a154 no phase lock";
CM_ SG_ 1318 DIF_a154_noCarrier "Front drive inverter: a154 no carrier";
CM_ SG_ 1318 DIF_a154_notReady "Front drive inverter: a154 not ready";
CM_ SG_ 1318 DIF_a154_errorTableInvalid "Front drive inverter: a154 error table invalid";
CM_ SG_ 1318 DIF_a154_carrierOffset "Front drive inverter: a154 carrier offset";
CM_ SG_ 1318 DIF_a154_trackerIrrational "Front drive inverter: a154 tracker irrational";
CM_ SG_ 1318 DIF_a154_claMIA "Front drive inverter: a154 cla MIA";
CM_ SG_ 1318 DIF_a155_sensors "Front drive inverter: a155 sensors";
CM_ SG_ 1318 DIF_a155_coolant "Front drive inverter: a155 coolant";
CM_ SG_ 1318 DIF_a155_LVPowerState "Front drive inverter: a155 LV power state";
CM_ SG_ 1318 DIF_a155_vehicleStatus "Front drive inverter: a155 vehicle status";
CM_ SG_ 1318 DIF_a155_status "Front drive inverter: a155 status";
CM_ SG_ 1318 DIF_a155_leftDoorStatus "Front drive inverter: a155 left door status";
CM_ SG_ 1318 DIF_a155_rightDoorStatus "Front drive inverter: a155 right door status";
CM_ SG_ 1318 DIF_a155_vcleftSwitchStatus "Front drive inverter: a155 vcleft switch status";
CM_ SG_ 1318 DIF_a155_restraintStatus "Front drive inverter: a155 restraint status";
CM_ SG_ 1318 DIF_a155_systemStatus "Front drive inverter: a155 system status";
CM_ SG_ 1318 DIF_a155_prndStatus "Front drive inverter: a155 prnd status";
CM_ SG_ 1318 DIF_a155_liftgateStatus "Front drive inverter: a155 liftgate status";
CM_ SG_ 1318 DIF_a157_RCM_inertial1 "Front drive inverter: a157 RCM inertial1";
CM_ SG_ 1318 DIF_a157_RCM_inertial2 "Front drive inverter: a157 RCM inertial2";
CM_ SG_ 1318 DIF_a158_IBST_party1 "Front drive inverter: a158 IBST party1";
CM_ SG_ 1318 DIF_a158_BUS1_IBST_status "Front drive inverter: a158 BUS1 IBST status";
CM_ SG_ 1318 DIF_a158_BUS2_IBST_status "Front drive inverter: a158 BUS2 IBST status";
CM_ SG_ 1318 DIF_a160_vBatRawMinusFiltered "Front drive inverter: a160 v bat raw minus filtered";
CM_ SG_ 1318 DIF_a160_vBatFilteredRate "Front drive inverter: a160 v bat filtered rate";
CM_ SG_ 1318 DIF_a160_elapsedMs "Front drive inverter: a160 elapsed ms";
CM_ SG_ 1318 DIF_a160_energy "Front drive inverter: a160 energy";
CM_ SG_ 1318 DIF_a161_EPAS3P_sysStatus "Front drive inverter: a161 EPAS3 p sys status";
CM_ SG_ 1318 DIF_a161_EPAS3P_angleCalib "Front drive inverter: a161 EPAS3 p angle calib";
CM_ SG_ 1318 DIF_a202_reason "Front drive inverter: a202 reason";
CM_ SG_ 1318 DIF_a202_movement "Front drive inverter: a202 movement";
CM_ SG_ 1318 DIF_a202_sysStateExitCondition "Front drive inverter: a202 sys state exit condition";
CM_ SG_ 1318 DIF_a233_missedMsgCount "Front drive inverter: a233 missed msg count";
CM_ SG_ 1318 DIF_a233_serviceModeActive "Signal reported by Front drive inverter";
CM_ SG_ 1318 DIF_a234_PCS_dcdcStatus "Front drive inverter: a234 PCS dcdc status";
CM_ SG_ 1318 DIF_a236_states "Front drive inverter: a236 states";
CM_ SG_ 1318 DIF_a242_RotorOffset "Front drive inverter: a242 rotor offset";
CM_ SG_ 1318 DIF_a242_RotorFlux "Front drive inverter: a242 rotor flux";
CM_ SG_ 1318 DIF_a242_ResolverError "Front drive inverter: a242 resolver error";
CM_ SG_ 1318 DIF_a244_desatHighSide "Front drive inverter: a244 desat high side";
CM_ SG_ 1318 DIF_a244_desatLowSide "Front drive inverter: a244 desat low side";
CM_ SG_ 1318 DIF_a244_singleSwitchShort "Front drive inverter: a244 single switch short";
CM_ SG_ 1318 DIF_a244_flybackFault "Front drive inverter: a244 flyback fault";
CM_ SG_ 1318 DIF_a244_postShortTestFailed "Front drive inverter: a244 post short test failed";
CM_ SG_ 1318 DIF_a244_udsSelfTest "Front drive inverter: a244 uds self test";
CM_ SG_ 1318 DIF_a244_irSensorV "Front drive inverter: a244 ir sensor v";
CM_ SG_ 1318 DIF_a244_gateDriveICUndervoltage "Front drive inverter: a244 gate drive IC undervoltage";
CM_ SG_ 1318 DIF_a244_plausibleSingleSwitchSh "Front drive inverter: a244 plausible single switch short only";
CM_ SG_ 1318 DIF_a246_atSpeedDIResetCount "Front drive inverter: a246 at speed DI reset count";
CM_ SG_ 1318 DIF_a246_didPMCauseASC "Front drive inverter: a246 did PM cause ASC";
CM_ SG_ 1318 DIF_a246_currentSensorRational "Front drive inverter: a246 current sensor rational";
CM_ SG_ 1318 DIF_a246_observerDetectedLS3PS "Front drive inverter: a246 observer detected LS3 PS";
CM_ SG_ 1318 DIF_a246_hvIsGood "Front drive inverter: a246 hv is good";
CM_ SG_ 1318 DIF_a246_lvIsGood "Front drive inverter: a246 lv is good";
CM_ SG_ 1318 DIF_a246_codeBranch "Front drive inverter: a246 code branch";
CM_ SG_ 1318 DIF_a246_motorRPM "Front drive inverter: a246 motor RPM";
CM_ SG_ 1318 DIF_a246_eepromOffsetIa "Front drive inverter: a246 eeprom offset ia";
CM_ SG_ 1318 DIF_a246_eepromOffsetIb "Front drive inverter: a246 eeprom offset ib";
CM_ SG_ 1318 DIF_a247_rotorOffsetEst "Front drive inverter: a247 rotor offset est";
CM_ SG_ 1318 DIF_a247_motorRPM "Front drive inverter: a247 motor RPM";
CM_ SG_ 1318 DIF_a247_torqueMotor "Front drive inverter: a247 torque motor";
CM_ SG_ 1318 DIF_a251_oilFlow "Front drive inverter: a251 oil flow; raw 255 = signal not available (SNA)";
CM_ SG_ 1318 DIF_a251_oilTemperature "Front drive inverter: a251 oil temperature; raw 255 = signal not available (SNA)";
CM_ SG_ 1318 DIF_a251_dcVoltage "Front drive inverter: a251 dc voltage; raw 255 = signal not available (SNA)";
CM_ SG_ 1318 DIF_a251_dcCurrent "Front drive inverter: a251 dc current; raw 255 = signal not available (SNA)";
CM_ SG_ 1318 DIF_a251_phaseCurrent "Front drive inverter: a251 phase current; raw 255 = signal not available (SNA)";
CM_ SG_ 1318 DIF_a251_leadAngle "Front drive inverter: a251 lead angle";
CM_ SG_ 1318 DIF_a251_reason "Front drive inverter: a251 reason";
CM_ BO_ 854 "Front drive inverter message: alert matrix1";
CM_ SG_ 854 DIF_a001_hwPhaseAgateDrive "Front drive inverter: a001 hw phase agate drive";
CM_ SG_ 854 DIF_a002_hwPhaseBgateDrive "Front drive inverter: a002 hw phase bgate drive";
CM_ SG_ 854 DIF_a003_hwPhaseCgateDrive "Front drive inverter: a003 hw phase cgate drive";
CM_ SG_ 854 DIF_a004_hwPhaseApeak "Front drive inverter: a004 hw phase apeak";
CM_ SG_ 854 DIF_a005_hwPhaseBpeak "Front drive inverter: a005 hw phase bpeak";
CM_ SG_ 854 DIF_a006_hwPhaseCpeak "Front drive inverter: a006 hw phase cpeak";
CM_ SG_ 854 DIF_a007_statorAnomalyDetected "Front drive inverter: a007 stator anomaly detected";
CM_ SG_ 854 DIF_a008_hwEncoderA "Front drive inverter: a008 hw encoder a";
CM_ SG_ 854 DIF_a009_hwEncoderB "Front drive inverter: a009 hw encoder b";
CM_ SG_ 854 DIF_a010_unintendedReset "Front drive inverter: a010 unintended reset";
CM_ SG_ 854 DIF_a011_swPowerStageNotReady "Front drive inverter: a011 sw power stage not ready";
CM_ SG_ 854 DIF_a012_hvilNotClosed "Front drive inverter: a012 hvil not closed";
CM_ SG_ 854 DIF_a013_eccError "Front drive inverter: a013 ecc error";
CM_ SG_ 854 DIF_a014_activeDamping "Front drive inverter: a014 active damping";
CM_ SG_ 854 DIF_a015_mechSafeStateAnomaly "Front drive inverter: a015 mech safe state anomaly";
CM_ SG_ 854 DIF_a016_safeStateApplied "Front drive inverter: a016 safe state applied";
CM_ SG_ 854 DIF_a017_hwPedalMonitor "Front drive inverter: a017 hw pedal monitor";
CM_ SG_ 854 DIF_a018_hwLVSupplyUV "Front drive inverter: a018 hw LV supply UV";
CM_ SG_ 854 DIF_a020_hwMotorEncoder "Front drive inverter: a020 hw motor encoder";
CM_ SG_ 854 DIF_a021_hwBusOV "Front drive inverter: a021 hw bus OV";
CM_ SG_ 854 DIF_a022_hw5vSupplyUV "Front drive inverter: a022 hw5v supply UV";
CM_ SG_ 854 DIF_a024_selfTest "Front drive inverter: a024 self test";
CM_ SG_ 854 DIF_a025_phaseApeak "Front drive inverter: a025 phase apeak";
CM_ SG_ 854 DIF_a026_phaseBpeak "Front drive inverter: a026 phase bpeak";
CM_ SG_ 854 DIF_a027_phaseCpeak "Front drive inverter: a027 phase cpeak";
CM_ SG_ 854 DIF_a028_phaseArms "Front drive inverter: a028 phase arms";
CM_ SG_ 854 DIF_a029_phaseBrms "Front drive inverter: a029 phase brms";
CM_ SG_ 854 DIF_a030_phaseCrms "Front drive inverter: a030 phase crms";
CM_ SG_ 854 DIF_a031_phaseAcurrentOffset "Front drive inverter: a031 phase acurrent offset";
CM_ SG_ 854 DIF_a032_phaseBcurrentOffset "Front drive inverter: a032 phase bcurrent offset";
CM_ SG_ 854 DIF_a033_phaseAcurrentSensor "Front drive inverter: a033 phase acurrent sensor";
CM_ SG_ 854 DIF_a034_phaseBcurrentSensor "Front drive inverter: a034 phase bcurrent sensor";
CM_ SG_ 854 DIF_a035_phaseCurrentBalance "Front drive inverter: a035 phase current balance";
CM_ SG_ 854 DIF_a036_busOV "Front drive inverter: a036 bus OV";
CM_ SG_ 854 DIF_a037_busUV "Front drive inverter: a037 bus UV";
CM_ SG_ 854 DIF_a038_busVsensor "Front drive inverter: a038 bus vsensor";
CM_ SG_ 854 DIF_a039_exceptionUndefinedInstr "Front drive inverter: a039 exception undefined instruction";
CM_ SG_ 854 DIF_a040_difMIA "Front drive inverter: a040 dif MIA";
CM_ SG_ 854 DIF_a041_sdcMIA "Front drive inverter: a041 sdc MIA";
CM_ SG_ 854 DIF_a042_inletSensor "Front drive inverter: a042 inlet sensor";
CM_ SG_ 854 DIF_a043_outletOT "Front drive inverter: a043 outlet OT";
CM_ SG_ 854 DIF_a044_outletUT "Front drive inverter: a044 outlet UT";
CM_ SG_ 854 DIF_a045_outletSensor "Front drive inverter: a045 outlet sensor";
CM_ SG_ 854 DIF_a046_statorOT "Front drive inverter: a046 stator OT";
CM_ SG_ 854 DIF_a047_statorSensor1 "Front drive inverter: a047 stator sensor1";
CM_ SG_ 854 DIF_a048_statorSensor2 "Front drive inverter: a048 stator sensor2";
CM_ SG_ 854 DIF_a049_statorSensorDiff "Front drive inverter: a049 stator sensor diff";
CM_ SG_ 854 DIF_a050_noStatorSensor "Front drive inverter: a050 no stator sensor";
CM_ SG_ 854 DIF_a052_dirMIA "Front drive inverter: a052 dir MIA";
CM_ SG_ 854 DIF_a053_unexpectedLatchState "Front drive inverter: a053 unexpected latch state";
CM_ SG_ 854 DIF_a054_driveInverterOT "Front drive inverter: a054 drive inverter OT";
CM_ SG_ 854 DIF_a055_trqCrossCheck "Front drive inverter: a055 trq cross check";
CM_ SG_ 854 DIF_a056_ambientOT "Front drive inverter: a056 ambient OT";
CM_ SG_ 854 DIF_a057_ambientUT "Front drive inverter: a057 ambient UT";
CM_ SG_ 854 DIF_a058_ambientSensor "Front drive inverter: a058 ambient sensor";
CM_ SG_ 854 DIF_a059_heatsinkOT "Front drive inverter: a059 heatsink OT";
CM_ SG_ 854 DIF_a060_heatsinkUT "Front drive inverter: a060 heatsink UT";
CM_ SG_ 854 DIF_a061_heatsinkSensor "Front drive inverter: a061 heatsink sensor";
CM_ SG_ 854 DIF_a062_systemLimpMode "Front drive inverter: a062 system limp mode";
CM_ SG_ 854 DIF_a063_bbMIA "Front drive inverter: a063 bb MIA";
CM_ SG_ 854 DIF_a064_torqueIntervention "Front drive inverter: a064 torque intervention";
CM_ BO_ 855 "Front drive inverter message: alert matrix2";
CM_ SG_ 855 DIF_a065_canHardwareBusB "Front drive inverter: a065 can hardware bus b";
CM_ SG_ 855 DIF_a066_canDataBusB "Front drive inverter: a066 can data bus b";
CM_ SG_ 855 DIF_a067_canOverrunBusB "Front drive inverter: a067 can overrun bus b";
CM_ SG_ 855 DIF_a069_rotorTempLimit "Front drive inverter: a069 rotor temp limit";
CM_ SG_ 855 DIF_a070_udsTransactionInitiated "Front drive inverter: a070 uds transaction initiated";
CM_ SG_ 855 DIF_a071_busDisconnected "Front drive inverter: a071 bus disconnected";
CM_ SG_ 855 DIF_a072_gateDriveFaultCounter "Front drive inverter: a072 gate drive fault counter";
CM_ SG_ 855 DIF_a073_motorSpeed "Front drive inverter: a073 motor speed";
CM_ SG_ 855 DIF_a074_motorEncoder "Front drive inverter: a074 motor encoder";
CM_ SG_ 855 DIF_a075_motorSpeedMismatch "Front drive inverter: a075 motor speed mismatch";
CM_ SG_ 855 DIF_a076_lvSupplyOV "Front drive inverter: a076 lv supply OV";
CM_ SG_ 855 DIF_a077_lvSupplyUV "Front drive inverter: a077 lv supply UV";
CM_ SG_ 855 DIF_a078_adcRefLow "Front drive inverter: a078 adc ref low";
CM_ SG_ 855 DIF_a079_adcRefHigh "Front drive inverter: a079 adc ref high";
CM_ SG_ 855 DIF_a081_P0BFF_DIF_EM_CurrentHig "Front drive inverter: a081 P0 BFF DIF EM current high";
CM_ SG_ 855 DIF_a082_P7837_DIF_ECU_DemoTimer "Front drive inverter: a082 P7837 DIF ECU demo timer";
CM_ SG_ 855 DIF_a083_PABCD_DIF_ECU_DemoWindo "Front drive inverter: a083 PABCD DIF ECU demo window";
CM_ SG_ 855 DIF_a084_eccTestData0 "Front drive inverter: a084 ecc test data0";
CM_ SG_ 855 DIF_a086_activeDischargeOn "Front drive inverter: a086 active discharge on";
CM_ SG_ 855 DIF_a087_gtwMIA "Front drive inverter: a087 gtw MIA";
CM_ SG_ 855 DIF_a088_uiMIA "Front drive inverter: a088 ui MIA";
CM_ SG_ 855 DIF_a090_pmMIA "Front drive inverter: a090 pm MIA";
CM_ SG_ 855 DIF_a091_espMIA "Front drive inverter: a091 esp MIA";
CM_ SG_ 855 DIF_a092_bmsMIA "Front drive inverter: a092 bms MIA";
CM_ SG_ 855 DIF_a093_canHardwareBusA "Front drive inverter: a093 can hardware bus a";
CM_ SG_ 855 DIF_a094_canDataBusA "Front drive inverter: a094 can data bus a";
CM_ SG_ 855 DIF_a095_canOverrunBusA "Front drive inverter: a095 can overrun bus a";
CM_ SG_ 855 DIF_a096_memoryError "Front drive inverter: a096 memory error";
CM_ SG_ 855 DIF_a097_eepromError "Front drive inverter: a097 eeprom error";
CM_ SG_ 855 DIF_a098_intTimeTooLong "Front drive inverter: a098 int time too long";
CM_ SG_ 855 DIF_a099_threadOverrun "Front drive inverter: a099 thread overrun";
CM_ SG_ 855 DIF_a100_assertion "Front drive inverter: a100 assertion";
CM_ SG_ 855 DIF_a101_eccTestData1 "Front drive inverter: a101 ecc test data1";
CM_ SG_ 855 DIF_a102_exceptionPrefetchAbort "Front drive inverter: a102 exception prefetch abort";
CM_ SG_ 855 DIF_a103_lowFlow "Front drive inverter: a103 low flow";
CM_ SG_ 855 DIF_a107_fpgaError "Front drive inverter: a107 fpga error";
CM_ SG_ 855 DIF_a108_stateTrans "Front drive inverter: a108 state trans";
CM_ SG_ 855 DIF_a109_ahbWriteError "Front drive inverter: a109 ahb write error";
CM_ SG_ 855 DIF_a110_brakeMIA "Front drive inverter: a110 brake MIA";
CM_ SG_ 855 DIF_a111_badPhaseSensorCalib "Front drive inverter: a111 bad phase sensor calib";
CM_ SG_ 855 DIF_a112_noPhaseCurrent "Front drive inverter: a112 no phase current";
CM_ SG_ 855 DIF_a113_noFuncHeatsinkSensor "Front drive inverter: a113 no func heatsink sensor";
CM_ SG_ 855 DIF_a114_exceptionDataAbort "Front drive inverter: a114 exception data abort";
CM_ SG_ 855 DIF_a115_exceptionDataAbort2 "Front drive inverter: a115 exception data abort2";
CM_ SG_ 855 DIF_a116_highSpeedWearCounter "Front drive inverter: a116 high speed wear counter";
CM_ SG_ 855 DIF_a117_diMIA "Front drive inverter: a117 di MIA";
CM_ SG_ 855 DIF_a119_hvpMIA "Front drive inverter: a119 hvp MIA";
CM_ SG_ 855 DIF_a120_hvlinkMIA "Front drive inverter: a120 hvlink MIA";
CM_ SG_ 855 DIF_a121_motorControlRegulation "Front drive inverter: a121 motor control regulation";
CM_ SG_ 855 DIF_a122_highStackUsage "Front drive inverter: a122 high stack usage";
CM_ SG_ 855 DIF_a123_lossMotorControl "Front drive inverter: a123 loss motor control";
CM_ SG_ 855 DIF_a126_limpMode "Front drive inverter: a126 limp mode";
CM_ SG_ 855 DIF_a127_gracefulPowerOff "Front drive inverter: a127 graceful power off";
CM_ SG_ 855 DIF_a128_fpgaVersionMismatch "Front drive inverter: a128 fpga version mismatch";
CM_ BO_ 858 "Front drive inverter message: alert matrix3";
CM_ SG_ 858 DIF_a133_capacitorOT "Front drive inverter: a133 capacitor OT";
CM_ SG_ 858 DIF_a134_wheelSpeedIrrational "Front drive inverter: a134 wheel speed irrational";
CM_ SG_ 858 DIF_a136_spiError "Front drive inverter: a136 spi error";
CM_ SG_ 858 DIF_a142_highLashAngle "Front drive inverter: a142 high lash angle";
CM_ SG_ 858 DIF_a144_configMismatch "Front drive inverter: a144 config mismatch";
CM_ SG_ 858 DIF_a147_highTorqueWearLimit "Front drive inverter: a147 high torque wear limit";
CM_ SG_ 858 DIF_a148_burnInCycleEnded "Front drive inverter: a148 burn in cycle ended";
CM_ SG_ 858 DIF_a149_oilPumpFailure "Front drive inverter: a149 oil pump failure";
CM_ SG_ 858 DIF_a150_busVD "Front drive inverter: a150 bus VD";
CM_ SG_ 858 DIF_a151_shockTorqueLimiter "Front drive inverter: a151 shock torque limiter";
CM_ SG_ 858 DIF_a152_linError "Front drive inverter: a152 lin error";
CM_ SG_ 858 DIF_a153_oilPumpDiagnostics "Front drive inverter: a153 oil pump diagnostics";
CM_ SG_ 858 DIF_a154_resolver "Front drive inverter: a154 resolver";
CM_ SG_ 858 DIF_a155_vcfrontMIA "Front drive inverter: a155 vcfront MIA";
CM_ SG_ 858 DIF_a156_currentObserver "Front drive inverter: a156 current observer";
CM_ SG_ 858 DIF_a157_rcmMIA "Front drive inverter: a157 rcm MIA";
CM_ SG_ 858 DIF_a158_ibstMIA "Front drive inverter: a158 ibst MIA";
CM_ SG_ 858 DIF_a160_busVoltageAnomaly "Front drive inverter: a160 bus voltage anomaly";
CM_ SG_ 858 DIF_a161_epas3pMIA "Front drive inverter: a161 epas3p MIA";
CM_ SG_ 858 DIF_a162_endOfLifetimeBurnIn "Front drive inverter: a162 end of lifetime burn in";
CM_ SG_ 858 DIF_a174_unitMayNotRestart "Front drive inverter: a174 unit may not restart";
CM_ SG_ 858 DIF_a176_safetyICFault "Front drive inverter: a176 safety IC fault";
CM_ SG_ 858 DIF_a177_fluxReferenceCorrected "Front drive inverter: a177 flux reference corrected";
BA_DEF_ BO_ "GenMsgCycleTime" INT 0 3600000;
BA_DEF_ BO_ "GenMsgSendType" ENUM "Cyclic","NotUsed","NotUsed","NotUsed","NotUsed","NotUsed","NotUsed","IfActive","NoMsgSendType","NotUsed";
BA_DEF_ BO_ "VFrameFormat" ENUM "StandardCAN","ExtendedCAN","reserved","J1939PG","reserved","reserved","reserved","reserved","reserved","reserved","reserved","reserved","reserved","reserved","StandardCAN_FD","ExtendedCAN_FD";
BA_DEF_ BO_ "CANFD_BRS" ENUM "0","1";
BA_DEF_ SG_ "GenSigSNA" STRING;
BA_DEF_ SG_ "SystemSignalLongSymbol" STRING;
BA_DEF_ SG_ "Confidence" ENUM "validated","plausible","layout-only","contradicted";
BA_DEF_DEF_ "GenMsgCycleTime" 0;
BA_DEF_DEF_ "GenMsgSendType" "NoMsgSendType";
BA_DEF_DEF_ "VFrameFormat" "StandardCAN";
BA_DEF_DEF_ "CANFD_BRS" "1";
BA_DEF_DEF_ "GenSigSNA" "";
BA_DEF_DEF_ "SystemSignalLongSymbol" "";
BA_DEF_DEF_ "Confidence" "layout-only";
BA_ "GenMsgCycleTime" BO_ 528 100;
BA_ "GenMsgSendType" BO_ 528 0;
BA_ "GenMsgCycleTime" BO_ 893 1000;
BA_ "GenMsgSendType" BO_ 893 0;
BA_ "GenMsgCycleTime" BO_ 583 100;
BA_ "GenMsgSendType" BO_ 583 0;
BA_ "GenMsgCycleTime" BO_ 2041 1000;
BA_ "GenMsgSendType" BO_ 2041 0;
BA_ "GenMsgCycleTime" BO_ 777 30;
BA_ "GenMsgSendType" BO_ 777 0;
BA_ "GenMsgCycleTime" BO_ 1548 5;
BA_ "GenMsgSendType" BO_ 1548 0;
BA_ "GenMsgCycleTime" BO_ 854 1000;
BA_ "GenMsgSendType" BO_ 854 0;
BA_ "GenMsgCycleTime" BO_ 855 1000;
BA_ "GenMsgSendType" BO_ 855 0;
BA_ "GenMsgCycleTime" BO_ 858 1000;
BA_ "GenMsgSendType" BO_ 858 0;
BA_ "Confidence" SG_ 528 CP_type 0;
BA_ "Confidence" SG_ 528 CP_insertEnableLine 0;
BA_ "Confidence" SG_ 528 CP_latchState 0;
BA_ "GenSigSNA" SG_ 528 CP_latchState "0";
BA_ "Confidence" SG_ 528 CP_permanentPowerRequest 0;
BA_ "Confidence" SG_ 528 CP_chargeDoorOpen 0;
BA_ "Confidence" SG_ 528 CP_doorControlState 0;
BA_ "Confidence" SG_ 528 CP_doorButtonPressed 0;
BA_ "Confidence" SG_ 528 CP_swcanRelayClosed 0;
BA_ "Confidence" SG_ 528 CP_inhibitOta 0;
BA_ "Confidence" SG_ 528 CP_chargeCableState 0;
BA_ "GenSigSNA" SG_ 528 CP_chargeCableState "0";
BA_ "Confidence" SG_ 528 CP_latchControlState 0;
BA_ "Confidence" SG_ 528 CP_ledColor 0;
BA_ "Confidence" SG_ 528 CP_UHF_handleFound 0;
BA_ "Confidence" SG_ 528 CP_faultLineSensed 0;
BA_ "Confidence" SG_ 528 CP_doorPresenceState 0;
BA_ "Confidence" SG_ 528 CP_inductiveSensorState 0;
BA_ "Confidence" SG_ 528 CP_chargeDoorOpenUI 0;
BA_ "Confidence" SG_ 528 CP_vehicleUnlockRequest 0;
BA_ "Confidence" SG_ 528 CP_coldWeatherMode 0;
BA_ "Confidence" SG_ 528 CP_inletHeaterUiState 1;
BA_ "Confidence" SG_ 893 CP_thermalStatusSelect 1;
BA_ "Confidence" SG_ 893 CP_pinTemperature1 0;
BA_ "Confidence" SG_ 893 CP_pinTemperature2 0;
BA_ "Confidence" SG_ 893 CP_pinTemperature3 0;
BA_ "Confidence" SG_ 583 DAS_roadEstimator 0;
BA_ "Confidence" SG_ 583 DAS_arbiterBehavior 0;
BA_ "Confidence" SG_ 583 DAS_mapAvailability 0;
BA_ "Confidence" SG_ 583 DAS_controllerRef 0;
BA_ "Confidence" SG_ 583 DAS_alcInternalState 0;
BA_ "Confidence" SG_ 583 DAS_behaviorReport 0;
BA_ "Confidence" SG_ 583 DAS_constructionZone 0;
BA_ "Confidence" SG_ 583 DAS_controllerHealth 0;
BA_ "Confidence" SG_ 583 DAS_controlDistance 0;
BA_ "Confidence" SG_ 583 DAS_autopilotAbortReason 0;
BA_ "Confidence" SG_ 583 DAS_rqstedBehaviorStatus 0;
BA_ "Confidence" SG_ 583 DAS_forkState 0;
BA_ "Confidence" SG_ 583 DAS_laneChangeState 0;
BA_ "Confidence" SG_ 583 DAS_lastWatchdogCode 1;
BA_ "Confidence" SG_ 2041 DAS_gpsStatusMultiplexer 1;
BA_ "Confidence" SG_ 2041 DAS_gpsTransportModeState 0;
BA_ "Confidence" SG_ 2041 DAS_gpsSatsInUseHardware 0;
BA_ "Confidence" SG_ 2041 DAS_gpsRejectingSatData 0;
BA_ "Confidence" SG_ 2041 DAS_gpsWheelsOffMotionDetected 0;
BA_ "Confidence" SG_ 2041 DAS_gpsFixTypeHardware 0;
BA_ "Confidence" SG_ 2041 DAS_gpsRawxEnabled 0;
BA_ "Confidence" SG_ 2041 DAS_gpsRxmRawxMia 0;
BA_ "Confidence" SG_ 2041 DAS_gpsRxmSfrbxMia 0;
BA_ "Confidence" SG_ 2041 DAS_gpsEsfMeasMia 0;
BA_ "Confidence" SG_ 2041 DAS_gpsEsfRawMia 0;
BA_ "Confidence" SG_ 2041 DAS_gpsNavStatusMia 0;
BA_ "Confidence" SG_ 2041 DAS_gpsSoftwareConfigured 0;
BA_ "Confidence" SG_ 2041 DAS_gpsSoftwareUsed 0;
BA_ "Confidence" SG_ 2041 DAS_gpsSoftwareFastStartReady 0;
BA_ "Confidence" SG_ 2041 DAS_gpsSatsInUseSoftware 0;
BA_ "Confidence" SG_ 2041 DAS_gpsFixTypeSoftware 0;
BA_ "Confidence" SG_ 2041 DAS_gpsCWJammingInidcator 0;
BA_ "Confidence" SG_ 2041 DAS_gpsJammingState 0;
BA_ "Confidence" SG_ 2041 DAS_gpsSpoofDetectorState 0;
BA_ "Confidence" SG_ 2041 DAS_gpsInvalidMsgPercentage 0;
BA_ "Confidence" SG_ 2041 DAS_gnssConstellationsState 0;
BA_ "Confidence" SG_ 2041 DAS_gpsReceiverNoiseLevel 0;
BA_ "Confidence" SG_ 2041 DAS_gpsAutomaticGainControl 0;
BA_ "Confidence" SG_ 2041 DAS_gpsPreviousPositionDeltaHw 0;
BA_ "Confidence" SG_ 2041 DAS_gpsPreviousPositionDeltaSw 0;
BA_ "Confidence" SG_ 2041 DAS_gpsNmeaDispatchFailureCount 0;
BA_ "Confidence" SG_ 2041 DAS_gnssMaxInstantaneousCnorGps 0;
BA_ "Confidence" SG_ 2041 DAS_gnssMaxInstantaneousCnorGal 0;
BA_ "Confidence" SG_ 2041 DAS_gnssMaxInstantaneousCnorBds 0;
BA_ "Confidence" SG_ 2041 DAS_gpsResetReason 0;
BA_ "Confidence" SG_ 2041 DAS_gpsAccuracyHorizontal 0;
BA_ "Confidence" SG_ 2041 DAS_gpsAccuracyVertical 0;
BA_ "Confidence" SG_ 2041 DAS_gpsSolutionFallback 0;
BA_ "Confidence" SG_ 2041 DAS_gpsToMcuSource 0;
BA_ "Confidence" SG_ 2041 DAS_gpsSolutionSoc 0;
BA_ "Confidence" SG_ 2041 DAS_gpsRedundancyActive 0;
BA_ "Confidence" SG_ 2041 DAS_gpsFixTypeSoftwareSocB 0;
BA_ "Confidence" SG_ 2041 DAS_gpsSatsInUseSoftwareSocB 0;
BA_ "Confidence" SG_ 2041 DAS_gnssNumSatsGps 0;
BA_ "Confidence" SG_ 2041 DAS_gnssNumSatsGal 0;
BA_ "Confidence" SG_ 2041 DAS_gnssNumSatsBds 0;
BA_ "Confidence" SG_ 2041 DAS_gnssAvgInstantaneousCnorGps 0;
BA_ "Confidence" SG_ 2041 DAS_gnssAvgInstantaneousCnorGal 0;
BA_ "Confidence" SG_ 2041 DAS_gnssAvgInstantaneousCnorBds 0;
BA_ "Confidence" SG_ 2041 DAS_gnssAvgInstantaneousCnorGpsL 0;
BA_ "SystemSignalLongSymbol" SG_ 2041 DAS_gnssAvgInstantaneousCnorGpsL "DAS_gnssAvgInstantaneousCnorGpsLowBand";
BA_ "Confidence" SG_ 2041 DAS_gnssAvgInstantaneousCnorGalL 0;
BA_ "SystemSignalLongSymbol" SG_ 2041 DAS_gnssAvgInstantaneousCnorGalL "DAS_gnssAvgInstantaneousCnorGalLowBand";
BA_ "Confidence" SG_ 2041 DAS_gnssAvgInstantaneousCnorBdsL 0;
BA_ "SystemSignalLongSymbol" SG_ 2041 DAS_gnssAvgInstantaneousCnorBdsL "DAS_gnssAvgInstantaneousCnorBdsLowBand";
BA_ "Confidence" SG_ 777 DAS_objectId 1;
BA_ "Confidence" SG_ 777 DAS_leadVehType 0;
BA_ "Confidence" SG_ 777 DAS_leadVehRelevantForControl 0;
BA_ "Confidence" SG_ 777 DAS_leadVehDx 0;
BA_ "GenSigSNA" SG_ 777 DAS_leadVehDx "255";
BA_ "Confidence" SG_ 777 DAS_leadVehVxRel 0;
BA_ "GenSigSNA" SG_ 777 DAS_leadVehVxRel "15";
BA_ "Confidence" SG_ 777 DAS_leadVehDy 0;
BA_ "Confidence" SG_ 777 DAS_leadVehId 0;
BA_ "GenSigSNA" SG_ 777 DAS_leadVehId "127";
BA_ "Confidence" SG_ 777 DAS_leadVeh2Type 0;
BA_ "Confidence" SG_ 777 DAS_leadVeh2RelevantForControl 0;
BA_ "Confidence" SG_ 777 DAS_leadVeh2Dx 0;
BA_ "GenSigSNA" SG_ 777 DAS_leadVeh2Dx "255";
BA_ "Confidence" SG_ 777 DAS_leadVeh2VxRel 0;
BA_ "GenSigSNA" SG_ 777 DAS_leadVeh2VxRel "15";
BA_ "Confidence" SG_ 777 DAS_leadVeh2Dy 0;
BA_ "Confidence" SG_ 777 DAS_leadVeh2Id 0;
BA_ "GenSigSNA" SG_ 777 DAS_leadVeh2Id "0";
BA_ "Confidence" SG_ 777 DAS_leftVehType 0;
BA_ "Confidence" SG_ 777 DAS_leftVehRelevantForControl 0;
BA_ "Confidence" SG_ 777 DAS_leftVehDx 0;
BA_ "GenSigSNA" SG_ 777 DAS_leftVehDx "255";
BA_ "Confidence" SG_ 777 DAS_leftVehVxRel 0;
BA_ "GenSigSNA" SG_ 777 DAS_leftVehVxRel "15";
BA_ "Confidence" SG_ 777 DAS_leftVehDy 0;
BA_ "Confidence" SG_ 777 DAS_leftVehId 0;
BA_ "GenSigSNA" SG_ 777 DAS_leftVehId "127";
BA_ "Confidence" SG_ 777 DAS_leftVeh2Type 0;
BA_ "Confidence" SG_ 777 DAS_leftVeh2RelevantForControl 0;
BA_ "Confidence" SG_ 777 DAS_leftVeh2Dx 0;
BA_ "GenSigSNA" SG_ 777 DAS_leftVeh2Dx "255";
BA_ "Confidence" SG_ 777 DAS_leftVeh2VxRel 0;
BA_ "GenSigSNA" SG_ 777 DAS_leftVeh2VxRel "15";
BA_ "Confidence" SG_ 777 DAS_leftVeh2Dy 0;
BA_ "Confidence" SG_ 777 DAS_leftVeh2Id 0;
BA_ "GenSigSNA" SG_ 777 DAS_leftVeh2Id "0";
BA_ "Confidence" SG_ 777 DAS_rightVehType 0;
BA_ "Confidence" SG_ 777 DAS_rightVehRelevantForControl 0;
BA_ "Confidence" SG_ 777 DAS_rightVehDx 0;
BA_ "GenSigSNA" SG_ 777 DAS_rightVehDx "255";
BA_ "Confidence" SG_ 777 DAS_rightVehVxRel 0;
BA_ "GenSigSNA" SG_ 777 DAS_rightVehVxRel "15";
BA_ "Confidence" SG_ 777 DAS_rightVehDy 0;
BA_ "Confidence" SG_ 777 DAS_rightVehId 0;
BA_ "GenSigSNA" SG_ 777 DAS_rightVehId "127";
BA_ "Confidence" SG_ 777 DAS_rightVeh2Type 0;
BA_ "Confidence" SG_ 777 DAS_rightVeh2RelevantForControl 0;
BA_ "Confidence" SG_ 777 DAS_rightVeh2Dx 0;
BA_ "GenSigSNA" SG_ 777 DAS_rightVeh2Dx "255";
BA_ "Confidence" SG_ 777 DAS_rightVeh2VxRel 0;
BA_ "GenSigSNA" SG_ 777 DAS_rightVeh2VxRel "15";
BA_ "Confidence" SG_ 777 DAS_rightVeh2Dy 0;
BA_ "Confidence" SG_ 777 DAS_rightVeh2Id 0;
BA_ "GenSigSNA" SG_ 777 DAS_rightVeh2Id "0";
BA_ "Confidence" SG_ 777 DAS_cutinVehType 0;
BA_ "Confidence" SG_ 777 DAS_cutinVehRelevantForControl 0;
BA_ "Confidence" SG_ 777 DAS_cutinVehDx 0;
BA_ "GenSigSNA" SG_ 777 DAS_cutinVehDx "255";
BA_ "Confidence" SG_ 777 DAS_cutinVehVxRel 0;
BA_ "GenSigSNA" SG_ 777 DAS_cutinVehVxRel "15";
BA_ "Confidence" SG_ 777 DAS_cutinVehDy 0;
BA_ "Confidence" SG_ 777 DAS_cutinVehId 0;
BA_ "GenSigSNA" SG_ 777 DAS_cutinVehId "127";
BA_ "Confidence" SG_ 777 DAS_roadSignColor 0;
BA_ "Confidence" SG_ 777 DAS_roadSignId 0;
BA_ "GenSigSNA" SG_ 777 DAS_roadSignId "255";
BA_ "Confidence" SG_ 777 DAS_roadSignStopLineDist 0;
BA_ "GenSigSNA" SG_ 777 DAS_roadSignStopLineDist "1023";
BA_ "Confidence" SG_ 777 DAS_roadSignControlActive 0;
BA_ "Confidence" SG_ 777 DAS_roadSignSource 0;
BA_ "Confidence" SG_ 777 DAS_roadSignArrow 0;
BA_ "Confidence" SG_ 777 DAS_roadSignOrientation 0;
BA_ "Confidence" SG_ 1548 DAS_TR_ObjIndex 1;
BA_ "Confidence" SG_ 1548 DAS_TR_Counter 0;
BA_ "Confidence" SG_ 1548 DAS_TR_Obj00_Class 0;
BA_ "Confidence" SG_ 1548 DAS_TR_Obj00_Dx 0;
BA_ "Confidence" SG_ 1548 DAS_TR_Obj00_Dy 0;
BA_ "Confidence" SG_ 1548 DAS_TR_Obj00_Vx 0;
BA_ "Confidence" SG_ 1548 DAS_TR_Obj00_RCS 0;
BA_ "Confidence" SG_ 1548 DAS_TR_Obj00_Length 0;
BA_ "Confidence" SG_ 1548 DAS_TR_Obj00_MovingState 0;
BA_ "Confidence" SG_ 1548 DAS_TR_Obj00_Dz 0;
BA_ "Confidence" SG_ 1548 DAS_TR_Obj00_Exist 0;
BA_ "Confidence" SG_ 1318 DIF_alertID 1;
BA_ "Confidence" SG_ 1318 DIF_alertState 1;
BA_ "Confidence" SG_ 1318 DIF_a007_phaseAcurrent 1;
BA_ "Confidence" SG_ 1318 DIF_a007_phaseBcurrent 1;
BA_ "Confidence" SG_ 1318 DIF_a007_offsetError 1;
BA_ "Confidence" SG_ 1318 DIF_a007_idFdbStdDeviation 1;
BA_ "Confidence" SG_ 1318 DIF_a007_iqFdbStdDeviation 1;
BA_ "Confidence" SG_ 1318 DIF_a011_reason 1;
BA_ "Confidence" SG_ 1318 DIF_a012_hvilStatus 1;
BA_ "GenSigSNA" SG_ 1318 DIF_a012_hvilStatus "3";
BA_ "Confidence" SG_ 1318 DIF_a012_hvilCmVoltage 1;
BA_ "Confidence" SG_ 1318 DIF_a012_hvilCurrent 1;
BA_ "Confidence" SG_ 1318 DIF_a013_errorType 1;
BA_ "Confidence" SG_ 1318 DIF_a014_motorSpeed 1;
BA_ "Confidence" SG_ 1318 DIF_a014_adState 1;
BA_ "Confidence" SG_ 1318 DIF_a014_torqueCommandFwd 1;
BA_ "Confidence" SG_ 1318 DIF_a014_brakeMasterCylPress 1;
BA_ "Confidence" SG_ 1318 DIF_a014_rmsTorqueError 1;
BA_ "Confidence" SG_ 1318 DIF_a016_newSafeState 1;
BA_ "Confidence" SG_ 1318 DIF_a016_oldSafeState 1;
BA_ "Confidence" SG_ 1318 DIF_a016_motorRPM 1;
BA_ "Confidence" SG_ 1318 DIF_a016_torqueMotor 1;
BA_ "Confidence" SG_ 1318 DIF_a016_triggerEvent 1;
BA_ "Confidence" SG_ 1318 DIF_a024_vBat 1;
BA_ "Confidence" SG_ 1318 DIF_a024_failReason 1;
BA_ "Confidence" SG_ 1318 DIF_a024_state 1;
BA_ "Confidence" SG_ 1318 DIF_a024_Ia 1;
BA_ "Confidence" SG_ 1318 DIF_a024_Ib 1;
BA_ "Confidence" SG_ 1318 DIF_a024_maxCurrMagSqrd 1;
BA_ "Confidence" SG_ 1318 DIF_a024_rotorAngle 1;
BA_ "Confidence" SG_ 1318 DIF_a025_Ia 1;
BA_ "Confidence" SG_ 1318 DIF_a025_torqueMotor 1;
BA_ "Confidence" SG_ 1318 DIF_a025_motorSpeed 1;
BA_ "Confidence" SG_ 1318 DIF_a026_Ib 1;
BA_ "Confidence" SG_ 1318 DIF_a026_torqueMotor 1;
BA_ "Confidence" SG_ 1318 DIF_a026_motorSpeed 1;
BA_ "Confidence" SG_ 1318 DIF_a027_Ic 1;
BA_ "Confidence" SG_ 1318 DIF_a027_torqueMotor 1;
BA_ "Confidence" SG_ 1318 DIF_a027_motorSpeed 1;
BA_ "Confidence" SG_ 1318 DIF_a028_phaseAirms 1;
BA_ "Confidence" SG_ 1318 DIF_a028_iArmsTorque 1;
BA_ "Confidence" SG_ 1318 DIF_a028_iArmsSpeed 1;
BA_ "Confidence" SG_ 1318 DIF_a029_phaseBirms 1;
BA_ "Confidence" SG_ 1318 DIF_a029_iBrmsTorque 1;
BA_ "Confidence" SG_ 1318 DIF_a029_iBrmsSpeed 1;
BA_ "Confidence" SG_ 1318 DIF_a030_phaseCirms 1;
BA_ "Confidence" SG_ 1318 DIF_a030_iCrmsTorque 1;
BA_ "Confidence" SG_ 1318 DIF_a030_iCrmsSpeed 1;
BA_ "Confidence" SG_ 1318 DIF_a031_phaseAoffset 1;
BA_ "Confidence" SG_ 1318 DIF_a032_phaseBoffset 1;
BA_ "Confidence" SG_ 1318 DIF_a033_phaseAcurrent 1;
BA_ "Confidence" SG_ 1318 DIF_a033_deltaIa 1;
BA_ "Confidence" SG_ 1318 DIF_a033_vRefIa 1;
BA_ "Confidence" SG_ 1318 DIF_a034_phaseBcurrent 1;
BA_ "Confidence" SG_ 1318 DIF_a034_deltaIb 1;
BA_ "Confidence" SG_ 1318 DIF_a034_vRefIb 1;
BA_ "Confidence" SG_ 1318 DIF_a035_phaseDifference 1;
BA_ "Confidence" SG_ 1318 DIF_a035_phaseCurrent 1;
BA_ "Confidence" SG_ 1318 DIF_a035_frequency 1;
BA_ "Confidence" SG_ 1318 DIF_a036_busVoltage 1;
BA_ "Confidence" SG_ 1318 DIF_a036_busHighLimit 1;
BA_ "Confidence" SG_ 1318 DIF_a037_busVoltage 1;
BA_ "Confidence" SG_ 1318 DIF_a037_busLowLimit 1;
BA_ "Confidence" SG_ 1318 DIF_a038_vBMS 1;
BA_ "Confidence" SG_ 1318 DIF_a038_vBat 1;
BA_ "Confidence" SG_ 1318 DIF_a038_iBat 1;
BA_ "Confidence" SG_ 1318 DIF_a038_reason 1;
BA_ "Confidence" SG_ 1318 DIF_a043_outletTemp 1;
BA_ "Confidence" SG_ 1318 DIF_a044_outletTemp 1;
BA_ "Confidence" SG_ 1318 DIF_a045_inletTemp 1;
BA_ "Confidence" SG_ 1318 DIF_a045_outletTemp 1;
BA_ "Confidence" SG_ 1318 DIF_a045_heatsinkTemp 1;
BA_ "Confidence" SG_ 1318 DIF_a045_outletTempSlope 1;
BA_ "Confidence" SG_ 1318 DIF_a046_statorTemp1 1;
BA_ "Confidence" SG_ 1318 DIF_a046_statorTemp2 1;
BA_ "Confidence" SG_ 1318 DIF_a047_statorTemp1 1;
BA_ "Confidence" SG_ 1318 DIF_a047_statorTslope1 1;
BA_ "Confidence" SG_ 1318 DIF_a050_statorTemp1 1;
BA_ "Confidence" SG_ 1318 DIF_a050_statorTemp2 1;
BA_ "Confidence" SG_ 1318 DIF_a054_outletTemp 1;
BA_ "Confidence" SG_ 1318 DIF_a054_heatsinkTemp 1;
BA_ "Confidence" SG_ 1318 DIF_a055_parameterDI 1;
BA_ "Confidence" SG_ 1318 DIF_a055_parameterPM 1;
BA_ "Confidence" SG_ 1318 DIF_a055_torqueType 1;
BA_ "Confidence" SG_ 1318 DIF_a055_motorRPM 1;
BA_ "Confidence" SG_ 1318 DIF_a056_pcbTemp 1;
BA_ "Confidence" SG_ 1318 DIF_a057_pcbTemp 1;
BA_ "Confidence" SG_ 1318 DIF_a058_pcbTemp 1;
BA_ "Confidence" SG_ 1318 DIF_a058_outletTemp 1;
BA_ "Confidence" SG_ 1318 DIF_a058_heatsinkTemp 1;
BA_ "Confidence" SG_ 1318 DIF_a058_pcbTempSlope 1;
BA_ "Confidence" SG_ 1318 DIF_a059_heatsinkTemp 1;
BA_ "Confidence" SG_ 1318 DIF_a060_heatsinkTemp 1;
BA_ "Confidence" SG_ 1318 DIF_a061_sensor 1;
BA_ "Confidence" SG_ 1318 DIF_a061_reason 1;
BA_ "Confidence" SG_ 1318 DIF_a061_phTemp 1;
BA_ "Confidence" SG_ 1318 DIF_a061_otherTemp 1;
BA_ "Confidence" SG_ 1318 DIF_a062_limpReason 1;
BA_ "Confidence" SG_ 1318 DIF_a064_interventionType 1;
BA_ "Confidence" SG_ 1318 DIF_a064_torqueCmdState 1;
BA_ "GenSigSNA" SG_ 1318 DIF_a064_torqueCmdState "0";
BA_ "Confidence" SG_ 1318 DIF_a066_canID 1;
BA_ "Confidence" SG_ 1318 DIF_a066_errorType 1;
BA_ "Confidence" SG_ 1318 DIF_a069_motorSpeed 1;
BA_ "Confidence" SG_ 1318 DIF_a069_rotorCoolingPower 1;
BA_ "Confidence" SG_ 1318 DIF_a069_rotorMagnetTemp 1;
BA_ "Confidence" SG_ 1318 DIF_a069_fittedTorqueLimit 1;
BA_ "Confidence" SG_ 1318 DIF_a072_reason 1;
BA_ "Confidence" SG_ 1318 DIF_a073_motorSpeedrpm 1;
BA_ "Confidence" SG_ 1318 DIF_a075_motorSpeed 1;
BA_ "Confidence" SG_ 1318 DIF_a075_absSpeed 1;
BA_ "Confidence" SG_ 1318 DIF_a076_lvSupplyV 1;
BA_ "Confidence" SG_ 1318 DIF_a077_lvSupplyV 1;
BA_ "Confidence" SG_ 1318 DIF_a090_reason 1;
BA_ "Confidence" SG_ 1318 DIF_a094_canID 1;
BA_ "Confidence" SG_ 1318 DIF_a094_errorType 1;
BA_ "Confidence" SG_ 1318 DIF_a097_errorType 1;
BA_ "Confidence" SG_ 1318 DIF_a098_fluxState 1;
BA_ "Confidence" SG_ 1318 DIF_a103_fluidTorDeltaT 1;
BA_ "Confidence" SG_ 1318 DIF_a103_inverterTemp 1;
BA_ "Confidence" SG_ 1318 DIF_a103_rmsCurrent 1;
BA_ "Confidence" SG_ 1318 DIF_a103_ambientTemp 1;
BA_ "Confidence" SG_ 1318 DIF_a103_sensorTempEst 1;
BA_ "Confidence" SG_ 1318 DIF_a108_blockingAlert 1;
BA_ "Confidence" SG_ 1318 DIF_a112_phaseAcurrent 1;
BA_ "Confidence" SG_ 1318 DIF_a112_phaseBcurrent 1;
BA_ "Confidence" SG_ 1318 DIF_a113_heatsink1Temp 1;
BA_ "Confidence" SG_ 1318 DIF_a113_heatsink2Temp 1;
BA_ "Confidence" SG_ 1318 DIF_a113_heatsink3Temp 1;
BA_ "Confidence" SG_ 1318 DIF_a121_badRegReason 1;
BA_ "Confidence" SG_ 1318 DIF_a121_torqueDelta 1;
BA_ "Confidence" SG_ 1318 DIF_a121_badCurrent 1;
BA_ "Confidence" SG_ 1318 DIF_a121_badFlux 1;
BA_ "Confidence" SG_ 1318 DIF_a123_lossReason 1;
BA_ "Confidence" SG_ 1318 DIF_a123_busVoltage 1;
BA_ "Confidence" SG_ 1318 DIF_a123_badFlux 1;
BA_ "Confidence" SG_ 1318 DIF_a123_lossRequest 1;
BA_ "Confidence" SG_ 1318 DIF_a123_badCurrent 1;
BA_ "Confidence" SG_ 1318 DIF_a123_motorRPM 1;
BA_ "Confidence" SG_ 1318 DIF_a123_varianceD 1;
BA_ "Confidence" SG_ 1318 DIF_a123_varianceQ 1;
BA_ "Confidence" SG_ 1318 DIF_a126_limpReason 1;
BA_ "Confidence" SG_ 1318 DIF_a127_gpoReason 1;
BA_ "Confidence" SG_ 1318 DIF_a127_temp 1;
BA_ "Confidence" SG_ 1318 DIF_a133_capacitorTemp 1;
BA_ "Confidence" SG_ 1318 DIF_a133_badValue1 1;
BA_ "Confidence" SG_ 1318 DIF_a133_badValue2 1;
BA_ "Confidence" SG_ 1318 DIF_a134_wheelSpeedDiffFrL 1;
BA_ "Confidence" SG_ 1318 DIF_a134_wheelSpeedDiffFrR 1;
BA_ "Confidence" SG_ 1318 DIF_a134_wheelSpeedDiffReL 1;
BA_ "Confidence" SG_ 1318 DIF_a134_wheelSpeedDiffReR 1;
BA_ "SystemSignalLongSymbol" SG_ 1318 DIF_a144_packPerformanceDeviatio "DIF_a144_packPerformanceDeviation";
BA_ "Confidence" SG_ 1318 DIF_a147_accumulatedWear 1;
BA_ "Confidence" SG_ 1318 DIF_a149_flow 1;
BA_ "GenSigSNA" SG_ 1318 DIF_a149_flow "255";
BA_ "Confidence" SG_ 1318 DIF_a149_voltage 1;
BA_ "Confidence" SG_ 1318 DIF_a149_temperature 1;
BA_ "Confidence" SG_ 1318 DIF_a149_state 1;
BA_ "GenSigSNA" SG_ 1318 DIF_a149_state "7";
BA_ "Confidence" SG_ 1318 DIF_a149_pcbaID 1;
BA_ "Confidence" SG_ 1318 DIF_a150_vBatRawMinusFiltered 1;
BA_ "Confidence" SG_ 1318 DIF_a150_vBatFilteredRate 1;
BA_ "Confidence" SG_ 1318 DIF_a150_elapsedMs 1;
BA_ "Confidence" SG_ 1318 DIF_a150_energy 1;
BA_ "Confidence" SG_ 1318 DIF_a152_errorType 1;
BA_ "Confidence" SG_ 1318 DIF_a153_oilFlow 1;
BA_ "GenSigSNA" SG_ 1318 DIF_a153_oilFlow "255";
BA_ "Confidence" SG_ 1318 DIF_a153_oilTemperature 1;
BA_ "GenSigSNA" SG_ 1318 DIF_a153_oilTemperature "255";
BA_ "Confidence" SG_ 1318 DIF_a153_phaseCurrent 1;
BA_ "GenSigSNA" SG_ 1318 DIF_a153_phaseCurrent "255";
BA_ "Confidence" SG_ 1318 DIF_a153_dcVoltage 1;
BA_ "GenSigSNA" SG_ 1318 DIF_a153_dcVoltage "255";
BA_ "Confidence" SG_ 1318 DIF_a153_lowPressPlausibility 1;
BA_ "Confidence" SG_ 1318 DIF_a153_state 1;
BA_ "GenSigSNA" SG_ 1318 DIF_a153_state "7";
BA_ "Confidence" SG_ 1318 DIF_a153_oilPumpAlert 1;
BA_ "Confidence" SG_ 1318 DIF_a153_reason 1;
BA_ "Confidence" SG_ 1318 DIF_a154_motorRPM 1;
BA_ "Confidence" SG_ 1318 DIF_a154_phaseError 1;
BA_ "Confidence" SG_ 1318 DIF_a154_commonGain 1;
BA_ "Confidence" SG_ 1318 DIF_a160_vBatRawMinusFiltered 1;
BA_ "Confidence" SG_ 1318 DIF_a160_vBatFilteredRate 1;
BA_ "Confidence" SG_ 1318 DIF_a160_elapsedMs 1;
BA_ "Confidence" SG_ 1318 DIF_a160_energy 1;
BA_ "Confidence" SG_ 1318 DIF_a202_reason 1;
BA_ "Confidence" SG_ 1318 DIF_a202_movement 1;
BA_ "Confidence" SG_ 1318 DIF_a202_sysStateExitCondition 1;
BA_ "Confidence" SG_ 1318 DIF_a244_irSensorV 1;
BA_ "SystemSignalLongSymbol" SG_ 1318 DIF_a244_plausibleSingleSwitchSh "DIF_a244_plausibleSingleSwitchShortOnly";
BA_ "Confidence" SG_ 1318 DIF_a246_codeBranch 1;
BA_ "Confidence" SG_ 1318 DIF_a246_motorRPM 1;
BA_ "Confidence" SG_ 1318 DIF_a246_eepromOffsetIa 1;
BA_ "Confidence" SG_ 1318 DIF_a246_eepromOffsetIb 1;
BA_ "Confidence" SG_ 1318 DIF_a247_rotorOffsetEst 1;
BA_ "Confidence" SG_ 1318 DIF_a247_motorRPM 1;
BA_ "Confidence" SG_ 1318 DIF_a247_torqueMotor 1;
BA_ "Confidence" SG_ 1318 DIF_a251_oilFlow 1;
BA_ "GenSigSNA" SG_ 1318 DIF_a251_oilFlow "255";
BA_ "Confidence" SG_ 1318 DIF_a251_oilTemperature 1;
BA_ "GenSigSNA" SG_ 1318 DIF_a251_oilTemperature "255";
BA_ "Confidence" SG_ 1318 DIF_a251_dcVoltage 1;
BA_ "GenSigSNA" SG_ 1318 DIF_a251_dcVoltage "255";
BA_ "Confidence" SG_ 1318 DIF_a251_dcCurrent 1;
BA_ "GenSigSNA" SG_ 1318 DIF_a251_dcCurrent "255";
BA_ "Confidence" SG_ 1318 DIF_a251_phaseCurrent 1;
BA_ "GenSigSNA" SG_ 1318 DIF_a251_phaseCurrent "255";
BA_ "Confidence" SG_ 1318 DIF_a251_leadAngle 1;
BA_ "Confidence" SG_ 1318 DIF_a251_reason 1;
BA_ "SystemSignalLongSymbol" SG_ 854 DIF_a039_exceptionUndefinedInstr "DIF_a039_exceptionUndefinedInstruction";
BA_ "SystemSignalLongSymbol" SG_ 855 DIF_a081_P0BFF_DIF_EM_CurrentHig "DIF_a081_P0BFF_DIF_EM_CurrentHigh";
BA_ "SystemSignalLongSymbol" SG_ 855 DIF_a083_PABCD_DIF_ECU_DemoWindo "DIF_a083_PABCD_DIF_ECU_DemoWindow";
VAL_ 528 CP_type 3 "CP_TYPE_IEC_CCS" 2 "CP_TYPE_GB" 1 "CP_TYPE_EURO_IEC" 0 "CP_TYPE_US_TESLA" ;
VAL_ 528 CP_latchState 3 "CP_LATCH_BLOCKING" 2 "CP_LATCH_ENGAGED" 1 "CP_LATCH_DISENGAGED" 0 "CP_LATCH_SNA" ;
VAL_ 528 CP_doorControlState 6 "CP_doorSenseClosed" 5 "CP_doorClosing" 4 "CP_doorSenseOpen" 3 "CP_doorOpening" 2 "CP_doorOpenRequested" 1 "CP_doorIdle" 0 "CP_doorInit" ;
VAL_ 528 CP_chargeCableState 2 "CHARGE_CABLE_CONNECTED" 1 "CHARGE_CABLE_NOT_CONNECTED" 0 "CHARGE_CABLE_UNKNOWN_SNA" ;
VAL_ 528 CP_latchControlState 5 "CP_latchEngaging" 4 "CP_latchDisengaged" 3 "CP_latchDisengaging" 2 "CP_latchDisengageRequested" 1 "CP_latchIdle" 0 "CP_latchInit" ;
VAL_ 528 CP_ledColor 13 "CP_LEDS_FLASHING_WHITE" 12 "CP_LEDS_FADING_OUT" 11 "CP_LEDS_FLASHING_PURPLE" 10 "CP_LEDS_FLASHING_BLUE" 9 "CP_LEDS_DEBUG" 8 "CP_LEDS_RAVE" 7 "CP_LEDS_AMBER" 6 "CP_LEDS_FLASHING_AMBER" 5 "CP_LEDS_FLASHING_GREEN" 4 "CP_LEDS_WHITE" 3 "CP_LEDS_BLUE" 2 "CP_LEDS_GREEN" 1 "CP_LEDS_RED" 0 "CP_LEDS_OFF" ;
VAL_ 528 CP_faultLineSensed 1 "FAULT_LINE_SET" 0 "FAULT_LINE_CLEARED" ;
VAL_ 528 CP_doorPresenceState 7 "CP_DOOR_PRESENCE_STATE_FAULT" 6 "CP_DOOR_PRESENCE_STATE_OFF_CHARGE" 5 "CP_DOOR_PRESENCE_STATE_OFF_DRIVE" 4 "CP_DOOR_PRESENCE_STATE_NOT_PRESENT" 3 "CP_DOOR_PRESENCE_STATE_PRESENT" 2 "CP_DOOR_PRESENCE_STATE_INIT_FROM_DRIVE" 1 "CP_DOOR_PRESENCE_STATE_INIT_FROM_CHARGE" 0 "CP_DOOR_PRESENCE_STATE_INIT" ;
VAL_ 528 CP_inductiveSensorState 7 "CP_INDUCTIVE_SENSOR_CONFIG" 6 "CP_INDUCTIVE_SENSOR_RESET" 5 "CP_INDUCTIVE_SENSOR_FAULT" 4 "CP_INDUCTIVE_SENSOR_WAIT_FOR_INIT" 3 "CP_INDUCTIVE_SENSOR_PAUSE" 2 "CP_INDUCTIVE_SENSOR_SHUTDOWN" 1 "CP_INDUCTIVE_SENSOR_POLL" 0 "CP_INDUCTIVE_SENSOR_INIT" ;
VAL_ 528 CP_coldWeatherMode 1 "CP_COLD_WEATHER_LATCH_MITIGATION" 0 "CP_COLD_WEATHER_NONE" ;
VAL_ 528 CP_inletHeaterUiState 4 "CP_HEATER_FAULTED" 3 "CP_HEATER_ENABLED" 2 "CP_HEATER_AVAILABLE" 1 "CP_HEATER_NOT_AVAILABLE" 0 "CP_HEATER_NOT_SUPPORTED" ;
VAL_ 893 CP_thermalStatusSelect 1 "1" 0 "0" ;
VAL_ 583 DAS_roadEstimator 3 "ROAD_ESTIMATOR_CRITICAL" 2 "ROAD_ESTIMATOR_DEGRADED" 1 "ROAD_ESTIMATOR_UNSTABLE_MEASUREMENTS" 0 "ROAD_ESTIMATOR_HEALTHY" ;
VAL_ 583 DAS_arbiterBehavior 4 "ARBITER_CITY_STREETS" 3 "ARBITER_LANE_CHANGE_RIGHT" 2 "ARBITER_LANE_CHANGE_LEFT" 1 "ARBITER_IN_LANE" 0 "ARBITER_INVALID" ;
VAL_ 583 DAS_mapAvailability 1 "APM_MAP_AVAILABLE" 0 "APM_MAP_NOT_AVAILABLE" ;
VAL_ 583 DAS_controllerRef 6 "CONTROLLER_REFERENCE_INDETERMINATE" 5 "CONTROLLER_REFERENCE_REF_TOO_SHORT" 4 "CONTROLLER_REFERENCE_BAD_REF_UPDATE" 3 "CONTROLLER_REFERENCE_STALE_LOCALIZATION" 2 "CONTROLLER_REFERENCE_STALE_REFERENCE" 1 "CONTROLLER_REFERENCE_UNHEALTHY" 0 "CONTROLLER_REFERENCE_HEALTHY" ;
VAL_ 583 DAS_alcInternalState 12 "ALC_RETRY" 11 "ALC_SOFT_ABORTING_RIGHT" 10 "ALC_SOFT_ABORTING_LEFT" 9 "ALC_ACTIVE_ACC_RIGHT" 8 "ALC_ACTIVE_ACC_LEFT" 7 "ALC_ACTIVE_RIGHT" 6 "ALC_ACTIVE_LEFT" 5 "ALC_PRE_ACTIVE_RIGHT" 4 "ALC_PRE_ACTIVE_LEFT" 3 "ALC_BEHAVIOR_CHECK" 2 "ALC_ABORTING" 1 "ALC_IDLE" 0 "ALC_DISABLED" ;
VAL_ 583 DAS_behaviorReport 71 "BEHAVIOR_MAX_SPEED_IN_REVERSE" 70 "BEHAVIOR_STOPPING_FOR_GEAR_CHANGE" 69 "BEHAVIOR_ROAD_SPEED" 68 "BEHAVIOR_CAMERA_FAILSAFES" 67 "BEHAVIOR_CAUTION_LIGHTS" 66 "BEHAVIOR_DRY_STEERING" 65 "BEHAVIOR_CREEP_FOR_SHORT_REF" 64 "BEHAVIOR_FAILED_LANE_CHANGE" 63 "BEHAVIOR_AHB_MANUAL_OVERRIDE" 62 "BEHAVIOR_FORWARD_LATERAL_OBJECT" 61 "BEHAVIOR_POOR_VISIBILITY" 60 "BEHAVIOR_MAIN_CAMERA_SUN_GLARE" 59 "BEHAVIOR_CITY_MERGE_OBJECT" 58 "BEHAVIOR_TRAJECTORY_OUTLIER_PRESSURE" 57 "BEHAVIOR_REFERENCE_LENGTH" 56 "BEHAVIOR_PATH_BLOCKED_BEYOND_TRAJ" 55 "BEHAVIOR_PATH_BLOCKED" 54 "BEHAVIOR_UNSUPPORTED_MANEUVER" 53 "BEHAVIOR_CROSSING_OBJECT" 52 "BEHAVIOR_CLEAR_TO_GO" 51 "BEHAVIOR_APPROACHING_TURN" 50 "BEHAVIOR_DYNAMIC_PINCH_POINT" 49 "BEHAVIOR_VANISHING_CIPV_KEEP_CALM" 48 "BEHAVIOR_ONRAMP_BOOST" 47 "BEHAVIOR_TRAFFIC_CONTROL_LAUNCH" 46 "BEHAVIOR_NARROW_CORRIDOR" 45 "BEHAVIOR_SPEED_BUMP" 44 "BEHAVIOR_SUGGESTED_VISION_SPEED" 43 "BEHAVIOR_ROUNDABOUT" 42 "BEHAVIOR_TOLLBOOTH" 41 "BEHAVIOR_CROSS_TRAFFIC_AVOIDANCE" 40 "BEHAVIOR_CROSSWALK" 39 "BEHAVIOR_RELEVANT_VRU" 38 "BEHAVIOR_RISK_MANAGER" 37 "BEHAVIOR_STATIC_OBJECT_MERGE_RIGHT" 36 "BEHAVIOR_STATIC_OBJECT_MERGE_LEFT" 35 "BEHAVIOR_CUTIN_VEHICLE" 34 "BEHAVIOR_STATIC_OBJECT" 33 "BEHAVIOR_LANE_SPEED_DIFF" 32 "BEHAVIOR_END_OF_NAV_ROUTE" 31 "BEHAVIOR_STEERING_SATURATED" 30 "BEHAVIOR_ACTIVE_SAFETY_SLOWDOWN" 29 "BEHAVIOR_MP_AP_INACTIVE" 28 "BEHAVIOR_MP_ULC" 27 "BEHAVIOR_MP_DI_CRUISE" 26 "BEHAVIOR_MP_AP_STATE_MACHINE" 25 "BEHAVIOR_MP_DRIVER_MONITOR" 24 "BEHAVIOR_MP_NOT_BUCKLED" 23 "BEHAVIOR_MP_AP_RESTRICTION" 22 "BEHAVIOR_CUTIN_VEHICLE_RIGHT" 21 "BEHAVIOR_CUTIN_VEHICLE_LEFT" 20 "BEHAVIOR_MERGE_VEHICLE_RIGHT" 19 "BEHAVIOR_MERGE_VEHICLE_LEFT" 18 "BEHAVIOR_NAV_PATH_CSA" 17 "BEHAVIOR_NAV_FLEET_SPEEDS" 16 "BEHAVIOR_VISION_SPEEDS" 15 "BEHAVIOR_SLOWING_FOR_TARGET_LANE" 14 "BEHAVIOR_DRIVABLE_SPACE_VIOLATION" 13 "BEHAVIOR_MAP_LANE_GEOMETRY" 12 "BEHAVIOR_VISION_LANE_GEOMETRY" 11 "BEHAVIOR_TRAFFIC_CONTROL" 10 "BEHAVIOR_UNDERTAKE_VEHICLE" 9 "BEHAVIOR_TARGET_LANE_VEHICLE" 8 "BEHAVIOR_IN_LANE_VEHICLE" 7 "BEHAVIOR_UNDERTAKE_ASSIST_KEEP_CALM" 6 "BEHAVIOR_TRAFFIC_CONTROL_STOPPED_STATE" 5 "BEHAVIOR_FLEET_SPEEDS" 4 "BEHAVIOR_KEEP_CALM" 3 "BEHAVIOR_RADAR_ONLY_BRAKING" 2 "BEHAVIOR_CURVE_SPEED_ADAPTATION" 1 "BEHAVIOR_VIEW_RANGE" ;
VAL_ 583 DAS_controllerHealth 3 "CONTROLLER_SOLVER_FAILURE" 2 "CONTROLLER_CRITICAL" 1 "CONTROLLER_DEGRADED" 0 "CONTROLLER_HEALTHY" ;
VAL_ 583 DAS_autopilotAbortReason 255 "ABORT_REASON_MAX" 80 "ABORT_DRIVER_SEAT_TRAVEL" 79 "ABORT_DRIVER_OCCLUDED_DISTRACTED" 78 "ABORT_DRIVER_REACHING_DISTRACTED" 77 "ABORT_LOW_CABIN_ILLUMINANCE" 76 "ABORT_CABIN_CAM_OCCLUSION_DNP" 75 "ABORT_DRIVER_OCCLUDED" 74 "ABORT_DRIVER_NOT_DETECTED_SELFIE" 73 "ABORT_DRIVER_E2E_UNKNOWN" 72 "ABORT_DRIVER_EMPTY_SEAT" 71 "ABORT_DRIVER_SEAT_RECLINED" 70 "ABORT_FSD_REGION_NOT_ALLOWED" 69 "ABORT_FERRY_CROSSING" 68 "ABORT_DOOR_OPEN" 67 "ABORT_FRUNK_OPEN" 66 "ABORT_TRUNK_OPEN" 65 "ABORT_CABIN_CAM_ISSUE" 64 "ABORT_TASK_FLOW_TRACE_TIMEOUT" 63 "ABORT_SEALED_MERGE_CROSSING" 62 "ABORT_FSD_GEOFENCE_DISABLED" 61 "ABORT_EXTENDED_COMPUTE_INACTIVE_PCIE_LINK_HEALTH" 60 "ABORT_EXTENDED_COMPUTE_INACTIVE_ETHERNET_LINK_HEALTH" 59 "ABORT_EXTENDED_COMPUTE_INACTIVE_OTHER_SOC_HEALTH_CRITICAL" 58 "ABORT_EXTENDED_COMPUTE_INACTIVE_OTHER_SOC_HEALTH_UNKNOWN" 57 "ABORT_CABIN_CAM_BLIND" 56 "ABORT_AHB_MANUAL_OVERRIDE" 55 "ABORT_DRIVER_NOT_PRESENT" 54 "ABORT_PERCEPTION_HEALTH_STALE" 53 "ABORT_PERCEPTION_HEALTH_POST_PROCESSING" 52 "ABORT_EXTENDED_COMPUTE_INACTIVE" 51 "ABORT_CITY_STREETS_REF_TOO_SHORT" 50 "ABORT_INVALID_BEHAVIOR" 49 "ABORT_ONCOMING_LANE" 48 "ABORT_HEADLIGHT_OFF_AT_NIGHT" 47 "ABORT_IBOOSTER_MIA" 46 "ABORT_INTEGRATOR_HEALTH_CRITICAL" 45 "ABORT_USER_OVERRIDE_STRIKEOUT" 44 "ABORT_SEATBELT_UNBUCKLED" 43 "ABORT_PERCEPTION_HEALTH_VISION" 42 "ABORT_INVALID_VEHICLE_SPEED" 41 "ABORT_INVALID_DI_PEDAL_POS" 40 "ABORT_W048_FEATURES_DISABLED" 39 "ABORT_EPAS_STEERING_ANGLE_INVALID" 38 "ABORT_STEERING_SATURATED_LANE_DEPARTURE" 37 "ABORT_REACHED_END_OF_NAV_STOP" 36 "ABORT_GORE_INCURSION" 35 "ABORT_MISSION_PLANNER_NO_VISION_LANES_FOUND" 34 "ABORT_CONTROLLER_REF_TOO_SHORT" 33 "ABORT_AEB" 32 "ABORT_CONTROLLER_BAD_REF_UPDATE" 31 "ABORT_CONTROLLER_STALE_LOCALIZATION" 30 "ABORT_CONTROLLER_STALE_REFERENCE" 29 "ABORT_MAP_HEALTH" 28 "ABORT_THERMAL_ISSUE" 27 "ABORT_CONTROLLER_NOT_ALLOWED" 26 "ABORT_CONTROLLER_SOLVER" 25 "ABORT_CONTROLLER_REFERENCE" 24 "ABORT_ROAD_ESTIMATOR_HEALTH" 23 "ABORT_ACC_FAULT" 22 "ABORT_ACC_CANCEL_SILENT" 21 "ABORT_ACC_CANCEL_GENERIC" 20 "ABORT_RADAR_FAULT" 19 "ABORT_RADAR_BLIND" 18 "ABORT_CAMERA_CALIBRATION" 17 "ABORT_CAMERA_FAILSAFES" 16 "ABORT_EPAS_EAC_ERROR" 15 "ABORT_EPAS_EAC_NOT_ACTIVE" 14 "ABORT_VEHICLE_SPEED_ABOVE_MAX" 13 "ABORT_TRAILER_MODE_ACTIVE" 12 "ABORT_USER_DISABLED" 11 "ABORT_CRUISE_NOT_ACTIVE" 10 "ABORT_CRUISE_FAULT" 9 "ABORT_VCRIGHT_MIA" 8 "ABORT_VCFRONT_MIA" 7 "ABORT_RADAR_MIA" 6 "ABORT_SCCM_MIA" 5 "ABORT_GTW_MIA" 4 "ABORT_EPAS_MIA" 3 "ABORT_ESP_MIA" 2 "ABORT_DI_MIA" 1 "ABORT_WATCHDOG_HEALTH" 0 "ABORT_NONE" ;
VAL_ 583 DAS_rqstedBehaviorStatus 22 "RQST_BEHAVIOR_INVALID_PLAN" 21 "RQST_BEHAVIOR_BLOCKED_BY_SLOW_TARGET_R" 20 "RQST_BEHAVIOR_BLOCKED_BY_SLOW_TARGET_L" 19 "RQST_BEHAVIOR_BAD_ORIGIN_UPDATE" 18 "RQST_BEHAVIOR_OUT_OF_DATE" 17 "RQST_BEHAVIOR_ROAD_NOT_APPROPRIATE" 16 "RQST_BEHAVIOR_BLOCKED_BY_LANE_TYPE_R" 15 "RQST_BEHAVIOR_BLOCKED_BY_ULTRASOUND_AND_CAMERA_R" 14 "RQST_BEHAVIOR_BLOCKED_BY_BLINDSPOT_CAMERA_INVALID_R" 13 "RQST_BEHAVIOR_BLOCKED_BY_BLINDSPOT_CAMERA_R" 12 "RQST_BEHAVIOR_BLOCKED_BY_ULTRASOUND_R" 11 "RQST_BEHAVIOR_BLOCKED_BY_LANE_TYPE_L" 10 "RQST_BEHAVIOR_BLOCKED_BY_ULTRASOUND_AND_CAMERA_L" 9 "RQST_BEHAVIOR_BLOCKED_BY_BLINDSPOT_CAMERA_INVALID_L" 8 "RQST_BEHAVIOR_BLOCKED_BY_BLINDSPOT_CAMERA_L" 7 "RQST_BEHAVIOR_BLOCKED_BY_ULTRASOUND_L" 6 "RQST_BEHAVIOR_BUILD_ARGUMENT_FAIL" 5 "RQST_BEHAVIOR_NO_TARGET_LANE_ON_MAP" 4 "RQST_BEHAVIOR_NO_SOURCE_LANE_ON_MAP" 3 "RQST_BEHAVIOR_MAP_NOT_INITIALIZED" 2 "RQST_BEHAVIOR_NO_DEST_POLYLANE" 1 "RQST_BEHAVIOR_NO_SRC_POLYLANE" 0 "RQST_BEHAVIOR_VALID" ;
VAL_ 583 DAS_forkState 29 "FORK_AWAITING_CONFIRMATION_RIGHT" 28 "FORK_AWAITING_CONFIRMATION_LEFT" 27 "FORK_UNAVAILABLE_INTERSECTION_ACTIVE" 26 "FORK_PRE_ACTIVE_RIGHT_NAV" 25 "FORK_PRE_ACTIVE_LEFT_NAV" 24 "FORK_UNAVAILABLE_WEATHER" 23 "FORK_UNAVAILABLE_TIGHT_TURN_RADIUS" 22 "FORK_ABORT_OTHER" 21 "FORK_ABORT_DISALLOW" 20 "FORK_ABORT_NOT_RIGHT_LANE" 19 "FORK_ABORT_NOT_LEFT_LANE" 18 "FORK_ABORT_BLINKER_CHANGE" 17 "FORK_ABORT_CONTROL_INACTIVE" 16 "FORK_FORK_COMPLETE" 15 "FORK_ACTIVE_RIGHT_USER" 14 "FORK_ACTIVE_RIGHT_NAV" 13 "FORK_ACTIVE_LEFT_USER" 12 "FORK_ACTIVE_LEFT_NAV" 11 "FORK_IDLE_NO_FORKS_AVAILABLE" 10 "FORK_IDLE_RIGHT_FORK_AVAILABLE" 9 "FORK_IDLE_LEFT_FORK_AVAILABLE" 8 "FORK_IDLE_BOTH_FORKS_AVAILABLE" 7 "FORK_UNAVAILABLE_OTHER" 6 "FORK_UNAVAILABLE_TOLL_BOOTH" 5 "FORK_UNAVAILABLE_DON_INACTIVE" 4 "FORK_UNAVAILABLE_CONTROLLED_ACCESS_TOO_FAR" 3 "FORK_UNAVAILABLE_CONSTRUCTION" 2 "FORK_UNAVAILABLE_AP_INACTIVE" 1 "FORK_UNAVAILABLE_DISABLED" 0 "FORK_INVALID" ;
VAL_ 583 DAS_laneChangeState 63 "LANE_CHANGE_UNKNOWN" 43 "LANE_CHANGE_ABORTING_DESTINATION_LANE_UNSTABLE" 42 "LANE_CHANGE_UNAVAILABLE_AUTOPILOT_ABORTING" 41 "LANE_CHANGE_UNAVAILABLE_BLINKER_LATCHED" 40 "LANE_CHANGE_ABORTING_SNOOZED" 39 "LANE_CHANGE_ABORTING_SOURCE_AND_TARGET_LANES_MERGED" 38 "LANE_CHANGE_UNAVAILABLE_NO_REAR_OBJECT" 37 "LANE_CHANGE_ABORTING_NO_HANDS_ON" 36 "LANE_CHANGE_UNAVAILABLE_BLINDSPOT_RESTRICTED" 35 "LANE_CHANGE_ABORTING_WEATHER" 34 "LANE_CHANGE_ABORTING_TIGHT_TURN_RADIUS" 33 "LANE_CHANGE_ABORTING_TOLL_BOOTH_DETECTED" 32 "LANE_CHANGE_ABORTING_CONSTRUCTION_DETECTED" 31 "LANE_CHANGE_ABORTING_GORE_POINT" 30 "LANE_CHANGE_BLOCKED_RIGHT" 29 "LANE_CHANGE_BLOCKED_LEFT" 28 "LANE_CHANGE_IN_PROGRESS_RIGHT" 27 "LANE_CHANGE_IN_PROGRESS_LEFT" 26 "LANE_CHANGE_ABORTING_ALC_REQUEST_BEFORE_ULC_CONFIRM" 25 "LANE_CHANGE_ABORTING_ULC_CONFIRMATION_TIMEOUT" 24 "LANE_CHANGE_ABORTING_HIGH_ALC_PROGRESS_ERROR" 23 "LANE_CHANGE_ABORTING_BEHAVIOR_CHANGED" 22 "LANE_CHANGE_ABORTING_BELOW_MIN_SPEED" 21 "LANE_CHANGE_ABORTING_INVALID_BEHAVIOR" 20 "LANE_CHANGE_ABORTING_ULC_BLINKER_TIMEOUT" 19 "LANE_CHANGE_ABORTING_ACC_AUTOSTEER_ACTIVATED" 18 "LANE_CHANGE_ABORTING_LOST_VISION_POSE" 17 "LANE_CHANGE_ABORTING_FORK_AVAILABLE" 16 "LANE_CHANGE_ABORTING_LINE_TYPE" 15 "LANE_CHANGE_ABORTING_INVALID_MODE" 14 "LANE_CHANGE_ABORTING_BLIND_SPOT_OCCUPIED" 13 "LANE_CHANGE_ABORTING_TIMEOUT" 12 "LANE_CHANGE_ABORTING_BLINKER" 11 "LANE_CHANGE_ABORTING_INACTIVE" 10 "LANE_CHANGE_AVAILABLE_BOTH" 9 "LANE_CHANGE_AVAILABLE_RIGHT_ONLY" 8 "LANE_CHANGE_AVAILABLE_LEFT_ONLY" 7 "LANE_CHANGE_UNAVAILABLE_INVALID_MODE" 6 "LANE_CHANGE_UNAVAILABLE_ULTRASONICS_NOT_READY" 5 "LANE_CHANGE_UNAVAILABLE_FORK_MODE" 4 "LANE_CHANGE_UNAVAILABLE_INACTIVE" 3 "LANE_CHANGE_UNAVAILABLE_NO_LANES" 2 "LANE_CHANGE_UNAVAILABLE_SPEED" 1 "LANE_CHANGE_UNAVAILABLE_ROAD_NOT_APPROPRIATE" 0 "LANE_CHANGE_UNAVAILABLE_DISABLED" ;
VAL_ 583 DAS_lastWatchdogCode 127 "TRIP_HISTORY_FAILED" 126 "TEXT_LOG_FAILED" 125 "AUTOPILOT_OBJECT_POSE_FAILED" 124 "RELOCALIZATION_FAILED" 123 "SLAM_MAPPING_FAILED" 122 "SLAM_BATCH_CALIB_FAILED" 121 "SLAM_BA_FAILED" 120 "SLAM_FAILED" 119 "RTDV_STREAMER_FAILED" 118 "RTDV_COMPRESSOR_FAILED" 117 "REPLAY_FAILED" 116 "REMOTE_ACCESS_FAILED" 115 "PT_TRACKER_FAILED" 114 "PERFORMANCE_COUNTER_MONITOR_FAILED" 113 "METRICS_DEV_FAILED" 112 "METRICS_API_FAILED" 111 "METRICS_FAILED" 110 "LOGGING_LOAD_GENERATOR_FAILED" 109 "LIDAR_FAILED" 108 "HTTP_SERVER_FAILED" 107 "FRAME_DECODER_FAILED" 106 "INFERENCE_ENGINE_FAILED" 105 "FACTORY_CAMERA_CALIBRATION_FAILED" 104 "DV_INSPECTOR_FAILED" 103 "DETERMINATOR_FAILED" 102 "DASH_CAM_FAILED" 101 "CLIP_REMOTE_WRITER_FAILED" 100 "COMPRESSOR_FAILED" 99 "FTRACE_SNAPSHOT_FAILED" 98 "SWITCH_MONITOR_FAILED" 97 "BLUEFIN_FAILED" 96 "BACKUP_CAMERA_FAILED" 95 "AUTONOMOUS_BEHAVIORS_FAILED" 94 "AUDIO_PROCESSOR_FAILED" 93 "CAMERA_HEALTH_FAILED" 92 "POSITIONING_ENGINE_FAILED" 91 "AUDIO_FAILED" 90 "IMU_CALIBRATION_FAILED" 89 "RADAR_EXTENDED_FAILED" 88 "TILE_PROVIDER_FAILED" 87 "RADAR_RECEIVER_FAILED" 86 "TELEMETRY_COMPLIANCE_FAILED" 85 "GEO_REGION_FAILED" 84 "FLEET_CONFIG_FAILED" 83 "X1_CLIENT_FAILED" 82 "SYNC_PIPELINE_FAILED" 81 "RADAR_FAILED" 80 "ULTRASONICS_FAILED" 79 "BEV_GRAPH_FAILED" 78 "CITY_STREETS_BEHAVIOR_FAILED" 77 "BRIDGE_FAILED" 76 "SCHEDULER_FAILED" 75 "DRIVABLE_SPACE_TRACKER_FAILED" 74 "CLIP_LOGGER_FAILED" 73 "HW_MONITOR_FAILED" 72 "PARKING_BEHAVIOR_FAILED" 71 "FIELD_CALIBRATION_FAILED" 70 "DYNAMICS_FAILED" 69 "UI_SERVER_FAILED" 68 "ACTIVE_SAFETY_FAILED" 67 "CAMERA_FAILED" 66 "MAP_MANAGER_FAILED" 65 "DRIVER_MONITOR_FAILED" 64 "MODEL_TOOLS_FAILED" 63 "LANE_CHANGE_BEHAVIOR_FAILED" 62 "UBX_LOG_FAILED" 61 "IMU_FAILED" 60 "RAIN_LIGHT_SENSING_FAILED" 59 "SNAPSHOT_TRIGGER_CLIENT_FAILED" 58 "STAY_IN_LANE_BEHAVIOR_FAILED" 57 "ATLAS_FAILED" 56 "ROAD_ESTIMATOR_FAILED" 55 "PERCEPTION_FAILED" 54 "MISSION_PLANNER_FAILED" 53 "LOCALIZER_FAILED" 52 "CONTROLLER_FAILED" 51 "AP_STATE_MACHINE_FAILED" 50 "ARBITER_FAILED" 49 "GPS_FAILED" 48 "INERTIATOR_FAILED" 47 "TEMPERATURE_MONITOR_FAILED" 46 "CAN_TX_FAILED" 45 "CAN_RX_FAILED" 44 "WATCHDOG_FAILED" 43 "LEGACY_FAILED" 42 "VISION_FAILED" 41 "SNAPSHOT_FAILED" 40 "TELEMETRY_FAILED" 39 "TELEMETRY_PACKAGER_FAILED" 30 "UNKNOWN_TASK_FAILED" 0 "NO_TASK_FAILED" ;
VAL_ 2041 DAS_gpsStatusMultiplexer 3 "Mux3" 2 "Mux2" 1 "Mux1" 0 "Mux0" ;
VAL_ 2041 DAS_gpsTransportModeState 1 "DAS_GPS_TRANSPORT_MODE_ON" 0 "DAS_GPS_TRANSPORT_MODE_OFF" ;
VAL_ 2041 DAS_gpsWheelsOffMotionDetected 1 "DAS_GPS_MOTION_DETECTED_ON" 0 "DAS_GPS_MOTION_DETECTED_OFF" ;
VAL_ 2041 DAS_gpsFixTypeHardware 6 "DEAD_RECOCKONING_FIX" 5 "FLOAT_RTK_FIX" 4 "REAL_TIME_KINEMATICS_FIX" 3 "PPS_FIX" 2 "DGPS_FIX" 1 "GPS_FIX" 0 "INVALID_FIX" ;
VAL_ 2041 DAS_gpsFixTypeSoftware 6 "DEAD_RECOCKONING_FIX" 5 "FLOAT_RTK_FIX" 4 "REAL_TIME_KINEMATICS_FIX" 3 "PPS_FIX" 2 "DGPS_FIX" 1 "GPS_FIX" 0 "INVALID_FIX" ;
VAL_ 2041 DAS_gpsJammingState 3 "GPS_JAMMING_STATE_CRITICAL" 2 "GPS_JAMMING_STATE_WARNING" 1 "GPS_JAMMING_STATE_NOMINAL" 0 "GPS_JAMMING_STATE_UNKNOWN" ;
VAL_ 2041 DAS_gpsSpoofDetectorState 3 "GPS_SPOOFING_MULTIPLE_INDICATIONS" 2 "GPS_SPOOFING_INDICATION_PRESENT" 1 "GPS_SPOOFING_NO_ACTIVE_INDICATION" 0 "GPS_SPOOFING_UNKNOWN" ;
VAL_ 2041 DAS_gnssConstellationsState 2 "CONSTELLATIONS_STATE_VALID" 1 "CONSTELLATIONS_STATE_INVALID" 0 "CONSTELLATIONS_STATE_UNKNOWN" ;
VAL_ 2041 DAS_gpsResetReason 13 "GPS_RESET_PPS_MISSING" 12 "GPS_RESET_SOLUTION_INCONSISTENCY" 11 "GPS_RESET_MANUAL_COLD_RESET" 10 "GPS_RESET_GNSS_CFG_CHANGE" 9 "GPS_RESET_RESUME_CONFIGURATION_FAULT" 8 "GPS_RESET_SUSPEND_CONFIGURATION_FAULT" 7 "GPS_RESET_SATELLITE_REJECTION_TIMEOUT" 6 "GPS_RESET_ENTER_TRANSPORT_MODE" 5 "GPS_RESET_EXIT_TRANSPORT_MODE" 4 "GPS_RESET_GNSS_DATA_MISSING" 3 "GPS_RESET_UBX_MISSING" 2 "GPS_RESET_DATA_CORRUPTED" 1 "GPS_RESET_DATA_MISSING" 0 "GPS_RESET_NONE" ;
VAL_ 2041 DAS_gpsToMcuSource 4 "GPS_TO_MCU_SOURCE_BLUEFIN_SOLUTION" 3 "GPS_TO_MCU_SOURCE_TESLA_VIO_SOLUTION" 2 "GPS_TO_MCU_SOURCE_SOFTWARE_SOLUTION" 1 "GPS_TO_MCU_SOURCE_HARDWARE_SOLUTION" 0 "GPS_TO_MCU_SOURCE_UNKNOWN" ;
VAL_ 2041 DAS_gpsSolutionSoc 2 "GPS_SOLUTION_SOC_B" 1 "GPS_SOLUTION_SOC_A" 0 "GPS_SOLUTION_SOC_UNKNOWN" ;
VAL_ 2041 DAS_gpsFixTypeSoftwareSocB 6 "DEAD_RECOCKONING_FIX" 5 "FLOAT_RTK_FIX" 4 "REAL_TIME_KINEMATICS_FIX" 3 "PPS_FIX" 2 "DGPS_FIX" 1 "GPS_FIX" 0 "INVALID_FIX" ;
VAL_ 2041 DAS_gnssNumSatsGps 15 "FIFTEEN_OR_MORE_SATELLITES" ;
VAL_ 2041 DAS_gnssNumSatsGal 15 "FIFTEEN_OR_MORE_SATELLITES" ;
VAL_ 2041 DAS_gnssNumSatsBds 15 "FIFTEEN_OR_MORE_SATELLITES" ;
VAL_ 777 DAS_objectId 5 "VEHICLE_HEADINGS" 4 "ROAD_SIGN" 3 "CUTIN_VEHICLE" 2 "RIGHT_VEHICLES" 1 "LEFT_VEHICLES" 0 "LEAD_VEHICLES" ;
VAL_ 777 DAS_leadVehType 6 "IPSO" 5 "PEDESTRIAN" 4 "BICYCLE" 3 "MOTORCYCLE" 2 "CAR" 1 "TRUCK" 0 "UNKNOWN" ;
VAL_ 777 DAS_leadVehDx 255 "SNA" ;
VAL_ 777 DAS_leadVehVxRel 15 "SNA" ;
VAL_ 777 DAS_leadVehId 127 "SNA" ;
VAL_ 777 DAS_leadVeh2Type 5 "PEDESTRIAN" 4 "BICYCLE" 3 "MOTORCYCLE" 2 "CAR" 1 "TRUCK" 0 "UNKNOWN" ;
VAL_ 777 DAS_leadVeh2Dx 255 "SNA" ;
VAL_ 777 DAS_leadVeh2VxRel 15 "SNA" ;
VAL_ 777 DAS_leadVeh2Id 0 "SNA" ;
VAL_ 777 DAS_leftVehType 5 "PEDESTRIAN" 4 "BICYCLE" 3 "MOTORCYCLE" 2 "CAR" 1 "TRUCK" 0 "UNKNOWN" ;
VAL_ 777 DAS_leftVehDx 255 "SNA" ;
VAL_ 777 DAS_leftVehVxRel 15 "SNA" ;
VAL_ 777 DAS_leftVehId 127 "SNA" ;
VAL_ 777 DAS_leftVeh2Type 5 "PEDESTRIAN" 4 "BICYCLE" 3 "MOTORCYCLE" 2 "CAR" 1 "TRUCK" 0 "UNKNOWN" ;
VAL_ 777 DAS_leftVeh2Dx 255 "SNA" ;
VAL_ 777 DAS_leftVeh2VxRel 15 "SNA" ;
VAL_ 777 DAS_leftVeh2Id 0 "SNA" ;
VAL_ 777 DAS_rightVehType 5 "PEDESTRIAN" 4 "BICYCLE" 3 "MOTORCYCLE" 2 "CAR" 1 "TRUCK" 0 "UNKNOWN" ;
VAL_ 777 DAS_rightVehDx 255 "SNA" ;
VAL_ 777 DAS_rightVehVxRel 15 "SNA" ;
VAL_ 777 DAS_rightVehId 127 "SNA" ;
VAL_ 777 DAS_rightVeh2Type 5 "PEDESTRIAN" 4 "BICYCLE" 3 "MOTORCYCLE" 2 "CAR" 1 "TRUCK" 0 "UNKNOWN" ;
VAL_ 777 DAS_rightVeh2Dx 255 "SNA" ;
VAL_ 777 DAS_rightVeh2VxRel 15 "SNA" ;
VAL_ 777 DAS_rightVeh2Id 0 "SNA" ;
VAL_ 777 DAS_cutinVehType 5 "PEDESTRIAN" 4 "BICYCLE" 3 "MOTORCYCLE" 2 "CAR" 1 "TRUCK" 0 "UNKNOWN" ;
VAL_ 777 DAS_cutinVehDx 255 "SNA" ;
VAL_ 777 DAS_cutinVehVxRel 15 "SNA" ;
VAL_ 777 DAS_cutinVehId 127 "SNA" ;
VAL_ 777 DAS_roadSignColor 4 "RED_YELLOW" 3 "GREEN" 2 "YELLOW" 1 "RED" 0 "NONE" ;
VAL_ 777 DAS_roadSignId 255 "SNA" 1 "TRAFFIC_LIGHT" 0 "STOP_SIGN" ;
VAL_ 777 DAS_roadSignStopLineDist 1023 "SNA" ;
VAL_ 777 DAS_roadSignSource 2 "VISION" 1 "NAV" 0 "NONE" ;
VAL_ 777 DAS_roadSignArrow 4 "UNKNOWN" 3 "STRAIGHT" 2 "RIGHT" 1 "LEFT" 0 "CIRCLE" ;
VAL_ 777 DAS_roadSignOrientation 2 "HORIZONTAL_3_LIGHT" 1 "VERTICAL_3_LIGHT" 0 "UNKNOWN" ;
VAL_ 1548 DAS_TR_ObjIndex 31 "Mux31" 30 "Mux30" 29 "Mux29" 28 "Mux28" 27 "Mux27" 26 "Mux26" 25 "Mux25" 24 "Mux24" 23 "Mux23" 22 "Mux22" 21 "Mux21" 20 "Mux20" 19 "Mux19" 18 "Mux18" 17 "Mux17" 16 "Mux16" 15 "Mux15" 14 "Mux14" 13 "Mux13" 12 "Mux12" 11 "Mux11" 10 "Mux10" 9 "Mux9" 8 "Mux8" 7 "Mux7" 6 "Mux6" 5 "Mux5" 4 "Mux4" 3 "Mux3" 2 "Mux2" 1 "Mux1" 0 "Mux0" ;
VAL_ 1548 DAS_TR_Obj00_Class 4 "RADAR_CLASS_CONSTRUCTION_ELEMENT" 3 "RADAR_CLASS_MOVING_PEDESTRIAN" 2 "RADAR_CLASS_MOVING_TWO_WHEEL_VEHICLE" 1 "RADAR_CLASS_MOVING_FOUR_WHEEL_VEHICLE" 0 "RADAR_CLASS_UNKNOWN" ;
VAL_ 1548 DAS_TR_Obj00_MovingState 3 "RADAR_MOVESTATE_STANDING" 2 "RADAR_MOVESTATE_STOPPED" 1 "RADAR_MOVESTATE_MOVING" 0 "RADAR_MOVESTATE_INDETERMINATE" ;
VAL_ 1318 DIF_alertID 255 "a255_currentGainFallback" 254 "a254_activeDischargeRail" 253 "a253_lvBoostedRail" 252 "a252_currentCoreFallback" 251 "a251_oilPumpService" 250 "a250_preregulatorRail" 249 "a249_highStatorTempFromResist" 247 "a247_rotorOffsetError" 246 "a246_recoveryAtSpeedError" 245 "a245_mechSafeStatePreWarn" 244 "a244_mechSafeStateApplied" 243 "a243_ecuLogAvailable" 242 "a242_spinDownLearning" 241 "a241_systemThermallyLimited" 236 "a236_tasMIA" 234 "a234_pcsMIA" 233 "a233_diMsgMissed" 231 "a231_unintendedReset2" 225 "a225_tmpEstPlausibility" 202 "a202_excessHeatUnavailable" 177 "a177_fluxReferenceCorrected" 176 "a176_safetyICFault" 174 "a174_unitMayNotRestart" 162 "a162_endOfLifetimeBurnIn" 161 "a161_epas3pMIA" 160 "a160_busVoltageAnomaly" 158 "a158_ibstMIA" 157 "a157_rcmMIA" 156 "a156_currentObserver" 155 "a155_vcfrontMIA" 154 "a154_resolver" 153 "a153_oilPumpDiagnostics" 152 "a152_linError" 151 "a151_shockTorqueLimiter" 150 "a150_busVD" 149 "a149_oilPumpFailure" 148 "a148_burnInCycleEnded" 147 "a147_highTorqueWearLimit" 144 "a144_configMismatch" 142 "a142_highLashAngle" 136 "a136_spiError" 134 "a134_wheelSpeedIrrational" 133 "a133_capacitorOT" 128 "a128_fpgaVersionMismatch" 127 "a127_gracefulPowerOff" 126 "a126_limpMode" 123 "a123_lossMotorControl" 122 "a122_highStackUsage" 121 "a121_motorControlRegulation" 120 "a120_hvlinkMIA" 119 "a119_hvpMIA" 117 "a117_diMIA" 116 "a116_highSpeedWearCounter" 115 "a115_exceptionDataAbort2" 114 "a114_exceptionDataAbort" 113 "a113_noFuncHeatsinkSensor" 112 "a112_noPhaseCurrent" 111 "a111_badPhaseSensorCalib" 110 "a110_brakeMIA" 109 "a109_ahbWriteError" 108 "a108_stateTrans" 107 "a107_fpgaError" 103 "a103_lowFlow" 102 "a102_exceptionPrefetchAbort" 101 "a101_eccTestData1" 100 "a100_assertion" 99 "a099_threadOverrun" 98 "a098_intTimeTooLong" 97 "a097_eepromError" 96 "a096_memoryError" 95 "a095_canOverrunBusA" 94 "a094_canDataBusA" 93 "a093_canHardwareBusA" 92 "a092_bmsMIA" 91 "a091_espMIA" 90 "a090_pmMIA" 88 "a088_uiMIA" 87 "a087_gtwMIA" 86 "a086_activeDischargeOn" 84 "a084_eccTestData0" 83 "a083_PABCD_DIF_ECU_DemoWindow" 82 "a082_P7837_DIF_ECU_DemoTimer" 81 "a081_P0BFF_DIF_EM_CurrentHigh" 79 "a079_adcRefHigh" 78 "a078_adcRefLow" 77 "a077_lvSupplyUV" 76 "a076_lvSupplyOV" 75 "a075_motorSpeedMismatch" 74 "a074_motorEncoder" 73 "a073_motorSpeed" 72 "a072_gateDriveFaultCounter" 71 "a071_busDisconnected" 70 "a070_udsTransactionInitiated" 69 "a069_rotorTempLimit" 67 "a067_canOverrunBusB" 66 "a066_canDataBusB" 65 "a065_canHardwareBusB" 64 "a064_torqueIntervention" 63 "a063_bbMIA" 62 "a062_systemLimpMode" 61 "a061_heatsinkSensor" 60 "a060_heatsinkUT" 59 "a059_heatsinkOT" 58 "a058_ambientSensor" 57 "a057_ambientUT" 56 "a056_ambientOT" 55 "a055_trqCrossCheck" 54 "a054_driveInverterOT" 53 "a053_unexpectedLatchState" 52 "a052_dirMIA" 50 "a050_noStatorSensor" 49 "a049_statorSensorDiff" 48 "a048_statorSensor2" 47 "a047_statorSensor1" 46 "a046_statorOT" 45 "a045_outletSensor" 44 "a044_outletUT" 43 "a043_outletOT" 42 "a042_inletSensor" 41 "a041_sdcMIA" 40 "a040_difMIA" 39 "a039_exceptionUndefinedInstruction" 38 "a038_busVsensor" 37 "a037_busUV" 36 "a036_busOV" 35 "a035_phaseCurrentBalance" 34 "a034_phaseBcurrentSensor" 33 "a033_phaseAcurrentSensor" 32 "a032_phaseBcurrentOffset" 31 "a031_phaseAcurrentOffset" 30 "a030_phaseCrms" 29 "a029_phaseBrms" 28 "a028_phaseArms" 27 "a027_phaseCpeak" 26 "a026_phaseBpeak" 25 "a025_phaseApeak" 24 "a024_selfTest" 22 "a022_hw5vSupplyUV" 21 "a021_hwBusOV" 20 "a020_hwMotorEncoder" 18 "a018_hwLVSupplyUV" 17 "a017_hwPedalMonitor" 16 "a016_safeStateApplied" 15 "a015_mechSafeStateAnomaly" 14 "a014_activeDamping" 13 "a013_eccError" 12 "a012_hvilNotClosed" 11 "a011_swPowerStageNotReady" 10 "a010_unintendedReset" 9 "a009_hwEncoderB" 8 "a008_hwEncoderA" 7 "a007_statorAnomalyDetected" 6 "a006_hwPhaseCpeak" 5 "a005_hwPhaseBpeak" 4 "a004_hwPhaseApeak" 3 "a003_hwPhaseCgateDrive" 2 "a002_hwPhaseBgateDrive" 1 "a001_hwPhaseAgateDrive" 0 "ALERT_DO_NOT_USE_ZERO" ;
VAL_ 1318 DIF_alertState 1 "SET" 0 "CLEARED" ;
VAL_ 1318 DIF_a011_reason 4 "SPI_ERROR" 3 "FAULT_DURING_CONFIG" 2 "CRC_MISMATCH" 1 "REG_DATA_MISMATCH" 0 "GATE_DRIVE_SUPPLY" ;
VAL_ 1318 DIF_a012_hvilStatus 3 "SNA" 2 "CLOSED" 1 "OPEN" 0 "DISABLED" ;
VAL_ 1318 DIF_a013_errorType 12 "RAM_CORRECTABLE_DMA" 11 "RAM_CORRECTABLE_CLA" 10 "RAM_CORRECTABLE_CPU" 9 "RAM_UNCORRECTABLE_DMA" 8 "RAM_UNCORRECTABLE_CLA" 7 "RAM_UNCORRECTABLE_CPU" 6 "FLASH_FAIL1_HIGH" 5 "FLASH_FAIL1_LOW" 4 "FLASH_FAIL0_HIGH" 3 "FLASH_FAIL0_LOW" 2 "FLASH_UNCORRECTABLE_HIGH" 1 "FLASH_UNCORRECTABLE_LOW" 0 "UNKNOWN" ;
VAL_ 1318 DIF_a014_adState 3 "FAULTED" 2 "BACKUP" 1 "NORMAL" 0 "STARTUP" ;
VAL_ 1318 DIF_a016_newSafeState 3 "3PS_LOW" 2 "3PS_HIGH" 1 "ALL_OFF" 0 "NONE" ;
VAL_ 1318 DIF_a016_oldSafeState 3 "3PS_LOW" 2 "3PS_HIGH" 1 "ALL_OFF" 0 "NONE" ;
VAL_ 1318 DIF_a016_triggerEvent 23 "AT_SPEED_RECOVERY" 22 "CURRENT_OBSERVER" 21 "MECHSS_CALLBACK" 20 "3PS_FEEDBACK" 19 "SWITCH_OFF_PATH_TRIP" 18 "BUS_ANOMALY" 17 "GDIC_FAULT" 16 "SELFTEST_FAIL" 15 "CLEAR_FUSES" 14 "SPEED_INVALID" 13 "BUS_UV" 12 "BUS_IRRATIONAL" 11 "BUS_OV" 10 "PEAK_CURRENT" 9 "NO_CURRENT" 8 "IRRATIONAL_CURRENT_DELTA_PHASEB" 7 "IRRATIONAL_CURRENT_DELTA_PHASEA" 6 "IRRATIONAL_CURRENT_VREF" 5 "IRRATIONAL_CURRENT_PHASEB" 4 "IRRATIONAL_CURRENT_PHASEA" 3 "RESOLVER" 2 "MOTOR_SPEED" 1 "LV_SUPPLY_UV" 0 "UNKNOWN" ;
VAL_ 1318 DIF_a024_failReason 7 "ASC_TEST" 6 "FAULT_PRESENT" 5 "GATE_DRIVE_ERROR" 4 "TIMEDOUT" 3 "DISAGREE" 2 "NEG_CURRENT" 1 "POS_CURRENT" 0 "CACHED" ;
VAL_ 1318 DIF_a024_state 12 "TEST_RESTART" 11 "TEST_FAILED" 10 "TEST_SKIPPED" 9 "TEST_PASSED" 8 "TEST_PRE_PASSED" 7 "CURRENT_TEST_NEG" 6 "CURRENT_TEST_POS" 5 "PWM_ENABLE" 4 "ASC_TEST_PASSED" 3 "ASC_TEST" 2 "PSTG_BRING_UP_AT_SPEED" 1 "PSTG_BRING_UP" 0 "INIT" ;
VAL_ 1318 DIF_a038_reason 2 "DI_BMS_VOLTAGE_MISMATCH" 1 "UNDERVOLTAGE_HV_UP" 0 "UNDERVOLTAGE_PRE_CHARGE" ;
VAL_ 1318 DIF_a055_torqueType 2 "PEDAL_POSITION" 1 "TORQUE_COMMAND" 0 "TORQUE_ESTIMATE" ;
VAL_ 1318 DIF_a061_sensor 2 "PH3" 1 "PH2" 0 "PH1" ;
VAL_ 1318 DIF_a061_reason 1 "RAILED" 0 "RATE_OF_CHANGE" ;
VAL_ 1318 DIF_a062_limpReason 42 "DEGRADED_REQUEST_VCRIGHT" 41 "DEGRADED_REQUEST_VCLEFT" 40 "DEGRADED_REQUEST_PEPS" 39 "DEGRADED_REQUEST_SEPS" 38 "DEGRADED_REQUEST_PSFA" 37 "DEGRADED_REQUEST_SSFA" 36 "XTAL_OSCILLATOR" 35 "CURRENT_CORE_FALLBACK" 34 "MECHANICAL_SAFE_ST_UNAVAIL" 33 "MOTION_IN_DYNO" 32 "RESIST_STATOR_TEMP" 31 "OIL_PRESSURE_LOW" 30 "HEATSINK_SENSOR_IRRATIONAL" 29 "OIL_PUMP_FLUID_OVERTEMP" 28 "OIL_PUMP_FAILURE" 27 "FACTORY_GLIDER" 26 "SLAVE_MIA" 25 "SLAVE_REQUEST" 24 "CONTACTOR_WELD" 23 "CAPACITOR_OVERTEMP" 22 "GTW_MIA" 21 "TRQCMD_VALIDITY_UNKNOWN" 20 "DI_MIA" 19 "CONFIG_MISMATCH" 18 "HEATSINK_TEMP" 17 "PMREQUEST" 16 "PMHEARTBEAT" 15 "TRQ_CROSS_CHECK" 14 "EXTERNAL_COMMAND" 13 "WRONG_CS_CALIBRATION" 12 "STATOR_TEMP" 11 "DELTAT_TOO_NEGATIVE" 10 "DELTAT_TOO_POSITIVE" 9 "AMBIENT_TEMP" 8 "OUTLET_TEMP" 7 "LOW_FLOW" 6 "BMS_MIA" 5 "LV_SUPPLY_UNDERVOLTAGE" 4 "NO_FLUID" 3 "NO_FUNC_HEATSINK_SENSOR" 2 "NO_FUNC_STATORT_SENSOR" 1 "BUSV_SENSOR_IRRATIONAL" 0 "PHASE_IMBALANCE" ;
VAL_ 1318 DIF_a064_interventionType 15 "excessiveMotorMz" 14 "inconsistentAxleTorque" 13 "diHeartbeat" 12 "currentAfterIntervention" 11 "switchingAfterIntervention" 10 "switchOffPathTestFail" 9 "inconsistentTorqueSign" 8 "torqueInNeutral" 7 "excessiveRegenTorque" 6 "torqueReversal" 5 "accumulatedTorque" 4 "motorMovementDetected" 3 "cruiseFault" 2 "torqueCmdInvalid" 1 "resolver" 0 "masterTorqueMonitorShutoff" ;
VAL_ 1318 DIF_a064_torqueCmdState 8 "Invalid" 6 "Valid" 0 "SNA" ;
VAL_ 1318 DIF_a066_canID 2047 "GTW_carConfig" 1910 "XCP_difRequest" 1541 "UDS_difRequest" 1320 "GTW_time" 1280 "UI_debugECU" 950 "DI_odometerStatus" 914 "BMS_packConfig" 820 "UI_powertrainControl" 801 "VCFRONT_sensors" 792 "GTW_carState" 744 "EPBR_status" 680 "EPBL_status" 662 "UI_chassisControlDebug" 659 "UI_chassisControl" 644 "UI_vehicleModes" 577 "VCFRONT_coolant" 548 "PCS_dcdcStatus" 545 "VCFRONT_LVPowerState" 530 "BMS_status" 469 "PMF_state4" 306 "BMS_hvBusStatus" ;
VAL_ 1318 DIF_a066_errorType 6 "UNKNOWN_ID" 5 "DATA_INVALID" 4 "SEQUENCE" 3 "CHECKSUM" 2 "LENGTH_LONG" 1 "LENGTH_SHORT" 0 "NONE" ;
VAL_ 1318 DIF_a072_reason 3 "SWITCH_SHORT_TEST" 2 "MECHSS" 1 "EXTERNAL_OSCILLATOR" 0 "DEFAULT" ;
VAL_ 1318 DIF_a090_reason 1 "TOOFAST" 0 "TOOSLOW" ;
VAL_ 1318 DIF_a094_canID 2047 "GTW_carConfig" 1910 "XCP_difRequest" 1541 "UDS_difRequest" 1320 "GTW_time" 1280 "UI_debugECU" 950 "DI_odometerStatus" 914 "BMS_packConfig" 820 "UI_powertrainControl" 801 "VCFRONT_sensors" 792 "GTW_carState" 744 "EPBR_status" 680 "EPBL_status" 662 "UI_chassisControlDebug" 659 "UI_chassisControl" 644 "UI_vehicleModes" 577 "VCFRONT_coolant" 548 "PCS_dcdcStatus" 545 "VCFRONT_LVPowerState" 530 "BMS_status" 469 "PMF_state4" 306 "BMS_hvBusStatus" ;
VAL_ 1318 DIF_a094_errorType 6 "UNKNOWN_ID" 5 "DATA_INVALID" 4 "SEQUENCE" 3 "CHECKSUM" 2 "LENGTH_LONG" 1 "LENGTH_SHORT" 0 "NONE" ;
VAL_ 1318 DIF_a097_errorType 6 "DPOT_WRITE" 5 "DPOT_READ" 4 "LOST" 3 "CRC" 2 "WRITE" 1 "READ" 0 "OPEN" ;
VAL_ 1318 DIF_a098_fluxState 10 "STATIONARY_WASTE" 9 "FAULT" 7 "VCONTROL" 6 "ICONTROL" 5 "ENABLED" 4 "FLUX_DOWN" 3 "FLUX_UP" 2 "STANDBY" 1 "TEST" 0 "START" ;
VAL_ 1318 DIF_a108_blockingAlert 255 "a255_currentGainFallback" 254 "a254_activeDischargeRail" 253 "a253_lvBoostedRail" 252 "a252_currentCoreFallback" 251 "a251_oilPumpService" 250 "a250_preregulatorRail" 249 "a249_highStatorTempFromResist" 247 "a247_rotorOffsetError" 246 "a246_recoveryAtSpeedError" 245 "a245_mechSafeStatePreWarn" 244 "a244_mechSafeStateApplied" 243 "a243_ecuLogAvailable" 242 "a242_spinDownLearning" 241 "a241_systemThermallyLimited" 236 "a236_tasMIA" 234 "a234_pcsMIA" 233 "a233_diMsgMissed" 231 "a231_unintendedReset2" 225 "a225_tmpEstPlausibility" 202 "a202_excessHeatUnavailable" 177 "a177_fluxReferenceCorrected" 176 "a176_safetyICFault" 174 "a174_unitMayNotRestart" 162 "a162_endOfLifetimeBurnIn" 161 "a161_epas3pMIA" 160 "a160_busVoltageAnomaly" 158 "a158_ibstMIA" 157 "a157_rcmMIA" 156 "a156_currentObserver" 155 "a155_vcfrontMIA" 154 "a154_resolver" 153 "a153_oilPumpDiagnostics" 152 "a152_linError" 151 "a151_shockTorqueLimiter" 150 "a150_busVD" 149 "a149_oilPumpFailure" 148 "a148_burnInCycleEnded" 147 "a147_highTorqueWearLimit" 144 "a144_configMismatch" 142 "a142_highLashAngle" 136 "a136_spiError" 134 "a134_wheelSpeedIrrational" 133 "a133_capacitorOT" 128 "a128_fpgaVersionMismatch" 127 "a127_gracefulPowerOff" 126 "a126_limpMode" 123 "a123_lossMotorControl" 122 "a122_highStackUsage" 121 "a121_motorControlRegulation" 120 "a120_hvlinkMIA" 119 "a119_hvpMIA" 117 "a117_diMIA" 116 "a116_highSpeedWearCounter" 115 "a115_exceptionDataAbort2" 114 "a114_exceptionDataAbort" 113 "a113_noFuncHeatsinkSensor" 112 "a112_noPhaseCurrent" 111 "a111_badPhaseSensorCalib" 110 "a110_brakeMIA" 109 "a109_ahbWriteError" 108 "a108_stateTrans" 107 "a107_fpgaError" 103 "a103_lowFlow" 102 "a102_exceptionPrefetchAbort" 101 "a101_eccTestData1" 100 "a100_assertion" 99 "a099_threadOverrun" 98 "a098_intTimeTooLong" 97 "a097_eepromError" 96 "a096_memoryError" 95 "a095_canOverrunBusA" 94 "a094_canDataBusA" 93 "a093_canHardwareBusA" 92 "a092_bmsMIA" 91 "a091_espMIA" 90 "a090_pmMIA" 88 "a088_uiMIA" 87 "a087_gtwMIA" 86 "a086_activeDischargeOn" 84 "a084_eccTestData0" 83 "a083_PABCD_DIF_ECU_DemoWindow" 82 "a082_P7837_DIF_ECU_DemoTimer" 81 "a081_P0BFF_DIF_EM_CurrentHigh" 79 "a079_adcRefHigh" 78 "a078_adcRefLow" 77 "a077_lvSupplyUV" 76 "a076_lvSupplyOV" 75 "a075_motorSpeedMismatch" 74 "a074_motorEncoder" 73 "a073_motorSpeed" 72 "a072_gateDriveFaultCounter" 71 "a071_busDisconnected" 70 "a070_udsTransactionInitiated" 69 "a069_rotorTempLimit" 67 "a067_canOverrunBusB" 66 "a066_canDataBusB" 65 "a065_canHardwareBusB" 64 "a064_torqueIntervention" 63 "a063_bbMIA" 62 "a062_systemLimpMode" 61 "a061_heatsinkSensor" 60 "a060_heatsinkUT" 59 "a059_heatsinkOT" 58 "a058_ambientSensor" 57 "a057_ambientUT" 56 "a056_ambientOT" 55 "a055_trqCrossCheck" 54 "a054_driveInverterOT" 53 "a053_unexpectedLatchState" 52 "a052_dirMIA" 50 "a050_noStatorSensor" 49 "a049_statorSensorDiff" 48 "a048_statorSensor2" 47 "a047_statorSensor1" 46 "a046_statorOT" 45 "a045_outletSensor" 44 "a044_outletUT" 43 "a043_outletOT" 42 "a042_inletSensor" 41 "a041_sdcMIA" 40 "a040_difMIA" 39 "a039_exceptionUndefinedInstruction" 38 "a038_busVsensor" 37 "a037_busUV" 36 "a036_busOV" 35 "a035_phaseCurrentBalance" 34 "a034_phaseBcurrentSensor" 33 "a033_phaseAcurrentSensor" 32 "a032_phaseBcurrentOffset" 31 "a031_phaseAcurrentOffset" 30 "a030_phaseCrms" 29 "a029_phaseBrms" 28 "a028_phaseArms" 27 "a027_phaseCpeak" 26 "a026_phaseBpeak" 25 "a025_phaseApeak" 24 "a024_selfTest" 22 "a022_hw5vSupplyUV" 21 "a021_hwBusOV" 20 "a020_hwMotorEncoder" 18 "a018_hwLVSupplyUV" 17 "a017_hwPedalMonitor" 16 "a016_safeStateApplied" 15 "a015_mechSafeStateAnomaly" 14 "a014_activeDamping" 13 "a013_eccError" 12 "a012_hvilNotClosed" 11 "a011_swPowerStageNotReady" 10 "a010_unintendedReset" 9 "a009_hwEncoderB" 8 "a008_hwEncoderA" 7 "a007_statorAnomalyDetected" 6 "a006_hwPhaseCpeak" 5 "a005_hwPhaseBpeak" 4 "a004_hwPhaseApeak" 3 "a003_hwPhaseCgateDrive" 2 "a002_hwPhaseBgateDrive" 1 "a001_hwPhaseAgateDrive" 0 "ALERT_DO_NOT_USE_ZERO" ;
VAL_ 1318 DIF_a121_badRegReason 5 "TORQUE_OFF_TARGET" 4 "FLUX_OFF_TARGET" 3 "IQ_OFF_TARGET" 2 "ID_OFF_TARGET" 1 "RMS_I_HIGH" ;
VAL_ 1318 DIF_a123_lossReason 4 "HIGH_FLUX_DISTURBANCE" 3 "HIGH_VAR_CURR" 2 "HIGH_VAR_FLUX" 1 "NO_FLUX_UP" ;
VAL_ 1318 DIF_a126_limpReason 42 "DEGRADED_REQUEST_VCRIGHT" 41 "DEGRADED_REQUEST_VCLEFT" 40 "DEGRADED_REQUEST_PEPS" 39 "DEGRADED_REQUEST_SEPS" 38 "DEGRADED_REQUEST_PSFA" 37 "DEGRADED_REQUEST_SSFA" 36 "XTAL_OSCILLATOR" 35 "CURRENT_CORE_FALLBACK" 34 "MECHANICAL_SAFE_ST_UNAVAIL" 33 "MOTION_IN_DYNO" 32 "RESIST_STATOR_TEMP" 31 "OIL_PRESSURE_LOW" 30 "HEATSINK_SENSOR_IRRATIONAL" 29 "OIL_PUMP_FLUID_OVERTEMP" 28 "OIL_PUMP_FAILURE" 27 "FACTORY_GLIDER" 26 "SLAVE_MIA" 25 "SLAVE_REQUEST" 24 "CONTACTOR_WELD" 23 "CAPACITOR_OVERTEMP" 22 "GTW_MIA" 21 "TRQCMD_VALIDITY_UNKNOWN" 20 "DI_MIA" 19 "CONFIG_MISMATCH" 18 "HEATSINK_TEMP" 17 "PMREQUEST" 16 "PMHEARTBEAT" 15 "TRQ_CROSS_CHECK" 14 "EXTERNAL_COMMAND" 13 "WRONG_CS_CALIBRATION" 12 "STATOR_TEMP" 11 "DELTAT_TOO_NEGATIVE" 10 "DELTAT_TOO_POSITIVE" 9 "AMBIENT_TEMP" 8 "OUTLET_TEMP" 7 "LOW_FLOW" 6 "BMS_MIA" 5 "LV_SUPPLY_UNDERVOLTAGE" 4 "NO_FLUID" 3 "NO_FUNC_HEATSINK_SENSOR" 2 "NO_FUNC_STATORT_SENSOR" 1 "BUSV_SENSOR_IRRATIONAL" 0 "PHASE_IMBALANCE" ;
VAL_ 1318 DIF_a127_gpoReason 14 "MOTION_EXPECTED_DURING_SPINDOWN_LEARNING" 13 "FACTORY_DRIVE_DISTANCE_EXCEEDED" 12 "DEGRADED_LIMP_NO_DECEL" 11 "DEGRADED_LIMP_TIMEOUT" 10 "SBW_NODE_UNAVAILABLE" 9 "MOTION_DURING_SPINDOWN_LEARNING" 8 "MOTOR_HALT_REQUEST" 7 "CAPACITOR_OVERTEMP" 6 "NOT_ENOUGH_12V" 5 "NO_BATTERY_POWER" 4 "AMBIENT_OVERTEMP" 3 "FLUID_DELTAT" 2 "STATOR_OVERTEMP" 1 "HEATSINK_OVERTEMP" 0 "OUTLET_OVERTEMP" ;
VAL_ 1318 DIF_a149_flow 255 "SNA" ;
VAL_ 1318 DIF_a149_state 7 "SNA" 6 "FAULTED" 2 "COLD_STARTUP" 1 "ENABLE" 0 "STANDBY" ;
VAL_ 1318 DIF_a149_pcbaID 1 "5" 0 "LESS_THAN_5" ;
VAL_ 1318 DIF_a152_errorType 6 "TIMEOUT_ERROR" 5 "HEADER_ERROR" 4 "OVERFLOW_ERROR" 3 "SCHEDULE_ERROR" 2 "CHECKSUM_ERROR" 1 "FRAMING_ERROR" 0 "NO_ERROR" ;
VAL_ 1318 DIF_a153_oilFlow 255 "SNA" ;
VAL_ 1318 DIF_a153_oilTemperature 255 "SNA" ;
VAL_ 1318 DIF_a153_phaseCurrent 255 "SNA" ;
VAL_ 1318 DIF_a153_dcVoltage 255 "SNA" ;
VAL_ 1318 DIF_a153_state 7 "SNA" 6 "FAULTED" 2 "COLD_STARTUP" 1 "ENABLE" 0 "STANDBY" ;
VAL_ 1318 DIF_a153_oilPumpAlert 28 "A028_PHASE_CURRENT_IRRATIONAL" 27 "A027_FLUID_PRESSURE_CHECK" 26 "A026_FLUID_PRESSURE_VERY_LOW" 25 "A025_MOTOR_CONTROL" 24 "A024_MEMORY_ERROR" 23 "A023_SPI_ERROR" 22 "A022_MOTOR_STALL" 21 "A021_MOTOR_OVERLOAD" 20 "A020_FLUID_TEMP_IRRAT" 19 "A019_FLUID_PRESS_IRRAT" 18 "A018_FLUID_PRESS_HIGH" 17 "A017_FLUID_PRESS_LOW" 16 "A016_PUMP_TEMP_IRRAT" 15 "A015_PUMP_OVERTEMP" 14 "A014_MOTOR_SPEED_IRRAT" 13 "A013_MOTOR_SPEED_TOO_HIGH" 12 "A012_MOTOR_SPEED_NEG" 11 "A011_MOTOR_CURRENT_IRRAT" 10 "A010_MOTOR_OPEN_PHASE" 9 "A009_MOTOR_SHORTED" 8 "A008_SUPPLY_IRRAT" 7 "A007_SUPPLY_OV" 6 "A006_SUPPLY_UV" 5 "A005_LIN_ID_PARITY_ERR" 4 "A004_LIN_FRAMING_ERR" 3 "A003_LIN_CHECKSUM_ERR" 2 "A002_LIN_DATA_ERR" 1 "A001_ECU_RESET" 0 "A000_NONE" ;
VAL_ 1318 DIF_a153_reason 5 "PRESS_HIGH" 4 "PRESS_LOW" 3 "PRESS_9LPM_OK" 2 "PRESS_6LPM_OK" 1 "OPC_ALERT" 0 "NONE" ;
VAL_ 1318 DIF_a202_reason 12 "HV_DOWN" 11 "CRUISE" 10 "OPD" 9 "DRV_FAULT" 8 "IMMEDIATE" 7 "SERVICE_MODE" 6 "UPDATE_STARTED" 5 "GPO" 4 "LIMP" 3 "MOVEMENT" 2 "PARKBRAKE" 1 "NO_ALERT" 0 "NONE" ;
VAL_ 1318 DIF_a202_sysStateExitCondition 19 "IDLE_TRUNK_OPEN" 18 "UNAVAILABLE_EXIT_OK" 17 "UNAVAILABLE_UNITS_NOT_AVAILABLE" 16 "UNAVAILABLE_SSPD_SPEED_IS_NOT_PUBLISHED" 15 "UNAVAILABLE_ALERTS_ACTIVE" 14 "UNAVAILABLE_HV_IS_NOT_UP" 13 "UNAVAILABLE_SLIM_GPO_OR_CAN_DRIVE_GOING_DOWN" 12 "IDLE_EXIT_OK" 11 "IDLE_FIRMWARE_VERIFICATION" 10 "IDLE_BATTERY_POWER_LIMITS" 9 "IDLE_NON_ZERO_PEDAL_POS" 8 "IDLE_FALCON_DOOR_OPEN" 7 "IDLE_PROX_DETECTED" 6 "IDLE_FRUNK_NOT_LATCHED" 5 "IDLE_IMMOBILIZER_INHIBIT" 4 "IDLE_HV_NOT_UP_FOR_DRIVE" 3 "IDLE_LV_OR_SBW_STATUS_LIMP" 2 "IDLE_LV_OR_SBW_STATUS_NOT_READY" 1 "IDLE_DRIVE_RAIL_NOT_REQUESTED" 0 "IDLE_VEHICLE_POWER_STATE_NOT_DRIVE" ;
VAL_ 1318 DIF_a246_codeBranch 3 "SAFESTATE_RELEASE_LATCH" 2 "SAFESTATE_RELEASE_ASC" 1 "PSTG_INIT" 0 "QUALIFICATION" ;
VAL_ 1318 DIF_a251_oilFlow 255 "SNA" ;
VAL_ 1318 DIF_a251_oilTemperature 255 "SNA" ;
VAL_ 1318 DIF_a251_dcVoltage 255 "SNA" ;
VAL_ 1318 DIF_a251_dcCurrent 255 "SNA" ;
VAL_ 1318 DIF_a251_phaseCurrent 255 "SNA" ;
VAL_ 1318 DIF_a251_reason 4 "INSUFFICIENT_FLOW" 3 "CURRENT_SENSOR" 2 "PRESSURE_HIGH" 1 "PRESSURE_LOW" 0 "NONE" ;
